VERSION "12.2.7"

NS_ :

BS_:

BU_: ACM ADAS_Body APM ASU_Gateway BCM BCM_BPM CCU_F CCU_R DUMMY_BCM_BPM ETG LDM_L LDM_R OCS_P PSM_D SRR_RR_M SHVU_F SHVU_R TRM USS_F USS_R XGW_Body

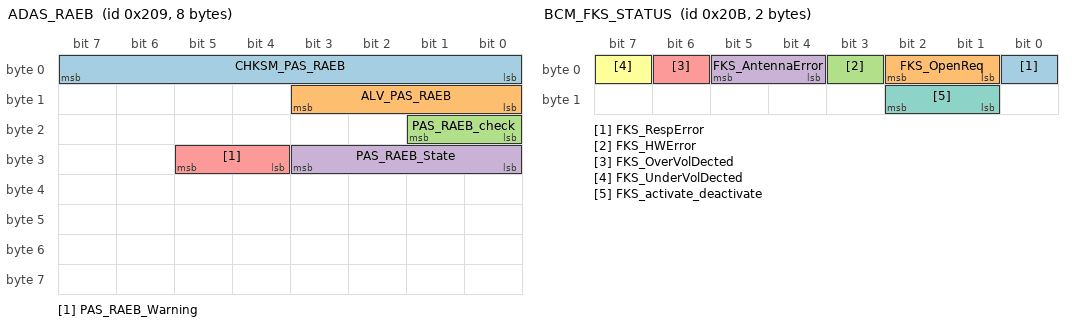
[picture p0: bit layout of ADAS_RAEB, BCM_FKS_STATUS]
BO_ 521 ADAS_RAEB: 8 XGW_Body
 SG_ CHKSM_PAS_RAEB : 7|8@0+ (1,0) [0|255] ""  ACM
 SG_ ALV_PAS_RAEB : 11|4@0+ (1,0) [0|14] ""  ACM
 SG_ PAS_RAEB_check : 17|2@0+ (1,0) [0|3] ""  ACM
 SG_ PAS_RAEB_State : 27|4@0+ (1,0) [0|15] ""  ACM
 SG_ PAS_RAEB_Warning : 29|2@0+ (1,0) [0|3] ""  ACM

BO_ 522 ETG_STATUS: 8 ETG
 SG_ ETG_Lift_Gate_Status : 2|3@0+ (1,0) [0|7] "-"  BCM,XGW_Body
 SG_ ETG_Power_Latch_Status : 5|3@0+ (1,0) [0|7] "-"  BCM,XGW_Body
 SG_ ETG_Latch_Segment : 7|2@0+ (1,0) [0|3] ""  BCM,XGW_Body
 SG_ ETG_Opening_Percentage : 15|8@0+ (1,0) [0|100] "%"  BCM,XGW_Body
 SG_ ETG_DSW_Status : 16|1@0+ (1,0) [0|1] ""  BCM,XGW_Body
 SG_ ETG_GSW_Status : 17|1@0+ (1,0) [0|1] ""  BCM,XGW_Body
 SG_ ETG_LTS_Status : 18|1@0+ (1,0) [0|1] "-"  BCM,XGW_Body
 SG_ ETG_RTS_Status : 19|1@0+ (1,0) [0|1] "-"  BCM,XGW_Body
 SG_ ETG_HAL_Status : 20|1@0+ (1,0) [0|1] "-"  BCM,XGW_Body
 SG_ ETG_FUL_Status : 21|1@0+ (1,0) [0|1] "-"  BCM,XGW_Body
 SG_ ETG_AJR_Status : 22|1@0+ (1,0) [0|1] ""  BCM,XGW_Body
 SG_ ETG_NTL_Status : 23|1@0+ (1,0) [0|1] "-"  BCM,XGW_Body
 SG_ ETG_ERR_Voltage : 25|2@0+ (1,0) [0|3] "-"  BCM,XGW_Body
 SG_ ETG_ERR_Left_Motor : 27|2@0+ (1,0) [0|3] ""  BCM,XGW_Body
 SG_ ETG_ERR_Right_Motor : 29|2@0+ (1,0) [0|3] "-"  BCM,XGW_Body
 SG_ ETG_ERR_Latch : 31|2@0+ (1,0) [0|3] "-"  BCM,XGW_Body
 SG_ ETG_ERR_Hall : 33|2@0+ (1,0) [0|3] ""  BCM,XGW_Body
 SG_ ETG_Lift_Motor_Stall : 34|1@0+ (1,0) [0|1] ""  BCM,XGW_Body
 SG_ ETG_Lift_Motor_AntiPinch : 35|1@0+ (1,0) [0|1] "-"  BCM,XGW_Body
 SG_ ETG_Lift_Motor_Thermal : 36|1@0+ (1,0) [0|1] ""  BCM,XGW_Body
 SG_ ETG_Power_Latch_Thermal : 37|1@0+ (1,0) [0|1] "-"  BCM,XGW_Body
 SG_ ETG_Abuse_Protection : 38|1@0+ (1,0) [0|1] ""  BCM,XGW_Body

BO_ 523 BCM_FKS_STATUS: 2 BCM
 SG_ FKS_RespError : 0|1@0+ (1,0) [0|1] "-"  XGW_Body
 SG_ FKS_OpenReq : 2|2@0+ (1,0) [0|3] ""  XGW_Body
 SG_ FKS_HWError : 3|1@0+ (1,0) [0|1] "-"  XGW_Body
 SG_ FKS_AntennaError : 5|2@0+ (1,0) [0|3] "-"  XGW_Body
 SG_ FKS_OverVolDected : 6|1@0+ (1,0) [0|1] "-"  XGW_Body
 SG_ FKS_UnderVolDected : 7|1@0+ (1,0) [0|1] "-"  XGW_Body
 SG_ FKS_activate_deactivate : 10|2@0+ (1,0) [0|3] "-"  XGW_Body

BO_ 524 IC_ODO: 8 XGW_Body
 SG_ CHKSM_IC_ODO : 7|8@0+ (1,0) [0|255] ""  ACM,ASU_Gateway,BCM,CCU_R,LDM_L,LDM_R,OCS_P,PSM_D,SHVU_F,SHVU_R,USS_F,USS_R
 SG_ ALIV_IC_ODO : 11|4@0+ (1,0) [0|14] ""  ACM,ASU_Gateway,BCM,CCU_R,LDM_L,LDM_R,OCS_P,PSM_D,SHVU_F,SHVU_R,USS_F,USS_R
 SG_ MHU_Odometer_IC : 23|20@0+ (1,0) [0|999999] "km"  ACM,ASU_Gateway,BCM,CCU_R,LDM_L,LDM_R,OCS_P,PSM_D,SHVU_F,SHVU_R,SRR_RR_M,USS_F,USS_R

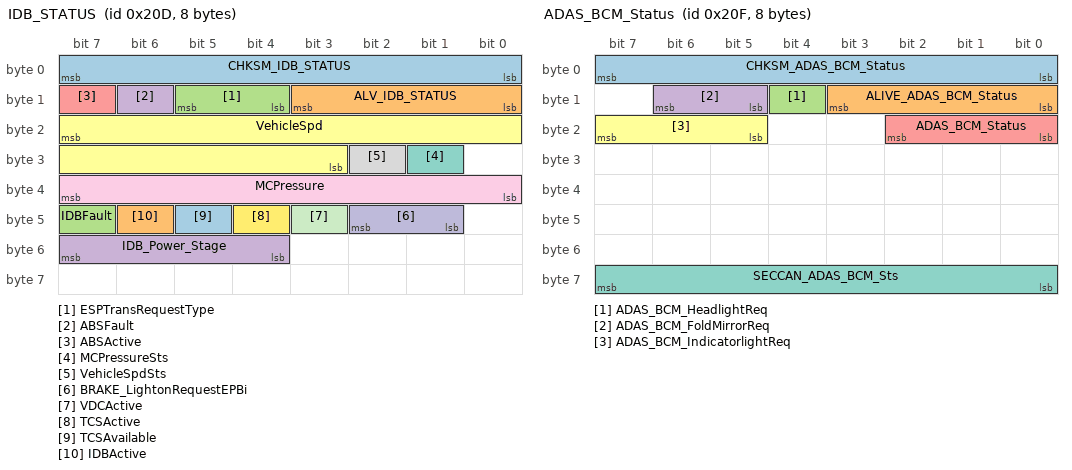
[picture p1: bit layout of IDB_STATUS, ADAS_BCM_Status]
BO_ 525 IDB_STATUS: 8 XGW_Body
 SG_ CHKSM_IDB_STATUS : 7|8@0+ (1,0) [0|255] ""  ACM,APM,ASU_Gateway,BCM,CCU_F,CCU_R,ETG,LDM_L,LDM_R,OCS_P,PSM_D,SHVU_F,SHVU_R,SRR_RR_M,TRM,USS_F,USS_R
 SG_ ALV_IDB_STATUS : 11|4@0+ (1,0) [0|14] ""  ACM,APM,ASU_Gateway,BCM,CCU_F,CCU_R,ETG,LDM_L,LDM_R,OCS_P,PSM_D,SHVU_F,SHVU_R,SRR_RR_M,TRM,USS_F,USS_R
 SG_ ESPTransRequestType : 13|2@0+ (1,0) [0|3] ""  APM,CCU_F,CCU_R,ETG,TRM
 SG_ ABSFault : 14|1@0+ (1,0) [0|1] ""  ACM,APM,CCU_F,CCU_R,ETG,TRM
 SG_ ABSActive : 15|1@0+ (1,0) [0|1] ""  ACM,APM,CCU_F,CCU_R,ETG,TRM
 SG_ VehicleSpd : 23|13@0+ (0.05625,0) [0|300] "km/h"  ACM,APM,ASU_Gateway,BCM,BCM_BPM,CCU_F,CCU_R,ETG,LDM_L,LDM_R,OCS_P,PSM_D,SHVU_F,SHVU_R,SRR_RR_M,TRM,USS_F,USS_R
 SG_ MCPressureSts : 25|1@0+ (1,0) [0|1] ""  APM,ASU_Gateway,CCU_F,CCU_R,ETG,TRM
 SG_ VehicleSpdSts : 26|1@0+ (1,0) [0|1] ""  ACM,APM,ASU_Gateway,BCM,CCU_F,CCU_R,ETG,LDM_L,LDM_R,OCS_P,PSM_D,SHVU_F,SHVU_R,SRR_RR_M,TRM,USS_F,USS_R
 SG_ MCPressure : 39|8@0+ (2,-42.5) [-42.5|465.5] "bar"  APM,ASU_Gateway,CCU_F,CCU_R,ETG,TRM
 SG_ BRAKE_LightonRequestEPBi : 42|2@0+ (1,0) [0|3] ""  APM,BCM,CCU_F,CCU_R,ETG,TRM
 SG_ VDCActive : 43|1@0+ (1,0) [0|1] ""  APM,CCU_F,CCU_R,ETG,TRM
 SG_ TCSActive : 44|1@0+ (1,0) [0|1] ""  ACM,APM,CCU_F,CCU_R,ETG,TRM
 SG_ TCSAvailable : 45|1@0+ (1,0) [0|1] ""  ACM,APM,CCU_F,CCU_R,ETG,TRM
 SG_ IDBActive : 46|1@0+ (1,0) [0|1] ""  ACM,APM,CCU_F,CCU_R,ETG,TRM
 SG_ IDBFault : 47|1@0+ (1,0) [0|1] ""  ACM,APM,CCU_F,CCU_R,ETG,TRM
 SG_ IDB_Power_Stage : 55|4@0+ (1,0) [0|15] ""  APM,CCU_F,CCU_R,ETG,TRM

BO_ 527 ADAS_BCM_Status: 8 XGW_Body
  SG_ CHKSM_ADAS_BCM_Status : 7|8@0+ (1,0) [0|255] ""  BCM
  SG_ ALIVE_ADAS_BCM_Status : 11|4@0+ (1,0) [0|14] ""  BCM
  SG_ ADAS_BCM_HeadlightReq : 12|1@0+ (1,0) [0|1] ""  BCM
  SG_ ADAS_BCM_FoldMirrorReq : 14|2@0+ (1,0) [0|3] ""  BCM
  SG_ ADAS_BCM_Status : 18|3@0+ (1,0) [0|7] ""  BCM
  SG_ ADAS_BCM_IndicatorlightReq : 23|3@0+ (1,0) [0|7] ""  BCM
  SG_ SECCAN_ADAS_BCM_Sts : 63|8@0+ (1,0) [0|255] ""  BCM

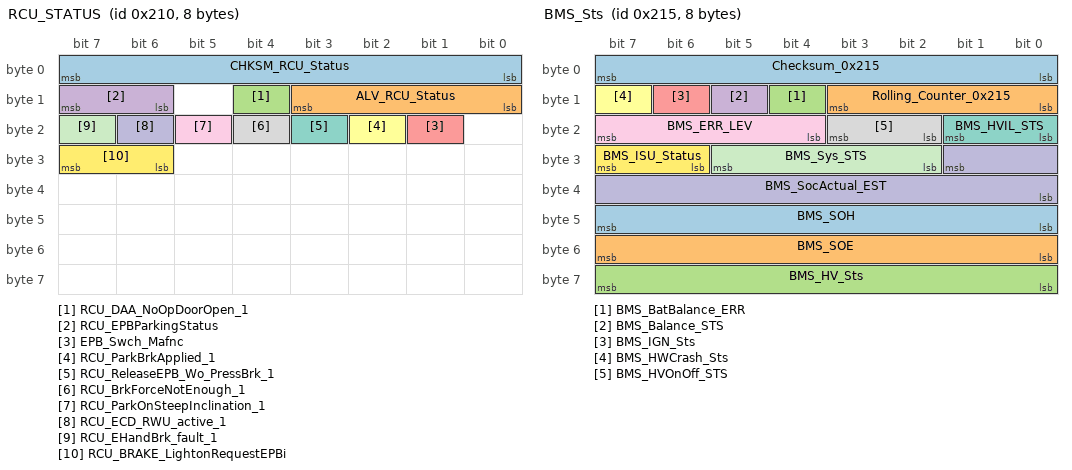
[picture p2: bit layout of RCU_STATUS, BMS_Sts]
BO_ 528 RCU_STATUS: 8 XGW_Body
 SG_ CHKSM_RCU_Status : 7|8@0+ (1,0) [0|255] ""  BCM
 SG_ ALV_RCU_Status : 11|4@0+ (1,0) [0|14] ""  BCM
 SG_ RCU_DAA_NoOpDoorOpen_1 : 12|1@0+ (1,0) [0|1] ""  BCM
 SG_ RCU_EPBParkingStatus : 15|2@0+ (1,0) [0|3] ""  BCM
 SG_ EPB_Swch_Mafnc : 17|1@0+ (1,0) [0|1] ""  BCM
 SG_ RCU_ParkBrkApplied_1 : 18|1@0+ (1,0) [0|1] ""  BCM
 SG_ RCU_ReleaseEPB_Wo_PressBrk_1 : 19|1@0+ (1,0) [0|1] ""  BCM
 SG_ RCU_BrkForceNotEnough_1 : 20|1@0+ (1,0) [0|1] ""  BCM
 SG_ RCU_ParkOnSteepInclination_1 : 21|1@0+ (1,0) [0|1] ""  BCM
 SG_ RCU_ECD_RWU_active_1 : 22|1@0+ (1,0) [0|1] ""  BCM
 SG_ RCU_EHandBrk_fault_1 : 23|1@0+ (1,0) [0|1] ""  BCM
 SG_ RCU_BRAKE_LightonRequestEPBi : 31|2@0+ (1,0) [0|3] ""  BCM

BO_ 533 BMS_Sts: 8 XGW_Body
 SG_ Checksum_0x215 : 7|8@0+ (1,0) [0|255] ""  BCM,SRR_RR_M
 SG_ Rolling_Counter_0x215 : 11|4@0+ (1,0) [0|14] ""  BCM,SRR_RR_M
 SG_ BMS_BatBalance_ERR : 12|1@0+ (1,0) [0|1] "" Vector__XXX
 SG_ BMS_Balance_STS : 13|1@0+ (1,0) [0|1] "" Vector__XXX
 SG_ BMS_IGN_Sts : 14|1@0+ (1,0) [0|1] "" Vector__XXX
 SG_ BMS_HWCrash_Sts : 15|1@0+ (1,0) [0|1] "" Vector__XXX
 SG_ BMS_HVIL_STS : 17|2@0+ (1,0) [0|3] "" Vector__XXX
 SG_ BMS_HVOnOff_STS : 19|2@0+ (1,0) [0|3] "" SRR_RR_M,BCM
 SG_ BMS_ERR_LEV : 23|4@0+ (1,0) [0|7] "-" Vector__XXX
 SG_ BMS_SocActual_EST : 25|10@0+ (0.1,0) [0|100] "%"  BCM
 SG_ BMS_Sys_STS : 29|4@0+ (1,0) [0|15] "" Vector__XXX
 SG_ BMS_ISU_Status : 31|2@0+ (1,0) [0|3] "" Vector__XXX
 SG_ BMS_SOH : 47|8@0+ (0.5,0) [0|100] "%" Vector__XXX
 SG_ BMS_SOE : 55|8@0+ (0.5,0) [0|100] "%" Vector__XXX
 SG_ BMS_HV_Sts : 63|8@0+ (1,0) [0|255] "" SRR_RR_M

BO_ 537 VCU_PTControl: 8 XGW_Body
 SG_ CHSKM_VCU_PTControl : 7|8@0+ (1,0) [0|255] ""  BCM
 SG_ ALV_VCU_PTControl : 11|4@0+ (1,0) [0|14] ""  BCM
 SG_ VCU_ChargeAllow : 54|1@0+ (1,0) [0|1] ""  BCM

BO_ 540 FCAM_AEB: 8 XGW_Body
 SG_ FCAM_AEB_Warning : 13|2@0+ (1,0) [0|3] ""  ACM
 SG_ FCAM_AEB_State : 15|2@0+ (1,0) [0|3] ""  ACM
 SG_ FCAM_AEB_check : 19|2@0+ (1,0) [0|3] ""  ACM

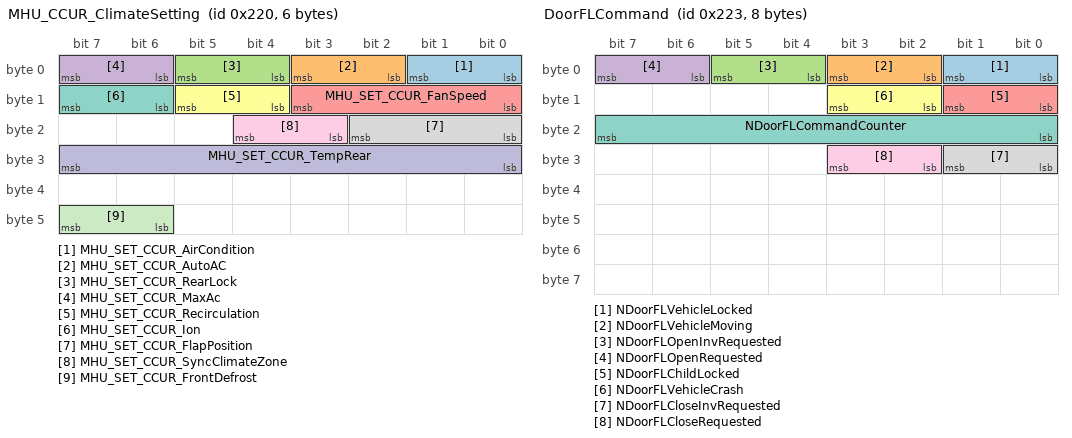
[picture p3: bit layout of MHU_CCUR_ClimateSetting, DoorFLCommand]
BO_ 544 MHU_CCUR_ClimateSetting: 6 XGW_Body
 SG_ MHU_SET_CCUR_AirCondition : 1|2@0+ (1,0) [0|3] "-"  CCU_F
 SG_ MHU_SET_CCUR_AutoAC : 3|2@0+ (1,0) [0|3] "-"  CCU_F
 SG_ MHU_SET_CCUR_RearLock : 5|2@0+ (1,0) [0|3] "-"  CCU_F
 SG_ MHU_SET_CCUR_MaxAc : 7|2@0+ (1,0) [0|3] ""  CCU_F
 SG_ MHU_SET_CCUR_FanSpeed : 11|4@0+ (1,0) [0|7] "-"  CCU_F
 SG_ MHU_SET_CCUR_Recirculation : 13|2@0+ (1,0) [0|3] "-"  CCU_F
 SG_ MHU_SET_CCUR_Ion : 15|2@0+ (1,0) [0|3] ""  CCU_F
 SG_ MHU_SET_CCUR_FlapPosition : 18|3@0+ (1,0) [0|7] "-"  CCU_F
 SG_ MHU_SET_CCUR_SyncClimateZone : 20|2@0+ (1,0) [0|3] "-"  CCU_F
 SG_ MHU_SET_CCUR_TempRear : 31|8@0+ (0.5,0) [16|32] "Degree C"  CCU_F
 SG_ MHU_SET_CCUR_FrontDefrost : 47|2@0+ (1,0) [0|3] ""  CCU_F

BO_ 545 CCUR_ClimateSetting: 8 CCU_R
 SG_ CCUR_Req_AirCondition : 1|2@0+ (1,0) [0|3] ""  CCU_F,XGW_Body
 SG_ CCUR_AirDistribFlapActPos : 15|8@0+ (0.5,0) [0|100] ""  CCU_F
 SG_ CCUR_TempFlapActPos : 23|8@0+ (0.5,0) [0|100] ""  CCU_F
 SG_ SECCAN_CCUR : 63|8@0+ (1,0) [0|255] ""  CCU_F,XGW_Body

BO_ 546 CCUF_ClimateSetting: 8 CCU_F
 SG_ FRONT_SET_Rear_AirCondition : 1|2@0+ (1,0) [0|3] ""  CCU_R,XGW_Body
 SG_ SECCAN_CCUF : 63|8@0+ (1,0) [0|255] ""  CCU_R,XGW_Body

BO_ 547 DoorFLCommand: 8 BCM
 SG_ NDoorFLVehicleLocked : 1|2@0+ (1,0) [0|3] "" Vector__XXX
 SG_ NDoorFLVehicleMoving : 3|2@0+ (1,0) [0|3] "" Vector__XXX
 SG_ NDoorFLOpenInvRequested : 5|2@0+ (1,0) [0|3] ""  XGW_Body
 SG_ NDoorFLOpenRequested : 7|2@0+ (1,0) [0|3] ""  XGW_Body
 SG_ NDoorFLChildLocked : 9|2@0+ (1,0) [0|3] "" Vector__XXX
 SG_ NDoorFLVehicleCrash : 11|2@0+ (1,0) [0|3] "" Vector__XXX
 SG_ NDoorFLCommandCounter : 23|8@0+ (1,0) [0|255] ""  XGW_Body
 SG_ NDoorFLCloseInvRequested : 25|2@0+ (1,0) [0|3] ""  XGW_Body
 SG_ NDoorFLCloseRequested : 27|2@0+ (1,0) [0|3] ""  XGW_Body

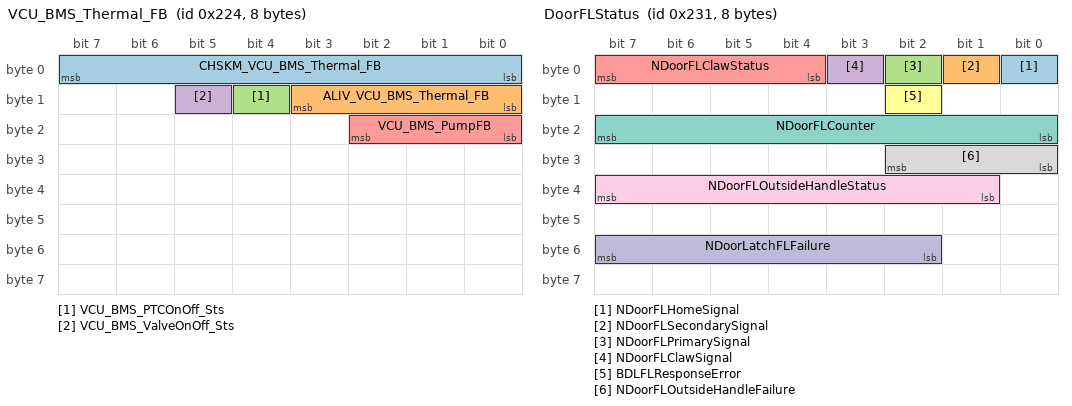
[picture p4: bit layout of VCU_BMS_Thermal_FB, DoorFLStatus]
BO_ 548 VCU_BMS_Thermal_FB: 8 XGW_Body
 SG_ CHSKM_VCU_BMS_Thermal_FB : 7|8@0+ (1,0) [0|255] ""  BCM
 SG_ ALIV_VCU_BMS_Thermal_FB : 11|4@0+ (1,0) [0|14] ""  BCM
 SG_ VCU_BMS_PTCOnOff_Sts : 12|1@0+ (1,0) [0|1] ""  BCM
 SG_ VCU_BMS_ValveOnOff_Sts : 13|1@0+ (1,0) [0|1] ""  BCM
 SG_ VCU_BMS_PumpFB : 18|3@0+ (1,0) [0|3] ""  BCM

BO_ 561 DoorFLStatus: 8 XGW_Body
 SG_ NDoorFLHomeSignal : 0|1@0+ (1,0) [0|1] ""  BCM
 SG_ NDoorFLSecondarySignal : 1|1@0+ (1,0) [0|1] ""  BCM
 SG_ NDoorFLPrimarySignal : 2|1@0+ (1,0) [0|1] ""  BCM
 SG_ NDoorFLClawSignal : 3|1@0+ (1,0) [0|1] ""  BCM
 SG_ NDoorFLClawStatus : 7|4@0+ (1,0) [0|15] ""  BCM
 SG_ BDLFLResponseError : 10|1@0+ (1,0) [0|1] ""  BCM
 SG_ NDoorFLCounter : 23|8@0+ (1,0) [0|255] ""  BCM
 SG_ NDoorFLOutsideHandleFailure : 26|3@0+ (1,0) [0|7] ""  BCM
 SG_ NDoorFLOutsideHandleStatus : 39|7@0+ (1,0) [0|127] ""  BCM
 SG_ NDoorLatchFLFailure : 55|6@0+ (1,0) [0|63] ""  BCM

BO_ 565 TRM_STATUS: 3 TRM
 SG_ CHKSM_TRM_STATUS : 7|8@0+ (1,0) [0|255] ""  XGW_Body,USS_F,USS_R
 SG_ ALIVE_TRM_STATUS : 11|4@0+ (1,0) [0|14] ""  XGW_Body,USS_F,USS_R
 SG_ TowingDetected : 21|2@0+ (1,0) [0|3] ""  XGW_Body,USS_F,USS_R
 SG_ TrailerDetected : 23|2@0+ (1,0) [0|3] ""  ASU_Gateway,XGW_Body,USS_F,USS_R

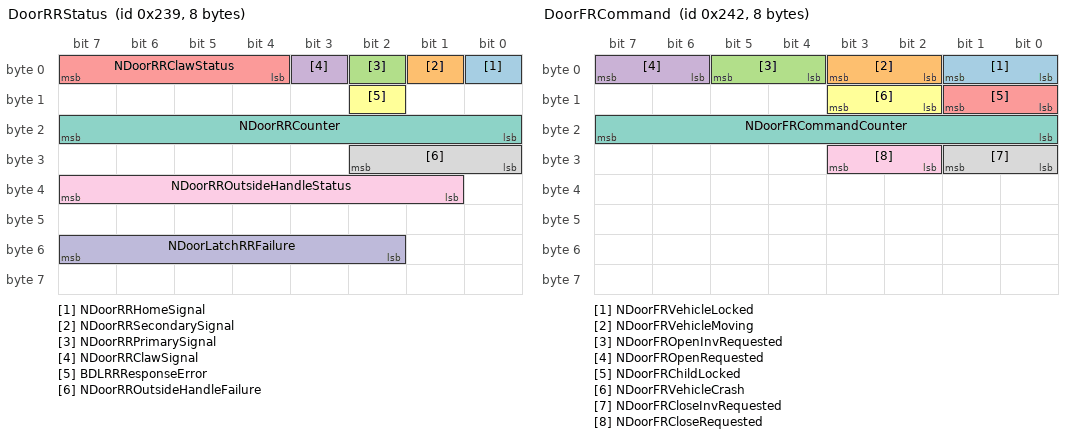
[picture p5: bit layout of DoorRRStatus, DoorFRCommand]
BO_ 569 DoorRRStatus: 8 XGW_Body
 SG_ NDoorRRHomeSignal : 0|1@0+ (1,0) [0|1] ""  BCM
 SG_ NDoorRRSecondarySignal : 1|1@0+ (1,0) [0|1] ""  BCM
 SG_ NDoorRRPrimarySignal : 2|1@0+ (1,0) [0|1] ""  BCM
 SG_ NDoorRRClawSignal : 3|1@0+ (1,0) [0|1] ""  BCM
 SG_ NDoorRRClawStatus : 7|4@0+ (1,0) [0|15] ""  BCM
 SG_ BDLRRResponseError : 10|1@0+ (1,0) [0|1] ""  BCM
 SG_ NDoorRRCounter : 23|8@0+ (1,0) [0|255] ""  BCM
 SG_ NDoorRROutsideHandleFailure : 26|3@0+ (1,0) [0|7] ""  BCM
 SG_ NDoorRROutsideHandleStatus : 39|7@0+ (1,0) [0|127] ""  BCM
 SG_ NDoorLatchRRFailure : 55|6@0+ (1,0) [0|63] ""  BCM

BO_ 570 IDB_WheelSts_FR: 8 XGW_Body
 SG_ IDB_WheelDirection_FR : 13|2@0+ (1,0) [0|3] ""  USS_F,USS_R
 SG_ IDB_WheelDirection_FL : 15|2@0+ (1,0) [0|3] ""  USS_F,USS_R

BO_ 571 IDB_WheelSts_RR: 8 XGW_Body
 SG_ IDB_WheelDirection_RR : 13|2@0+ (1,0) [0|3] ""  USS_F,USS_R
 SG_ IDB_WheelDirection_RL : 15|2@0+ (1,0) [0|3] ""  USS_F,USS_R

BO_ 578 DoorFRCommand: 8 BCM
 SG_ NDoorFRVehicleLocked : 1|2@0+ (1,0) [0|3] "" Vector__XXX
 SG_ NDoorFRVehicleMoving : 3|2@0+ (1,0) [0|3] "" Vector__XXX
 SG_ NDoorFROpenInvRequested : 5|2@0+ (1,0) [0|3] ""  XGW_Body
 SG_ NDoorFROpenRequested : 7|2@0+ (1,0) [0|3] ""  XGW_Body
 SG_ NDoorFRChildLocked : 9|2@0+ (1,0) [0|3] "" Vector__XXX
 SG_ NDoorFRVehicleCrash : 11|2@0+ (1,0) [0|3] "" Vector__XXX
 SG_ NDoorFRCommandCounter : 23|8@0+ (1,0) [0|255] ""  XGW_Body
 SG_ NDoorFRCloseInvRequested : 25|2@0+ (1,0) [0|3] ""  XGW_Body
 SG_ NDoorFRCloseRequested : 27|2@0+ (1,0) [0|3] ""  XGW_Body

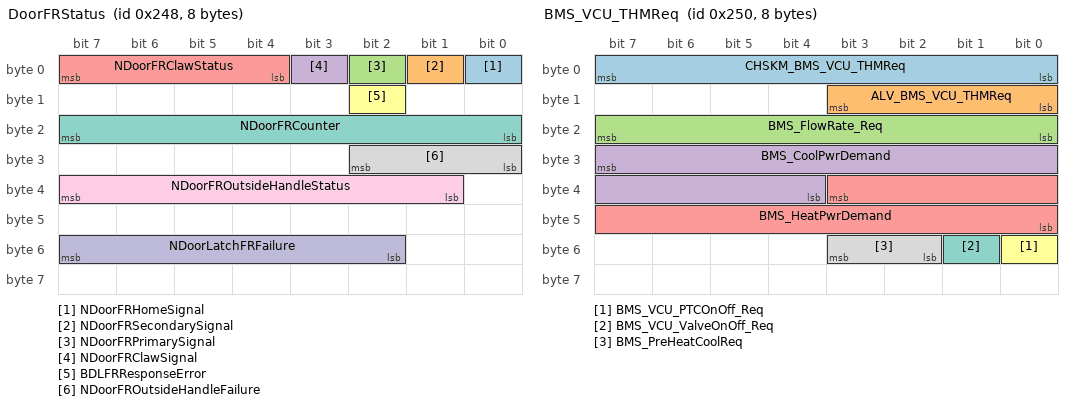
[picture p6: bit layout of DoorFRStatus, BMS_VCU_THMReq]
BO_ 584 DoorFRStatus: 8 XGW_Body
 SG_ NDoorFRHomeSignal : 0|1@0+ (1,0) [0|1] ""  BCM
 SG_ NDoorFRSecondarySignal : 1|1@0+ (1,0) [0|1] ""  BCM
 SG_ NDoorFRPrimarySignal : 2|1@0+ (1,0) [0|1] ""  BCM
 SG_ NDoorFRClawSignal : 3|1@0+ (1,0) [0|1] ""  BCM
 SG_ NDoorFRClawStatus : 7|4@0+ (1,0) [0|15] ""  BCM
 SG_ BDLFRResponseError : 10|1@0+ (1,0) [0|1] ""  BCM
 SG_ NDoorFRCounter : 23|8@0+ (1,0) [0|255] ""  BCM
 SG_ NDoorFROutsideHandleFailure : 26|3@0+ (1,0) [0|7] ""  BCM
 SG_ NDoorFROutsideHandleStatus : 39|7@0+ (1,0) [0|127] ""  BCM
 SG_ NDoorLatchFRFailure : 55|6@0+ (1,0) [0|63] ""  BCM

BO_ 592 BMS_VCU_THMReq: 8 XGW_Body
 SG_ CHSKM_BMS_VCU_THMReq : 7|8@0+ (1,0) [0|255] ""  BCM
 SG_ ALV_BMS_VCU_THMReq : 11|4@0+ (1,0) [0|14] ""  BCM
 SG_ BMS_FlowRate_Req : 23|8@0+ (1,0) [0|50] "l/min"  BCM
 SG_ BMS_CoolPwrDemand : 31|12@0+ (0.1,0) [0|10] "kW"  BCM
 SG_ BMS_HeatPwrDemand : 35|12@0+ (0.1,0) [0|10] "kW"  BCM
 SG_ BMS_VCU_PTCOnOff_Req : 48|1@0+ (1,0) [0|1] ""  BCM
 SG_ BMS_VCU_ValveOnOff_Req : 49|1@0+ (1,0) [0|1] ""  BCM
 SG_ BMS_PreHeatCoolReq : 51|2@0+ (1,0) [0|3] ""  BCM

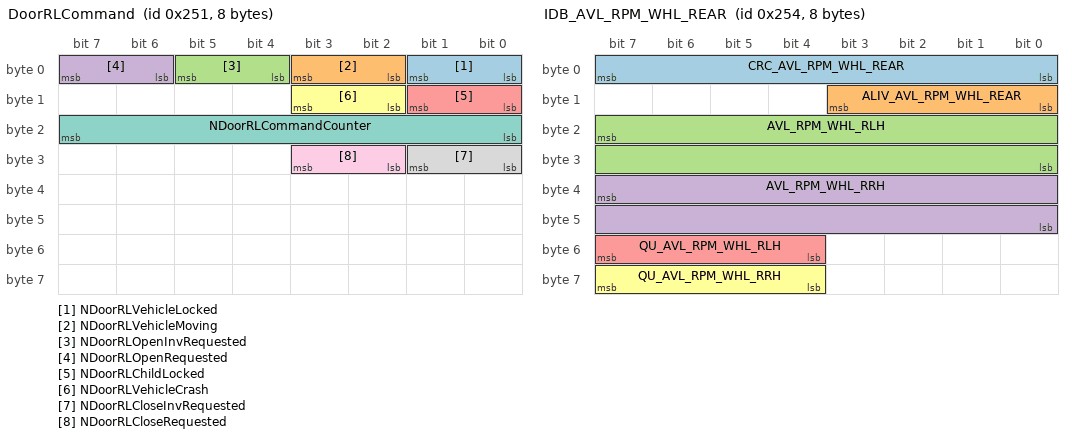
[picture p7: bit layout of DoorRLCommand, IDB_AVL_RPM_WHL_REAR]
BO_ 593 DoorRLCommand: 8 BCM
 SG_ NDoorRLVehicleLocked : 1|2@0+ (1,0) [0|3] "" Vector__XXX
 SG_ NDoorRLVehicleMoving : 3|2@0+ (1,0) [0|3] "" Vector__XXX
 SG_ NDoorRLOpenInvRequested : 5|2@0+ (1,0) [0|3] ""  XGW_Body
 SG_ NDoorRLOpenRequested : 7|2@0+ (1,0) [0|3] ""  XGW_Body
 SG_ NDoorRLChildLocked : 9|2@0+ (1,0) [0|3] "" Vector__XXX
 SG_ NDoorRLVehicleCrash : 11|2@0+ (1,0) [0|3] "" Vector__XXX
 SG_ NDoorRLCommandCounter : 23|8@0+ (1,0) [0|255] ""  XGW_Body
 SG_ NDoorRLCloseInvRequested : 25|2@0+ (1,0) [0|3] ""  XGW_Body
 SG_ NDoorRLCloseRequested : 27|2@0+ (1,0) [0|3] ""  XGW_Body

BO_ 596 IDB_AVL_RPM_WHL_REAR: 8 XGW_Body
 SG_ CRC_AVL_RPM_WHL_REAR : 7|8@0+ (1,0) [0|255] ""  LDM_L,LDM_R
 SG_ ALIV_AVL_RPM_WHL_REAR : 11|4@0+ (1,0) [0|14] ""  LDM_L,LDM_R
 SG_ AVL_RPM_WHL_RLH : 23|16@0+ (0.0156,-511.9844) [-400|400] "rad/s"  LDM_L,LDM_R
 SG_ AVL_RPM_WHL_RRH : 39|16@0+ (0.0156,-511.9844) [-400|400] "rad/s"  LDM_L,LDM_R
 SG_ QU_AVL_RPM_WHL_RLH : 55|4@0+ (1,0) [0|15] "Bit"  LDM_L,LDM_R
 SG_ QU_AVL_RPM_WHL_RRH : 63|4@0+ (1,0) [0|15] "Bit"  LDM_L,LDM_R

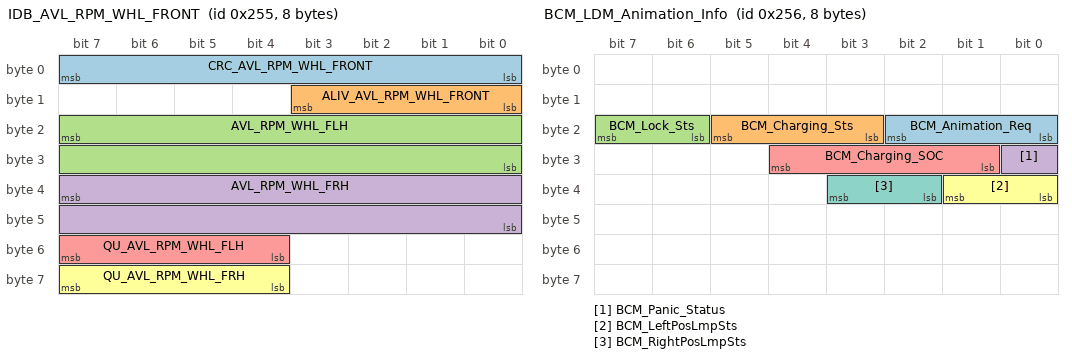
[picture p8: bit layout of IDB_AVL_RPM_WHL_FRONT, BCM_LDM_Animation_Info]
BO_ 597 IDB_AVL_RPM_WHL_FRONT: 8 XGW_Body
 SG_ CRC_AVL_RPM_WHL_FRONT : 7|8@0+ (1,0) [0|255] ""  LDM_L,LDM_R
 SG_ ALIV_AVL_RPM_WHL_FRONT : 11|4@0+ (1,0) [0|14] ""  LDM_L,LDM_R
 SG_ AVL_RPM_WHL_FLH : 23|16@0+ (0.0156,-511.9844) [-400|400] "rad/s"  LDM_L,LDM_R
 SG_ AVL_RPM_WHL_FRH : 39|16@0+ (0.0156,-511.9844) [-400|400] "rad/s"  LDM_L,LDM_R
 SG_ QU_AVL_RPM_WHL_FLH : 55|4@0+ (1,0) [0|15] "Bit"  LDM_L,LDM_R
 SG_ QU_AVL_RPM_WHL_FRH : 63|4@0+ (1,0) [0|15] "Bit"  LDM_L,LDM_R

BO_ 598 BCM_LDM_Animation_Info: 8 BCM
 SG_ BCM_Animation_Req : 18|3@0+ (1,0) [0|7] ""  LDM_L,LDM_R
 SG_ BCM_Charging_Sts : 21|3@0+ (1,0) [0|7] ""  LDM_L,LDM_R
 SG_ BCM_Lock_Sts : 23|2@0+ (1,0) [0|3] ""  LDM_L,LDM_R
 SG_ BCM_Panic_Status : 24|1@0+ (1,0) [0|1] ""  LDM_L,LDM_R
 SG_ BCM_Charging_SOC : 28|4@0+ (1,0) [0|15] ""  LDM_L,LDM_R
 SG_ BCM_LeftPosLmpSts : 33|2@0+ (1,0) [0|3] ""  LDM_L
 SG_ BCM_RightPosLmpSts : 35|2@0+ (1,0) [0|3] ""  LDM_R

BO_ 618 ST_LCS_VEH: 3 ASU_Gateway
 SG_ ALIV_ST_LCS_VEH : 0|4@1+ (1,0) [0|14] ""  BCM
 SG_ ST_ECU_ST_LCS_VEH : 4|4@1+ (1,0) [0|15] ""  BCM
 SG_ QU_FN_LCS_VEH : 8|12@1+ (1,0) [0|0] ""  BCM

BO_ 619 Frm_TgtValA: 8 XGW_Body
 SG_ Sig_TgtVer_LR : 7|10@0+ (1,0) [0|1000] "deg"  BCM

BO_ 620 Frm_TgtValB: 8 XGW_Body
 SG_ Sig_SPVer_L : 7|2@0+ (1,0) [0|3] ""  BCM
 SG_ Sig_SPVer_R : 9|2@0+ (1,0) [0|3] "deg"  BCM
 SG_ Sig_RefVer_LR : 11|2@0+ (1,0) [0|3] ""  BCM

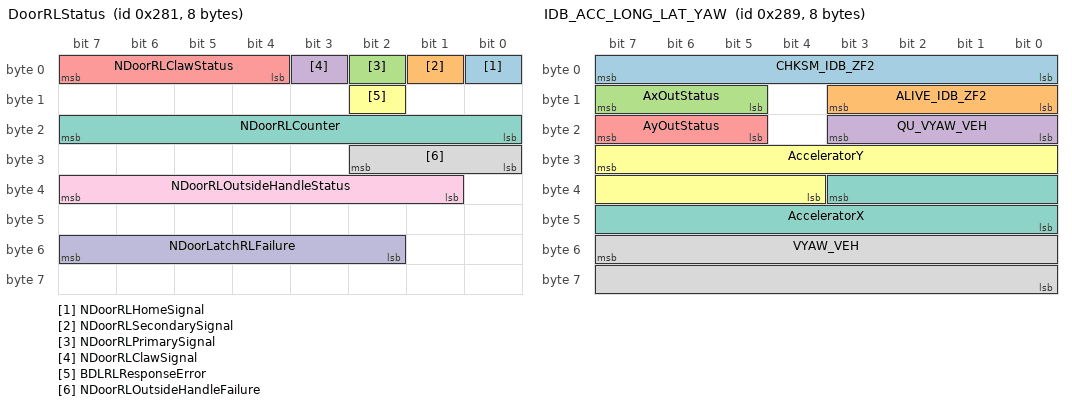
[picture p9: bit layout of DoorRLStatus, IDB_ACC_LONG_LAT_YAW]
BO_ 641 DoorRLStatus: 8 XGW_Body
 SG_ NDoorRLHomeSignal : 0|1@0+ (1,0) [0|1] ""  BCM
 SG_ NDoorRLSecondarySignal : 1|1@0+ (1,0) [0|1] ""  BCM
 SG_ NDoorRLPrimarySignal : 2|1@0+ (1,0) [0|1] ""  BCM
 SG_ NDoorRLClawSignal : 3|1@0+ (1,0) [0|1] ""  BCM
 SG_ NDoorRLClawStatus : 7|4@0+ (1,0) [0|15] ""  BCM
 SG_ BDLRLResponseError : 10|1@0+ (1,0) [0|1] ""  BCM
 SG_ NDoorRLCounter : 23|8@0+ (1,0) [0|255] ""  BCM
 SG_ NDoorRLOutsideHandleFailure : 26|3@0+ (1,0) [0|7] ""  BCM
 SG_ NDoorRLOutsideHandleStatus : 39|7@0+ (1,0) [0|127] ""  BCM
 SG_ NDoorLatchRLFailure : 55|6@0+ (1,0) [0|63] ""  BCM

BO_ 649 IDB_ACC_LONG_LAT_YAW: 8 XGW_Body
 SG_ CHKSM_IDB_ZF2 : 7|8@0+ (1,0) [0|255] ""  SRR_RR_M,LDM_L,LDM_R,ACM
 SG_ ALIVE_IDB_ZF2 : 11|4@0+ (1,0) [0|14] ""  SRR_RR_M,LDM_L,LDM_R,ACM
 SG_ AxOutStatus : 15|3@0+ (1,0) [0|7] ""  SRR_RR_M,LDM_L,LDM_R
 SG_ QU_VYAW_VEH : 19|4@0+ (1,0) [0|15] ""  SRR_RR_M,LDM_L,LDM_R,ACM
 SG_ AyOutStatus : 23|3@0+ (1,0) [0|7] ""  SRR_RR_M,LDM_L,LDM_R
 SG_ AcceleratorY : 31|12@0+ (0.02713,-21.5928) [-21.593|21.5928] "m/s^2"  SRR_RR_M,LDM_L,LDM_R,ACM
 SG_ AcceleratorX : 35|12@0+ (0.02713,-21.5928) [-21.593|21.5928] "m/s^2"  SRR_RR_M,LDM_L,LDM_R,ACM
 SG_ VYAW_VEH : 55|16@0+ (0.005,-163.84) [-163.84|163.83] "�/s"  SRR_RR_M,LDM_L,LDM_R,ACM

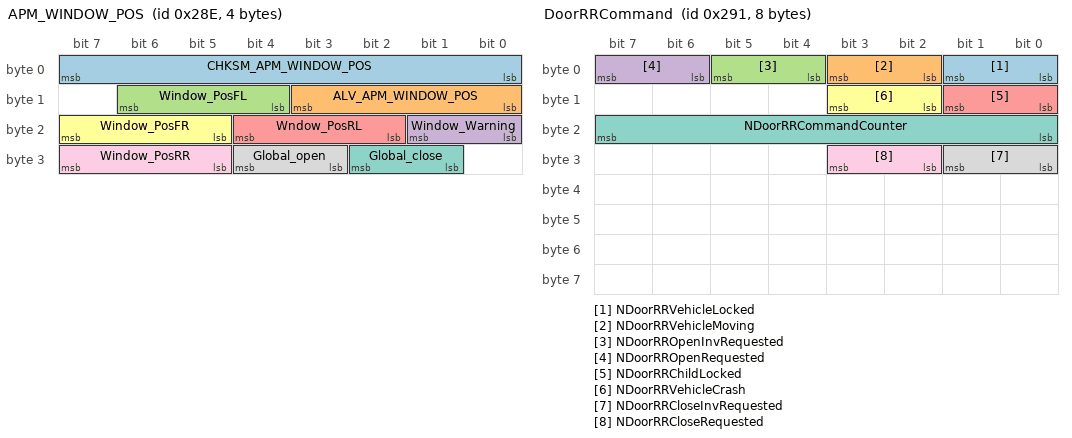
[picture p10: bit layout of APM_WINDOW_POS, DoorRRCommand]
BO_ 654 APM_WINDOW_POS: 4 APM
 SG_ CHKSM_APM_WINDOW_POS : 7|8@0+ (1,0) [0|255] ""  XGW_Body
 SG_ ALV_APM_WINDOW_POS : 11|4@0+ (1,0) [0|14] ""  XGW_Body
 SG_ Window_PosFL : 14|3@0+ (1,0) [0|7] "-"  XGW_Body
 SG_ Window_Warning : 17|2@0+ (1,0) [0|3] ""  XGW_Body
 SG_ Wndow_PosRL : 20|3@0+ (1,0) [0|7] ""  XGW_Body
 SG_ Window_PosFR : 23|3@0+ (1,0) [0|7] ""  XGW_Body
 SG_ Global_close : 26|2@0+ (1,0) [0|3] ""  XGW_Body
 SG_ Global_open : 28|2@0+ (1,0) [0|3] ""  XGW_Body
 SG_ Window_PosRR : 31|3@0+ (1,0) [0|7] "-"  XGW_Body

BO_ 657 DoorRRCommand: 8 BCM
 SG_ NDoorRRVehicleLocked : 1|2@0+ (1,0) [0|3] "" Vector__XXX
 SG_ NDoorRRVehicleMoving : 3|2@0+ (1,0) [0|3] "" Vector__XXX
 SG_ NDoorRROpenInvRequested : 5|2@0+ (1,0) [0|3] ""  XGW_Body
 SG_ NDoorRROpenRequested : 7|2@0+ (1,0) [0|3] ""  XGW_Body
 SG_ NDoorRRChildLocked : 9|2@0+ (1,0) [0|3] "" Vector__XXX
 SG_ NDoorRRVehicleCrash : 11|2@0+ (1,0) [0|3] "" Vector__XXX
 SG_ NDoorRRCommandCounter : 23|8@0+ (1,0) [0|255] ""  XGW_Body
 SG_ NDoorRRCloseInvRequested : 25|2@0+ (1,0) [0|3] ""  XGW_Body
 SG_ NDoorRRCloseRequested : 27|2@0+ (1,0) [0|3] ""  XGW_Body

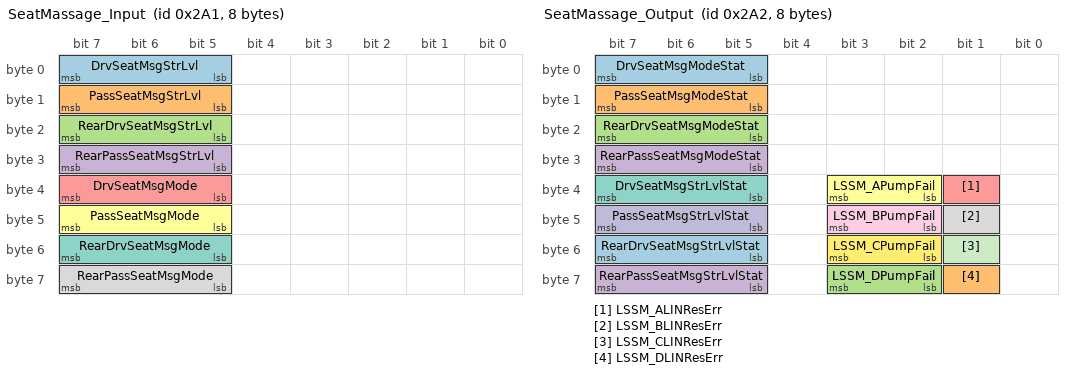
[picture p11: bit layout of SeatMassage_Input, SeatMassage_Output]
BO_ 673 SeatMassage_Input: 8 XGW_Body
 SG_ DrvSeatMsgStrLvl : 7|3@0+ (1,0) [0|7] ""  PSM_D
 SG_ PassSeatMsgStrLvl : 15|3@0+ (1,0) [0|7] ""  PSM_D
 SG_ RearDrvSeatMsgStrLvl : 23|3@0+ (1,0) [0|7] "-"  PSM_D
 SG_ RearPassSeatMsgStrLvl : 31|3@0+ (1,0) [0|7] ""  PSM_D
 SG_ DrvSeatMsgMode : 39|3@0+ (1,0) [0|7] ""  PSM_D
 SG_ PassSeatMsgMode : 47|3@0+ (1,0) [0|7] ""  PSM_D
 SG_ RearDrvSeatMsgMode : 55|3@0+ (1,0) [0|7] ""  PSM_D
 SG_ RearPassSeatMsgMode : 63|3@0+ (1,0) [0|7] "-"  PSM_D

BO_ 674 SeatMassage_Output: 8 PSM_D
 SG_ DrvSeatMsgModeStat : 7|3@0+ (1,0) [0|7] ""  XGW_Body
 SG_ PassSeatMsgModeStat : 15|3@0+ (1,0) [0|7] ""  XGW_Body
 SG_ RearDrvSeatMsgModeStat : 23|3@0+ (1,0) [0|7] ""  XGW_Body
 SG_ RearPassSeatMsgModeStat : 31|3@0+ (1,0) [0|7] ""  XGW_Body
 SG_ LSSM_ALINResErr : 33|1@0+ (1,0) [0|1] ""  XGW_Body
 SG_ LSSM_APumpFail : 35|2@0+ (1,0) [0|3] ""  XGW_Body
 SG_ DrvSeatMsgStrLvlStat : 39|3@0+ (1,0) [0|7] ""  XGW_Body
 SG_ LSSM_BLINResErr : 41|1@0+ (1,0) [0|1] ""  XGW_Body
 SG_ LSSM_BPumpFail : 43|2@0+ (1,0) [0|3] ""  XGW_Body
 SG_ PassSeatMsgStrLvlStat : 47|3@0+ (1,0) [0|7] "-"  XGW_Body
 SG_ LSSM_CLINResErr : 49|1@0+ (1,0) [0|1] ""  XGW_Body
 SG_ LSSM_CPumpFail : 51|2@0+ (1,0) [0|3] "-"  XGW_Body
 SG_ RearDrvSeatMsgStrLvlStat : 55|3@0+ (1,0) [0|7] "-"  XGW_Body
 SG_ LSSM_DLINResErr : 57|1@0+ (1,0) [0|1] ""  XGW_Body
 SG_ LSSM_DPumpFail : 59|2@0+ (1,0) [0|3] "-"  XGW_Body
 SG_ RearPassSeatMsgStrLvlStat : 63|3@0+ (1,0) [0|7] ""  XGW_Body

BO_ 676 SVC_EHC_EHC_2: 8 ASU_Gateway
 SG_ ID2 M : 0|8@1+ (1,0) [0|0] ""  BCM,XGW_Body
 SG_ ECU_ID_WUPREG m39 : 8|8@1+ (1,0) [0|127] ""  BCM,XGW_Body
 SG_ ID_FN_INQY m1 : 8|16@1+ (1,0) [0|0] ""  BCM,XGW_Body
 SG_ ID_FN_RQ_BUS m12 : 8|16@1+ (1,0) [0|0] ""  BCM,XGW_Body
 SG_ NO_CC_MESS_EXT m65 : 8|16@1+ (1,0) [0|65534] ""  BCM,XGW_Body
 SG_ NO_CC_MESS_STD m64 : 8|16@1+ (1,0) [0|65534] ""  BCM,XGW_Body
 SG_ WACA m39 : 16|8@1+ (1,0) [0|0] ""  BCM,XGW_Body
 SG_ ID_RQ_BUS m12 : 24|8@1+ (1,0) [0|0] ""  BCM,XGW_Body
 SG_ ST_CC_MESS_EXT m65 : 24|2@1+ (1,0) [0|0] ""  BCM,XGW_Body
 SG_ ST_CC_MESS_STD m64 : 24|2@1+ (1,0) [0|0] ""  BCM,XGW_Body
 SG_ TRANF_CC_MESS_EXT m65 : 26|4@1+ (1,0) [0|14] ""  BCM,XGW_Body
 SG_ TRANF_CC_MESS_STD m64 : 26|4@1+ (1,0) [0|14] ""  BCM,XGW_Body
 SG_ ST_IDC_CCLK_CC_MESS_EXT m65 : 30|2@1+ (1,0) [0|0] ""  BCM,XGW_Body
 SG_ ST_IDC_CCLK_CC_MESS_STD m64 : 30|2@1+ (1,0) [0|0] ""  BCM,XGW_Body
 SG_ NO_FRM_CC_MESS_EXT m65 : 32|4@1+ (1,0) [0|14] ""  BCM,XGW_Body
 SG_ ST_RQ_BUS m12 : 32|4@1+ (1,0) [0|0] ""  BCM,XGW_Body
 SG_ QUAN_FRM_CC_MESS_EXT m65 : 36|4@1+ (1,0) [0|14] ""  BCM,XGW_Body
 SG_ ST_LAW_RQ m12 : 36|4@1+ (1,0) [0|0] ""  BCM,XGW_Body
 SG_ DUR_FLLUPT m12 : 40|8@1+ (1,0) [0|254] "min"  BCM,XGW_Body
 SG_ UTDT_CC_MESS m65 : 40|24@1+ (1,0) [0|0] ""  BCM,XGW_Body

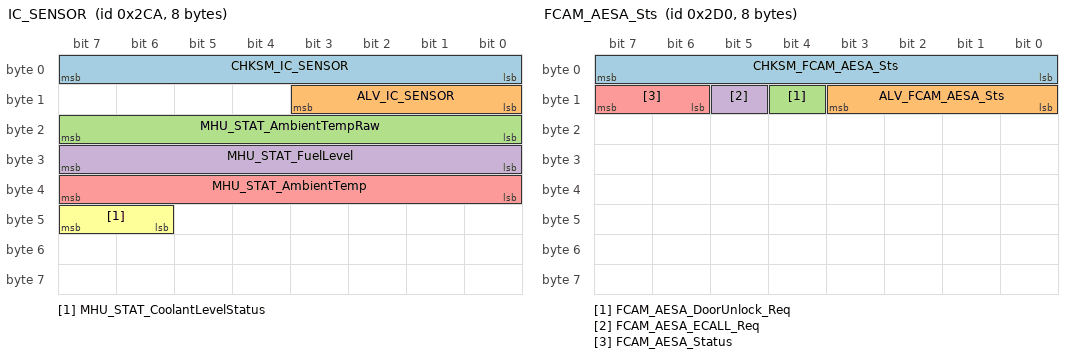
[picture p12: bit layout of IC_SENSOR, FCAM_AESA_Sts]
BO_ 714 IC_SENSOR: 8 XGW_Body
 SG_ CHKSM_IC_SENSOR : 7|8@0+ (1,0) [0|255] ""  ACM,APM,ASU_Gateway,BCM,BCM_BPM,CCU_F,CCU_R,ETG,LDM_L,LDM_R,OCS_P,PSM_D,SHVU_F,SHVU_R,TRM,USS_F,USS_R
 SG_ ALV_IC_SENSOR : 11|4@0+ (1,0) [0|14] ""  ACM,APM,ASU_Gateway,BCM,BCM_BPM,CCU_F,CCU_R,ETG,LDM_L,LDM_R,OCS_P,PSM_D,SHVU_F,SHVU_R,TRM,USS_F,USS_R
 SG_ MHU_STAT_AmbientTempRaw : 23|8@0+ (0.5,-40) [-40|85] "�C"  ACM,APM,ASU_Gateway,BCM,BCM_BPM,CCU_F,CCU_R,ETG,LDM_L,LDM_R,OCS_P,PSM_D,SHVU_F,SHVU_R,SRR_RR_M,TRM
 SG_ MHU_STAT_FuelLevel : 31|8@0+ (1,0) [0|100] "l"  ACM,APM,ASU_Gateway,BCM,BCM_BPM,CCU_F,CCU_R,ETG,LDM_L,LDM_R,OCS_P,PSM_D,SHVU_F,SHVU_R,TRM
 SG_ MHU_STAT_AmbientTemp : 39|8@0+ (0.5,-40) [-40|85] "Degree C"  ACM,APM,ASU_Gateway,BCM,BCM_BPM,CCU_F,CCU_R,ETG,LDM_L,LDM_R,OCS_P,PSM_D,SHVU_F,SHVU_R,TRM,USS_F,USS_R
 SG_ MHU_STAT_CoolantLevelStatus : 47|2@0+ (1,0) [0|3] "-"  ACM,APM,ASU_Gateway,BCM,BCM_BPM,CCU_F,CCU_R,ETG,LDM_L,LDM_R,OCS_P,PSM_D,SHVU_F,SHVU_R,TRM

BO_ 715 IC_TEMP: 8 BCM
 SG_ TEMP_EX : 7|8@0+ (0.5,-40) [-40|85] "�C"  XGW_Body
 SG_ TEMP_EX_UNFILT : 15|8@0+ (0.5,-40) [-40|85] "�C"  CCU_F,CCU_R,LDM_L,LDM_R,XGW_Body

 BO_ 720 FCAM_AESA_Sts: 8 XGW_Body
 SG_ CHKSM_FCAM_AESA_Sts : 7|8@0+ (1,0) [0|255] ""  BCM,ACM
 SG_ ALV_FCAM_AESA_Sts : 11|4@0+ (1,0) [0|14] ""  BCM,ACM
 SG_ FCAM_AESA_DoorUnlock_Req : 12|1@0+ (1,0) [0|1] ""  BCM
 SG_ FCAM_AESA_ECALL_Req : 13|1@0+ (1,0) [0|1] ""  Vector__XXX
 SG_ FCAM_AESA_Status : 15|2@0+ (1,0) [0|3] ""  BCM,ACM

BO_ 753 IC_STAT_AIRBAG: 1 XGW_Body
 SG_ MHU_STAT_AirbagWarnLamp : 1|2@0+ (1,0) [0|3] ""  ACM

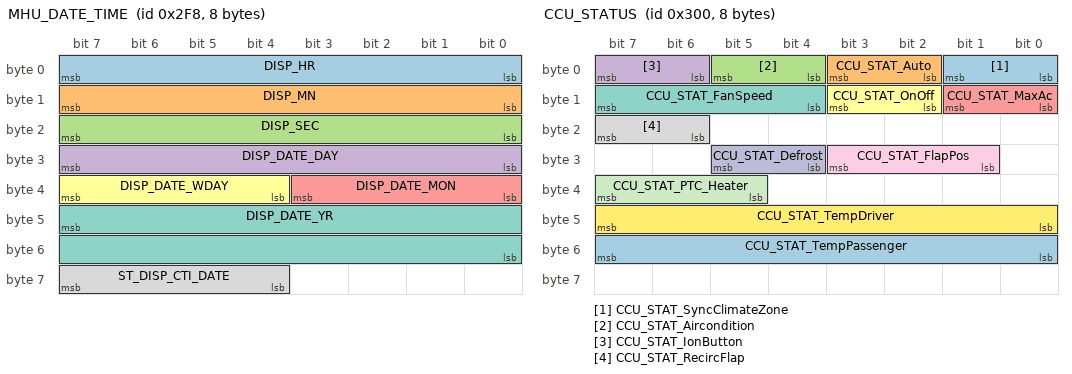
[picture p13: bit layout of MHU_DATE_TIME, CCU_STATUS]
BO_ 760 MHU_DATE_TIME: 8 XGW_Body
 SG_ DISP_HR : 7|8@0+ (1,0) [0|23] "h"  ACM,APM,ASU_Gateway,BCM,BCM_BPM,CCU_F,CCU_R,ETG,LDM_L,LDM_R,OCS_P,PSM_D,SHVU_F,SHVU_R,SRR_RR_M,TRM,USS_F,USS_R
 SG_ DISP_MN : 15|8@0+ (1,0) [0|59] "min"  ACM,APM,ASU_Gateway,BCM,BCM_BPM,CCU_F,CCU_R,ETG,LDM_L,LDM_R,OCS_P,PSM_D,SHVU_F,SHVU_R,SRR_RR_M,TRM,USS_F,USS_R
 SG_ DISP_SEC : 23|8@0+ (1,0) [0|59] "s"  ACM,APM,ASU_Gateway,BCM,BCM_BPM,CCU_F,CCU_R,ETG,LDM_L,LDM_R,OCS_P,PSM_D,SHVU_F,SHVU_R,SRR_RR_M,TRM,USS_F,USS_R
 SG_ DISP_DATE_DAY : 31|8@0+ (1,0) [1|31] "Day"  ACM,APM,ASU_Gateway,BCM,BCM_BPM,CCU_F,CCU_R,ETG,LDM_L,LDM_R,OCS_P,PSM_D,SHVU_F,SHVU_R,SRR_RR_M,TRM,USS_F,USS_R
 SG_ DISP_DATE_MON : 35|4@0+ (1,0) [1|12] "Month"  ACM,APM,ASU_Gateway,BCM,BCM_BPM,CCU_F,CCU_R,ETG,LDM_L,LDM_R,OCS_P,PSM_D,SHVU_F,SHVU_R,SRR_RR_M,TRM,USS_F,USS_R
 SG_ DISP_DATE_WDAY : 39|4@0+ (1,0) [0|15] ""  ACM,APM,ASU_Gateway,BCM,BCM_BPM,CCU_F,CCU_R,ETG,LDM_L,LDM_R,OCS_P,PSM_D,SHVU_F,SHVU_R,TRM
 SG_ DISP_DATE_YR : 47|16@0+ (1,0) [1|65534] "Year"  ACM,APM,ASU_Gateway,BCM,BCM_BPM,CCU_F,CCU_R,ETG,LDM_L,LDM_R,OCS_P,PSM_D,SHVU_F,SHVU_R,SRR_RR_M,TRM,USS_F,USS_R
 SG_ ST_DISP_CTI_DATE : 63|4@0+ (1,0) [0|15] ""  ACM,APM,ASU_Gateway,BCM,BCM_BPM,CCU_F,CCU_R,ETG,LDM_L,LDM_R,OCS_P,PSM_D,SHVU_F,SHVU_R,TRM,USS_F,USS_R

BO_ 768 CCU_STATUS: 8 CCU_F
 SG_ CCU_STAT_SyncClimateZone : 1|2@0+ (1,0) [0|3] ""  CCU_R,XGW_Body
 SG_ CCU_STAT_Auto : 3|2@0+ (1,0) [0|3] "-"  CCU_R,XGW_Body
 SG_ CCU_STAT_Aircondition : 5|2@0+ (1,0) [0|3] ""  CCU_R,XGW_Body
 SG_ CCU_STAT_IonButton : 7|2@0+ (1,0) [0|3] ""  CCU_R,XGW_Body
 SG_ CCU_STAT_MaxAc : 9|2@0+ (1,0) [0|3] ""  CCU_R,XGW_Body
 SG_ CCU_STAT_OnOff : 11|2@0+ (1,0) [0|3] "Bit"  CCU_R,XGW_Body
 SG_ CCU_STAT_FanSpeed : 15|4@0+ (1,0) [0|15] ""  CCU_R,XGW_Body
 SG_ CCU_STAT_RecircFlap : 23|2@0+ (1,0) [0|3] ""  CCU_R,XGW_Body
 SG_ CCU_STAT_FlapPos : 27|3@0+ (1,0) [0|7] ""  CCU_R,XGW_Body
 SG_ CCU_STAT_Defrost : 29|2@0+ (1,0) [0|3] "-"  CCU_R,XGW_Body
 SG_ CCU_STAT_PTC_Heater : 39|3@0+ (1,0) [0|7] "-"  CCU_R,XGW_Body
 SG_ CCU_STAT_TempDriver : 47|8@0+ (0.5,0) [16|32] "Degree C"  CCU_R,XGW_Body
 SG_ CCU_STAT_TempPassenger : 55|8@0+ (0.5,0) [16|32] "Degree C"  CCU_R,XGW_Body

BO_ 769 ADAS_RP_Sts: 8 XGW_Body
  SG_ RP_Status : 18|3@0+ (1,0) [0|7] "-" ACM

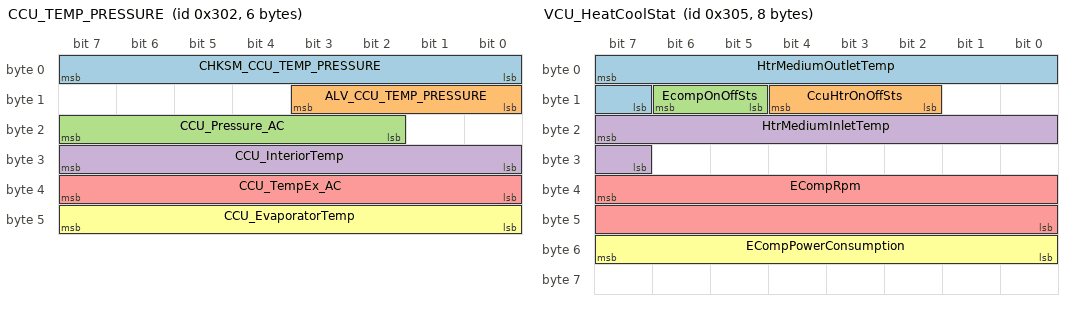
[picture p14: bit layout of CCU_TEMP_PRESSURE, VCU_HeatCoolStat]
BO_ 770 CCU_TEMP_PRESSURE: 6 CCU_F
 SG_ CHKSM_CCU_TEMP_PRESSURE : 7|8@0+ (1,0) [0|255] ""  XGW_Body,ACM
 SG_ ALV_CCU_TEMP_PRESSURE : 11|4@0+ (1,0) [0|14] ""  XGW_Body,ACM
 SG_ CCU_Pressure_AC : 23|6@0+ (1,0) [0|62] "bar"  XGW_Body
 SG_ CCU_InteriorTemp : 31|8@0+ (0.5,-40) [-40|85] "Degree C"  ACM,APM,ASU_Gateway,BCM,BCM_BPM,CCU_R,ETG,LDM_L,LDM_R,OCS_P,PSM_D,SHVU_F,SHVU_R,TRM,XGW_Body
 SG_ CCU_TempEx_AC : 39|8@0+ (0.5,-40) [-40|85] "Degree C"  ACM,APM,ASU_Gateway,BCM,BCM_BPM,CCU_R,ETG,LDM_L,LDM_R,OCS_P,PSM_D,SHVU_F,SHVU_R,TRM,XGW_Body
 SG_ CCU_EvaporatorTemp : 47|8@0+ (0.5,-40) [-40|85] "Degree C"  XGW_Body

BO_ 773 VCU_HeatCoolStat: 8 XGW_Body
 SG_ HtrMediumOutletTemp : 7|9@0+ (0.5,-40) [-40|200] "�C"  CCU_F,CCU_R
 SG_ CcuHtrOnOffSts : 12|3@0+ (1,0) [0|7] ""  CCU_F,CCU_R
 SG_ EcompOnOffSts : 14|2@0+ (1,0) [0|3] ""  CCU_F,CCU_R
 SG_ HtrMediumInletTemp : 23|9@0+ (0.5,-40) [-40|200] "Degree C"  CCU_F,CCU_R
 SG_ ECompRpm : 39|16@0+ (1,0) [0|12000] "1/min"  CCU_F,CCU_R
 SG_ ECompPowerConsumption : 55|8@0+ (0.1,0) [0|12] "kW"  CCU_F,CCU_R

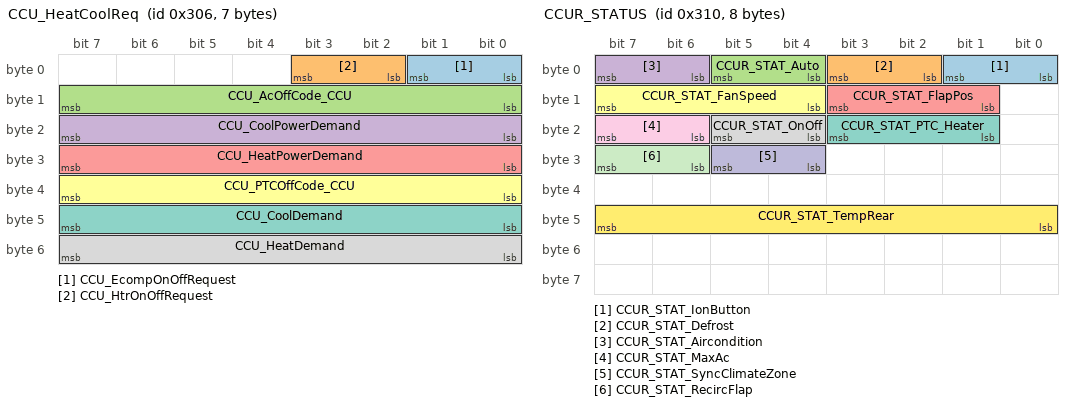
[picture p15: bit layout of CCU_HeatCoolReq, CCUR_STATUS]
BO_ 774 CCU_HeatCoolReq: 7 CCU_F
 SG_ CCU_EcompOnOffRequest : 1|2@0+ (1,0) [0|3] ""  XGW_Body
 SG_ CCU_HtrOnOffRequest : 3|2@0+ (1,0) [0|3] ""  XGW_Body
 SG_ CCU_AcOffCode_CCU : 15|8@0+ (1,0) [0|255] ""  XGW_Body
 SG_ CCU_CoolPowerDemand : 23|8@0+ (0.1,0) [0|10] "kW"  XGW_Body
 SG_ CCU_HeatPowerDemand : 31|8@0+ (0.1,0) [0|10] "kW"  XGW_Body
 SG_ CCU_PTCOffCode_CCU : 39|8@0+ (1,0) [0|255] ""  XGW_Body
 SG_ CCU_CoolDemand : 47|8@0+ (0.5,0) [0|100] "%"  XGW_Body
 SG_ CCU_HeatDemand : 55|8@0+ (0.5,0) [0|100] "%"  XGW_Body

BO_ 775 CPD_OUTPUT: 3 XGW_Body
 SG_ CHKSM_CPD_Output_1 : 7|8@0+ (1,0) [0|255] ""  BCM
 SG_ ALV_CPD_Output_1 : 11|4@0+ (1,0) [0|14] ""  BCM
 SG_ OUT_Alert_TO_BCM : 14|3@0+ (1,0) [0|7] "-"  BCM,CCU_F,CCU_R
 SG_ CPD_State_information : 20|3@0+ (1,0) [0|7] "-"  BCM

BO_ 784 CCUR_STATUS: 8 CCU_F
 SG_ CCUR_STAT_IonButton : 1|2@0+ (1,0) [0|3] "-"  XGW_Body
 SG_ CCUR_STAT_Defrost : 3|2@0+ (1,0) [0|3] ""  XGW_Body
 SG_ CCUR_STAT_Auto : 5|2@0+ (1,0) [0|3] ""  XGW_Body
 SG_ CCUR_STAT_Aircondition : 7|2@0+ (1,0) [0|3] "-"  XGW_Body
 SG_ CCUR_STAT_FlapPos : 11|3@0+ (1,0) [0|7] "-"  XGW_Body
 SG_ CCUR_STAT_FanSpeed : 15|4@0+ (1,0) [0|15] "-"  XGW_Body
 SG_ CCUR_STAT_PTC_Heater : 19|3@0+ (1,0) [0|7] ""  XGW_Body
 SG_ CCUR_STAT_OnOff : 21|2@0+ (1,0) [0|3] "Bit"  XGW_Body
 SG_ CCUR_STAT_MaxAc : 23|2@0+ (1,0) [0|3] ""  XGW_Body
 SG_ CCUR_STAT_SyncClimateZone : 29|2@0+ (1,0) [0|3] "-"  XGW_Body
 SG_ CCUR_STAT_RecircFlap : 31|2@0+ (1,0) [0|3] "-"  XGW_Body
 SG_ CCUR_STAT_TempRear : 47|8@0+ (0.5,0) [16|32] "Degree C"  XGW_Body

BO_ 808 IC_RELATIVTIME: 8 BCM
 SG_ T_SEC_COU_REL : 0|32@1+ (1,0) [0|4294967294] "s"  ASU_Gateway
 SG_ T_DAY_COU_ABSL : 32|16@1+ (1,0) [0|65534] "Day"  Vector__XXX

BO_ 806 POD_StatusDCDC1: 8 XGW_Body
  SG_ CHSKM_POD_StatusDCDC1 : 7|8@0+ (1,0) [0|255] "" BCM
  SG_ ALV_POD_StatusDCDC1 : 11|4@0+ (1,0) [0|14] "" BCM
  SG_ POD_statusDCDC : 14|3@0+ (1,0) [0|7] "" BCM

BO_ 809 BCM_ODO: 8 BCM
 SG_ CRC_BCM_ODO : 7|8@0+ (1,0) [0|255] ""  XGW_Body
 SG_ ALIV_BCM_ODO : 11|4@0+ (1,0) [0|14] ""  XGW_Body
 SG_ Odometer_BCM : 23|20@0+ (1,0) [0|999999] "km"  XGW_Body
 SG_ SECCAN_BCM_ODO : 63|8@0+ (1,0) [0|255] ""  XGW_Body

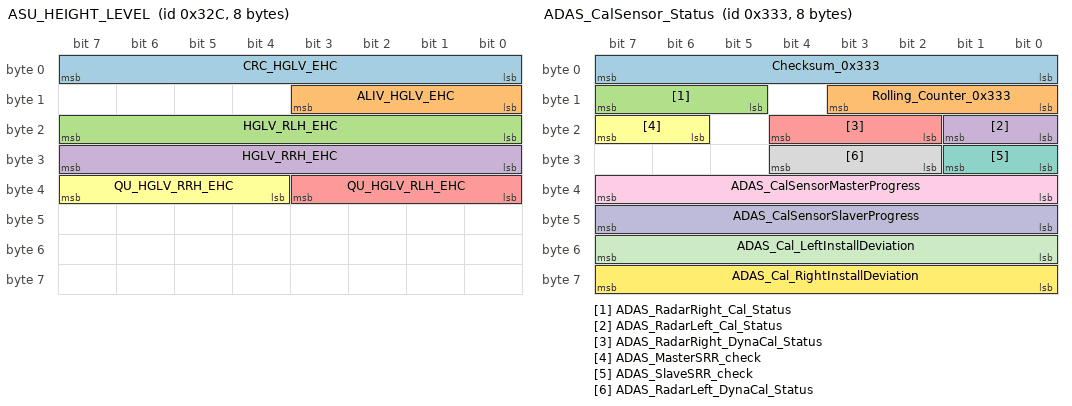
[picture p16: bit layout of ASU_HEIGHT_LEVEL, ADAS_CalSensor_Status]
BO_ 812 ASU_HEIGHT_LEVEL: 8 ASU_Gateway
 SG_ CRC_HGLV_EHC : 0|8@1+ (1,0) [0|255] ""  BCM
 SG_ ALIV_HGLV_EHC : 8|4@1+ (1,0) [0|14] ""  BCM
 SG_ HGLV_RLH_EHC : 16|8@1+ (1,-127) [-127|127] "mm"  BCM
 SG_ HGLV_RRH_EHC : 24|8@1+ (1,-127) [-127|127] "mm"  BCM
 SG_ QU_HGLV_RLH_EHC : 32|4@1+ (1,0) [0|15] ""  BCM
 SG_ QU_HGLV_RRH_EHC : 36|4@1+ (1,0) [0|15] ""  BCM

BO_ 814 ADAS_AEB_Status: 6 XGW_Body
 SG_ CRC_AEB_STATUS : 7|8@0+ (1,0) [0|255] ""  ACM
 SG_ Alive_AEB_STATUS : 11|4@0+ (1,0) [0|14] ""  ACM
 SG_ ADAS_AEB_Braking_Progress : 29|1@0+ (1,0) [0|1] ""  ACM

BO_ 816 IC_MILEAGE: 8 BCM
 SG_ MILE_KM : 7|24@0+ (1,0) [0|999999] "km"  ACM,APM,ASU_Gateway,BCM_BPM,CCU_F,CCU_R,ETG,LDM_L,LDM_R,OCS_P,PSM_D,SHVU_F,SHVU_R,TRM,XGW_Body
 SG_ FLLV_FUTA : 31|8@0+ (1,0) [0|254] "l"  ACM,APM,ASU_Gateway,BCM_BPM,CCU_F,CCU_R,ETG,LDM_L,LDM_R,OCS_P,PSM_D,SHVU_F,SHVU_R,TRM,XGW_Body
 SG_ RNG : 51|12@0+ (1,0) [0|4094] "km"  ACM,APM,ASU_Gateway,BCM_BPM,CCU_F,CCU_R,ETG,LDM_L,LDM_R,OCS_P,PSM_D,SHVU_F,SHVU_R,TRM,XGW_Body
 SG_ ST_FLLV_FUTA_SPAR : 55|2@0+ (1,0) [0|3] ""  ACM,APM,ASU_Gateway,BCM_BPM,CCU_F,CCU_R,ETG,LDM_L,LDM_R,OCS_P,PSM_D,SHVU_F,SHVU_R,TRM,XGW_Body

BO_ 819 ADAS_CalSensor_Status: 8 SRR_RR_M
 SG_ Checksum_0x333 : 7|8@0+ (1,0) [0|255] "" BCM,XGW_Body
 SG_ Rolling_Counter_0x333 : 11|4@0+ (1,0) [0|15] "" BCM,XGW_Body
 SG_ ADAS_RadarRight_Cal_Status : 15|3@0+ (1,0) [0|7] "" BCM,XGW_Body
 SG_ ADAS_RadarLeft_Cal_Status : 17|2@0+ (1,0) [0|3] "" BCM,XGW_Body
 SG_ ADAS_RadarRight_DynaCal_Status : 20|3@0+ (1,0) [0|7] "" BCM,XGW_Body
 SG_ ADAS_MasterSRR_check : 23|2@0+ (1,0) [0|3] "" BCM,XGW_Body
 SG_ ADAS_SlaveSRR_check : 25|2@0+ (1,0) [0|3] "" BCM,XGW_Body
 SG_ ADAS_RadarLeft_DynaCal_Status : 28|3@0+ (1,0) [0|7] "" BCM,XGW_Body
 SG_ ADAS_CalSensorMasterProgress : 39|8@0+ (0.4,0) [0|100] "%" BCM,XGW_Body
 SG_ ADAS_CalSensorSlaverProgress : 47|8@0+ (0.4,0) [0|100] "%" BCM,XGW_Body
 SG_ ADAS_Cal_LeftInstallDeviation : 55|8@0+ (0.1,-12.8) [-12.8|12.699999999999999289457264239899814128875732421875] "deg" BCM,XGW_Body
 SG_ ADAS_Cal_RightInstallDeviation : 63|8@0+ (0.1,-12.8) [-12.8|12.699999999999999289457264239899814128875732421875] "deg" BCM,XGW_Body

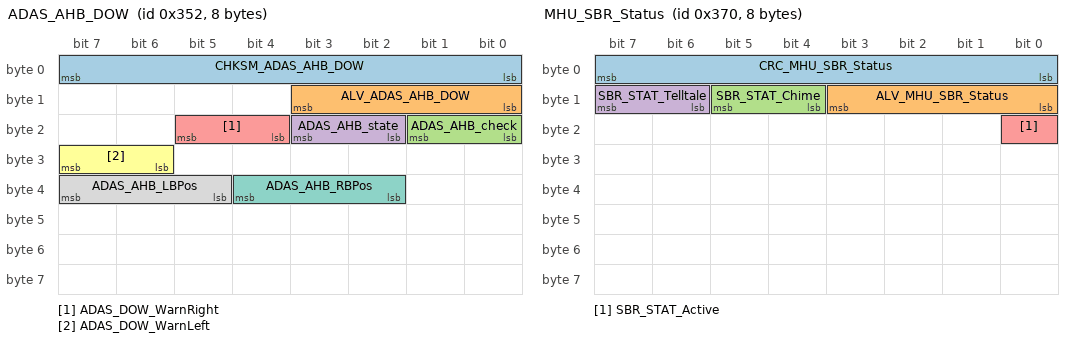
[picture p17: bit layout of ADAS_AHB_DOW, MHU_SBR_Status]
BO_ 850 ADAS_AHB_DOW: 8 XGW_Body
 SG_ CHKSM_ADAS_AHB_DOW : 7|8@0+ (1,0) [0|255] "" BCM
 SG_ ALV_ADAS_AHB_DOW : 11|4@0+ (1,0) [0|14] "" BCM
 SG_ ADAS_AHB_check : 17|2@0+ (1,0) [0|3] "-" BCM
 SG_ ADAS_AHB_state : 19|2@0+ (1,0) [0|3] "-" BCM
 SG_ ADAS_DOW_WarnRight : 21|2@0+ (1,0) [0|3] "-" BCM
 SG_ ADAS_DOW_WarnLeft : 31|2@0+ (1,0) [0|3] "-" BCM
 SG_ ADAS_AHB_RBPos : 36|3@0+ (1,0) [0|7] "" BCM
 SG_ ADAS_AHB_LBPos : 39|3@0+ (1,0) [0|7] "-" BCM

BO_ 851 ADAS_CMP_ACC: 8 XGW_Body
 SG_ ADAS_ACC_State : 31|3@0+ (1,0) [0|7] "-" ACM
 SG_ ADAS_ACC_check : 47|2@0+ (1,0) [0|3] "-" ACM

BO_ 852 MHU_ADAS_req: 8 XGW_Body
 SG_ CHKSM_MHU_ADAS_req : 7|8@0+ (1,0) [0|255] "" BCM
 SG_ ALV_MHU_ADAS_req : 11|4@0+ (1,0) [0|14] "" BCM
 SG_ MHU_RAEB_Mode : 13|2@0+ (1,0) [0|3] "-" Vector__XXX
 SG_ MHU_LA_AudWarning : 15|2@0+ (1,0) [0|3] "-" Vector__XXX
 SG_ MHU_BSD_On : 17|2@0+ (1,0) [0|3] "-" SRR_RR_M
 SG_ MHU_BSD_sens : 19|2@0+ (1,0) [0|3] "" SRR_RR_M
 SG_ MHU_BSD_AudWarning : 21|2@0+ (1,0) [0|3] "-" SRR_RR_M
 SG_ MHU_RCTA_On : 23|2@0+ (1,0) [0|3] "-" Vector__XXX
 SG_ MHU_RCTA_sens : 25|2@0+ (1,0) [0|3] "-" Vector__XXX
 SG_ MHU_PA_On : 27|2@0+ (1,0) [0|3] "-" SRR_RR_M,USS_F,USS_R
 SG_ MHU_AHB_On : 29|2@0+ (1,0) [0|3] "-" BCM
 SG_ MHU_IA_Mode : 31|2@0+ (1,0) [0|3] "-" Vector__XXX
 SG_ MHU_TSR_Mode : 33|2@0+ (1,0) [0|3] "-" Vector__XXX
 SG_ MHU_DOW_Mode : 35|2@0+ (1,0) [0|3] "-" Vector__XXX
 SG_ MHU_AHB_sens : 37|2@0+ (1,0) [0|3] "-" Vector__XXX
 SG_ MHU_FCW_sens : 39|2@0+ (1,0) [0|3] "-" Vector__XXX
 SG_ MHU_LA_Mode : 41|3@0+ (1,0) [0|7] "-" Vector__XXX
 SG_ MHU_FCW_Mode : 43|2@0+ (1,0) [0|3] "-" Vector__XXX
 SG_ MHU_SET_TSR_AudWarn : 45|2@0+ (1,0) [0|3] "-" Vector__XXX
 SG_ MHU_SET_TSR_SLAert : 47|2@0+ (1,0) [0|3] "-" Vector__XXX
 SG_ MHU_LA_sens : 49|2@0+ (1,0) [0|3] "-" Vector__XXX
 SG_ MHU_AEB_Mode : 51|2@0+ (1,0) [0|3] "-" Vector__XXX
 SG_ MHU_ESA_ON : 54|1@0+ (1,0) [0|1] ""  Vector__XXX
 SG_ MHU_ELKA_ON : 56|1@0+ (1,0) [0|1] ""  Vector__XXX

BO_ 880 MHU_SBR_Status: 8 XGW_Body
 SG_ CRC_MHU_SBR_Status : 7|8@0+ (1,0) [0|255] ""  ACM
 SG_ ALV_MHU_SBR_Status : 11|4@0+ (1,0) [0|14] ""  ACM
 SG_ SBR_STAT_Chime : 13|2@0+ (1,0) [0|3] ""  ACM
 SG_ SBR_STAT_Telltale : 15|2@0+ (1,0) [0|3] ""  ACM
 SG_ SBR_STAT_Active : 16|1@0+ (1,0) [0|1] ""  ACM

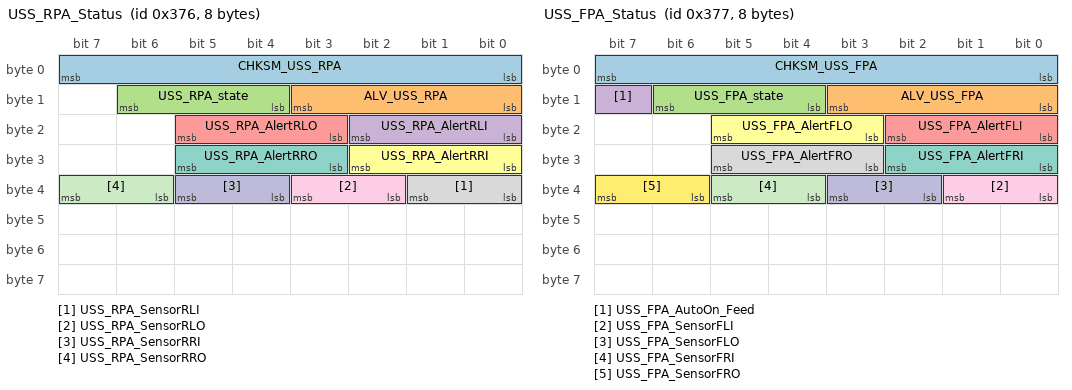
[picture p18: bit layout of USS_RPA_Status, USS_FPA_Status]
BO_ 886 USS_RPA_Status: 8 USS_R
 SG_ CHKSM_USS_RPA : 7|8@0+ (1,0) [0|255] ""  XGW_Body
 SG_ ALV_USS_RPA : 11|4@0+ (1,0) [0|14] ""  XGW_Body
 SG_ USS_RPA_state : 14|3@0+ (1,0) [1|7] ""  XGW_Body
 SG_ USS_RPA_AlertRLI : 18|3@0+ (1,0) [0|7] ""  XGW_Body
 SG_ USS_RPA_AlertRLO : 21|3@0+ (1,0) [0|7] ""  XGW_Body
 SG_ USS_RPA_AlertRRI : 26|3@0+ (1,0) [0|7] ""  XGW_Body
 SG_ USS_RPA_AlertRRO : 29|3@0+ (1,0) [0|7] ""  XGW_Body
 SG_ USS_RPA_SensorRLI : 33|2@0+ (1,0) [0|3] ""  XGW_Body
 SG_ USS_RPA_SensorRLO : 35|2@0+ (1,0) [0|3] ""  XGW_Body
 SG_ USS_RPA_SensorRRI : 37|2@0+ (1,0) [0|3] ""  XGW_Body
 SG_ USS_RPA_SensorRRO : 39|2@0+ (1,0) [0|3] ""  XGW_Body

BO_ 887 USS_FPA_Status: 8 USS_F
 SG_ CHKSM_USS_FPA : 7|8@0+ (1,0) [0|255] ""  XGW_Body
 SG_ ALV_USS_FPA : 11|4@0+ (1,0) [0|14] ""  XGW_Body
 SG_ USS_FPA_state : 14|3@0+ (1,0) [1|7] ""  XGW_Body
 SG_ USS_FPA_AutoOn_Feed : 15|1@0+ (1,0) [0|1] ""  XGW_Body
 SG_ USS_FPA_AlertFLI : 18|3@0+ (1,0) [0|7] ""  XGW_Body
 SG_ USS_FPA_AlertFLO : 21|3@0+ (1,0) [0|7] ""  XGW_Body
 SG_ USS_FPA_AlertFRI : 26|3@0+ (1,0) [0|7] ""  XGW_Body
 SG_ USS_FPA_AlertFRO : 29|3@0+ (1,0) [0|7] ""  XGW_Body
 SG_ USS_FPA_SensorFLI : 33|2@0+ (1,0) [0|3] ""  XGW_Body
 SG_ USS_FPA_SensorFLO : 35|2@0+ (1,0) [0|3] ""  XGW_Body
 SG_ USS_FPA_SensorFRI : 37|2@0+ (1,0) [0|3] ""  XGW_Body
 SG_ USS_FPA_SensorFRO : 39|2@0+ (1,0) [0|3] ""  XGW_Body

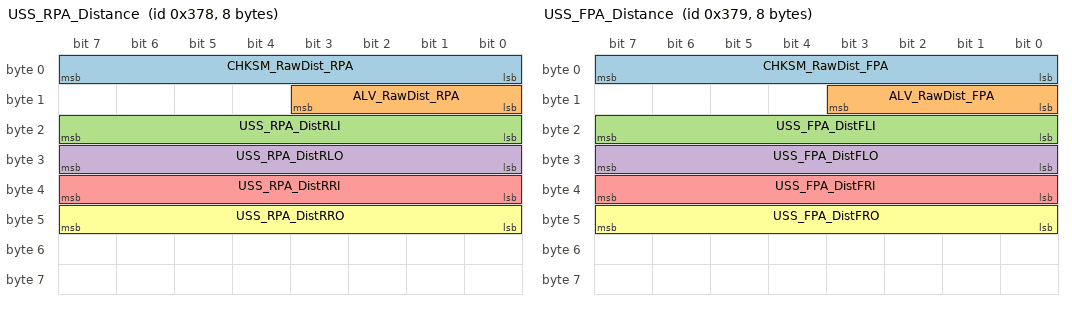
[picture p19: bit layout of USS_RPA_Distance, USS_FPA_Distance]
BO_ 888 USS_RPA_Distance: 8 USS_R
 SG_ CHKSM_RawDist_RPA : 7|8@0+ (1,0) [0|255] ""  XGW_Body
 SG_ ALV_RawDist_RPA : 11|4@0+ (1,0) [0|14] ""  XGW_Body
 SG_ USS_RPA_DistRLI : 23|8@0+ (1,0) [0|255] "cm"  XGW_Body
 SG_ USS_RPA_DistRLO : 31|8@0+ (1,0) [0|255] "cm"  XGW_Body
 SG_ USS_RPA_DistRRI : 39|8@0+ (1,0) [0|255] "cm"  XGW_Body
 SG_ USS_RPA_DistRRO : 47|8@0+ (1,0) [0|255] "cm"  XGW_Body

BO_ 889 USS_FPA_Distance: 8 USS_F
 SG_ CHKSM_RawDist_FPA : 7|8@0+ (1,0) [0|255] ""  XGW_Body
 SG_ ALV_RawDist_FPA : 11|4@0+ (1,0) [0|14] ""  XGW_Body
 SG_ USS_FPA_DistFLI : 23|8@0+ (1,0) [0|255] "cm"  XGW_Body
 SG_ USS_FPA_DistFLO : 31|8@0+ (1,0) [0|255] "cm"  XGW_Body
 SG_ USS_FPA_DistFRI : 39|8@0+ (1,0) [0|255] "cm"  XGW_Body
 SG_ USS_FPA_DistFRO : 47|8@0+ (1,0) [0|255] "cm"  XGW_Body

CM_ SG_ 521 CHKSM_PAS_RAEB "Checksum.";
CM_ SG_ 521 ALV_PAS_RAEB "Alive Counter.";
CM_ SG_ 521 PAS_RAEB_check "Rear Automatic Emergency Brake Check.";
CM_ SG_ 521 PAS_RAEB_State "Rear Automatic Emergency Brake State.";
CM_ SG_ 521 PAS_RAEB_Warning "Rear Automatic Emergency Brake warning.";
CM_ BO_ 522 "Rear Lift Gate Status";
CM_ SG_ 522 ETG_Lift_Gate_Status "The working status of rear lift gate";
CM_ SG_ 522 ETG_Power_Latch_Status "The working status of power latch";
CM_ SG_ 522 ETG_Latch_Segment "The segment of power latch";
CM_ SG_ 522 ETG_Opening_Percentage "The opening percentage of rear lift gate";
CM_ SG_ 522 ETG_DSW_Status "The status of driver switch";
CM_ SG_ 522 ETG_GSW_Status "The status of gate switch";
CM_ SG_ 522 ETG_LTS_Status "The status of left touch sensor";
CM_ SG_ 522 ETG_RTS_Status "The status of right touch sensor";
CM_ SG_ 522 ETG_HAL_Status "The level status of latch's half switch";
CM_ SG_ 522 ETG_FUL_Status "The level status of latch's full switch";
CM_ SG_ 522 ETG_AJR_Status "The level status of latch's AJAR switch";
CM_ SG_ 522 ETG_NTL_Status "The level status of latch's neutral switch";
CM_ SG_ 522 ETG_ERR_Voltage "The error status of ETG voltage";
CM_ SG_ 522 ETG_ERR_Left_Motor "The error status of left lift motor";
CM_ SG_ 522 ETG_ERR_Right_Motor "The error status of right lift motor";
CM_ SG_ 522 ETG_ERR_Latch "The error status of power latch";
CM_ SG_ 522 ETG_ERR_Hall "The error status of hall signal";
CM_ SG_ 522 ETG_Lift_Motor_Stall "The stall protection status of lift motor";
CM_ SG_ 522 ETG_Lift_Motor_AntiPinch "The antipinch protection status of lift motor";
CM_ SG_ 522 ETG_Lift_Motor_Thermal "The thermal protection status of lift motor";
CM_ SG_ 522 ETG_Power_Latch_Thermal "The thermal protection status of power latch";
CM_ SG_ 522 ETG_Abuse_Protection "The abuse protection status of ETG";
CM_ BO_ 523 "Foot Kick Senor Status";
CM_ SG_ 523 FKS_RespError "FMS Error Status";
CM_ SG_ 523 FKS_OpenReq "Hands Free Access Operation Request";
CM_ SG_ 523 FKS_HWError "HW Error is set if error in RAM, ROM or NVRAM is detected.";
CM_ SG_ 523 FKS_AntennaError "Error for Bottom and Top Electrode is set if electrode is not connected, connection is broken or electrod is shorted to GND/VSUP.";
CM_ SG_ 523 FKS_OverVolDected "Over voltage error";
CM_ SG_ 523 FKS_UnderVolDected "Under voltage error";
CM_ SG_ 523 FKS_activate_deactivate "feedback activate or deactivate ";
CM_ BO_ 524 "IC ODO";
CM_ SG_ 524 CHKSM_IC_ODO "Checksum";
CM_ SG_ 524 ALIV_IC_ODO "Alive Counter";
CM_ SG_ 524 MHU_Odometer_IC "Odometer information.";
CM_ BO_ 525 "IDB status";
CM_ SG_ 525 CHKSM_IDB_STATUS "Checksum";
CM_ SG_ 525 ALV_IDB_STATUS "Alive counter";
CM_ SG_ 525 ESPTransRequestType "ESP Request Type";
CM_ SG_ 525 ABSFault "ABS Fault Status";
CM_ SG_ 525 ABSActive "Further details when which bit will be set are defined within attached Excel file: Functions_Interventions File is at the moment under review at Bosch IDB side";
CM_ SG_ 525 VehicleSpd "Vehicle Speed";
CM_ SG_ 525 MCPressureSts "Main Cilinder Pressure Status";
CM_ SG_ 525 VehicleSpdSts "Vehicle Speed Status";
CM_ SG_ 525 MCPressure "MC Pressure";
CM_ SG_ 525 BRAKE_LightonRequestEPBi "Brake lights on equested by EPBi";
CM_ SG_ 525 VDCActive "Vehicle dynamic control activation";
CM_ SG_ 525 TCSActive "Traction control system activation";
CM_ SG_ 525 TCSAvailable "Traction control system available";
CM_ SG_ 525 IDBActive "IDB activation";
CM_ SG_ 525 IDBFault "IDB fault ";
CM_ SG_ 525 IDB_Power_Stage "interchange prevention signal ";
CM_ BO_ 527 "ADAS_BCM_Status";
CM_ SG_ 527 CHKSM_ADAS_BCM_Status "Checksum";
CM_ SG_ 527 ALIVE_ADAS_BCM_Status "Alive counter";
CM_ SG_ 527 ADAS_BCM_HeadlightReq "ADAS_request BCM to light up headlight lowbeam";
CM_ SG_ 527 ADAS_BCM_FoldMirrorReq "ADAS_request BCM to fold rearview mirror";
CM_ SG_ 527 ADAS_BCM_Status "ADAS_Status";
CM_ SG_ 527 ADAS_BCM_IndicatorlightReq "ADAS_request BCM to light up these light";
CM_ SG_ 527 SECCAN_ADAS_BCM_Sts "Secret portion from Secure CAN algorithm";
CM_ BO_ 528 "RCU status";
CM_ SG_ 528 CHKSM_RCU_Status "Checksum";
CM_ SG_ 528 ALV_RCU_Status "Alive Counter";
CM_ SG_ 528 RCU_DAA_NoOpDoorOpen_1 "Drive Away Assist doesn't work due to Driver door?s open)";
CM_ SG_ 528 RCU_EPBParkingStatus "Electric Parking Brake Applied/Released";
CM_ SG_ 528 EPB_Swch_Mafnc "EPB switch is malfunction or brakes are incoherent";
CM_ SG_ 528 RCU_ParkBrkApplied_1 "Parking Brake applied";
CM_ SG_ 528 RCU_ReleaseEPB_Wo_PressBrk_1 "Driver Try to release EPB without press brake pedal. Alert driver press brake pedal to release EPB";
CM_ SG_ 528 RCU_BrkForceNotEnough_1 "Brake force not enough warning, Demand clamp force not achieved";
CM_ SG_ 528 RCU_ParkOnSteepInclination_1 "Vehicle parks on a steep inclination warning";
CM_ SG_ 528 RCU_ECD_RWU_active_1 "ECD/RWU active";
CM_ SG_ 528 RCU_EHandBrk_fault_1 "Park brake fault";
CM_ SG_ 528 RCU_BRAKE_LightonRequestEPBi "Brake lights on equested by EPBi";
CM_ BO_ 533 "BMS status";
CM_ SG_ 533 Checksum_0x215 "Checksum";
CM_ SG_ 533 Rolling_Counter_0x215 "Rolling Counter";
CM_ SG_ 533 BMS_BatBalance_ERR "Battery Balance Error indicates Balancing switch is short or open";
CM_ SG_ 533 BMS_Balance_STS "BMS Balance Status ";
CM_ SG_ 533 BMS_IGN_Sts "the ignition signal status (on/off)";
CM_ SG_ 533 BMS_HWCrash_Sts "Battery Pack Hardware Crash signal Status";
CM_ SG_ 533 BMS_HVIL_STS "The HVIL state of BMS";
CM_ SG_ 533 BMS_HVOnOff_STS "Status of the High Voltage";
CM_ SG_ 533 BMS_ERR_LEV "BMS requesting VCU to operate at the limited operating strategy (LOS)";
CM_ SG_ 533 BMS_SocActual_EST "Actual SOC ";
CM_ SG_ 533 BMS_Sys_STS "BMS_Status(Self-test after BMS wake-up) BMS VCU";
CM_ SG_ 533 BMS_ISU_Status "Pack Insulation Status";
CM_ SG_ 533 BMS_SOH "BMS State Of Health ";
CM_ SG_ 533 BMS_SOE "BMS State Of Enegy ";
CM_ SG_ 533 BMS_HV_Sts "HV Status";
CM_ BO_ 537 "VCU Control";
CM_ SG_ 537 CHSKM_VCU_PTControl "Checksum";
CM_ SG_ 537 ALV_VCU_PTControl "Alive Counter";
CM_ SG_ 537 VCU_ChargeAllow "The flag of VCU allows BMS charging";
CM_ SG_ 540 FCAM_AEB_Warning "Automatic Emergency Brake Warning Mode ";
CM_ SG_ 540 FCAM_AEB_State "Automatic Emergency Brake State";
CM_ SG_ 540 FCAM_AEB_check "Automatic Emergency Brake Check";
CM_ BO_ 544 "MHU Climate Setting";
CM_ SG_ 544 MHU_SET_CCUR_AirCondition "On Off Air Condition";
CM_ SG_ 544 MHU_SET_CCUR_AutoAC "On Off Auto Air Condition";
CM_ SG_ 544 MHU_SET_CCUR_RearLock "Lock the Rear AC";
CM_ SG_ 544 MHU_SET_CCUR_MaxAc "On Off Max Air Condition for 2 zone";
CM_ SG_ 544 MHU_SET_CCUR_FanSpeed "Adjust Fan speed with 6 level";
CM_ SG_ 544 MHU_SET_CCUR_Recirculation "Change recirculation mode inside, ouside, auto";
CM_ SG_ 544 MHU_SET_CCUR_Ion "On Off Air ionizer";
CM_ SG_ 544 MHU_SET_CCUR_FlapPosition "Change Flap position Face, Feet, Front defrost";
CM_ SG_ 544 MHU_SET_CCUR_SyncClimateZone "On Off sync temperature between zone";
CM_ SG_ 544 MHU_SET_CCUR_TempRear "change rear zone temperature";
CM_ SG_ 544 MHU_SET_CCUR_FrontDefrost "Change Flap poition to Front Defrost";
CM_ BO_ 545 "CCUR_ClimateSetting";
CM_ SG_ 545 CCUR_Req_AirCondition "On Off Air Condition to CCUF";
CM_ SG_ 545 CCUR_AirDistribFlapActPos "Air Distribution actual flap position Rear";
CM_ SG_ 545 CCUR_TempFlapActPos "Temperature actual flap position for Rear";
CM_ SG_ 545 SECCAN_CCUR "Seed generated from Secure CAN algorithm";
CM_ BO_ 546 "CCUF_ClimateSetting";
CM_ SG_ 546 FRONT_SET_Rear_AirCondition "On Off Air Condition of Rear";
CM_ SG_ 546 SECCAN_CCUF "Seed generated from Secure CAN algorithm";
CM_ BO_ 547 "Door Front Latch Command";
CM_ SG_ 547 NDoorFLVehicleLocked "Front Left Door Vehicle Locked Signal";
CM_ SG_ 547 NDoorFLVehicleMoving "Front Left Door Vehicle Moving Signal";
CM_ SG_ 547 NDoorFLOpenInvRequested "Front Left Door Open Request Inverted Signal";
CM_ SG_ 547 NDoorFLOpenRequested "Front Left Door Open Request Signal";
CM_ SG_ 547 NDoorFLChildLocked "Front Left Door Child Locked Signal";
CM_ SG_ 547 NDoorFLVehicleCrash "Front Left Door Vehicle Crash Signal";
CM_ SG_ 547 NDoorFLCommandCounter "Front Left Door Command Message Counter";
CM_ SG_ 547 NDoorFLCloseInvRequested "Front Left Door Close Request Inverted Signal";
CM_ SG_ 547 NDoorFLCloseRequested "Front Left Door Close Request Signal";
CM_ BO_ 548 "VCU temperature information";
CM_ SG_ 548 CHSKM_VCU_BMS_Thermal_FB "Checksum";
CM_ SG_ 548 ALIV_VCU_BMS_Thermal_FB "Rolling Counter";
CM_ SG_ 548 VCU_BMS_PTCOnOff_Sts "VCU sends the status of the PTC Heater";
CM_ SG_ 548 VCU_BMS_ValveOnOff_Sts "VCU sends the status of the valve";
CM_ SG_ 548 VCU_BMS_PumpFB "VCU sends the PUMP feedback";
CM_ BO_ 561 "Door Front Latch Status";
CM_ SG_ 561 NDoorFLHomeSignal "Front Left Door Ratchet Status";
CM_ SG_ 561 NDoorFLSecondarySignal "Front Left Door Ratchet Status";
CM_ SG_ 561 NDoorFLPrimarySignal "Front Left Door Ratchet Status";
CM_ SG_ 561 NDoorFLClawSignal "Front Left Door Ratchet Status";
CM_ SG_ 561 NDoorFLClawStatus "Front Left Door Claw Status";
CM_ SG_ 561 BDLFLResponseError "Front Left Door Latch Failure Status";
CM_ SG_ 561 NDoorFLCounter "Front Left Door Outside Handle Status";
CM_ SG_ 561 NDoorFLOutsideHandleFailure "Front Left Door Outside Handle Failure";
CM_ SG_ 561 NDoorFLOutsideHandleStatus "Front Left Door Latch LIN Error";
CM_ SG_ 561 NDoorLatchFLFailure "Front Left Door Status Message Counter";
CM_ BO_ 565 "Trailer Status";
CM_ SG_ 565 CHKSM_TRM_STATUS "Checksum";
CM_ SG_ 565 ALIVE_TRM_STATUS "Alive counter";
CM_ SG_ 565 TowingDetected "Towing status ( reserved )";
CM_ SG_ 565 TrailerDetected "Trailer Detected status";
CM_ BO_ 569 "Door Front Right Latch Status";
CM_ SG_ 569 NDoorRRHomeSignal "Rear Right Door Ratchet Status";
CM_ SG_ 569 NDoorRRSecondarySignal "Rear Right Door Ratchet Status";
CM_ SG_ 569 NDoorRRPrimarySignal "Rear Right Door Ratchet Status";
CM_ SG_ 569 NDoorRRClawSignal "Rear Right Door Ratchet Status";
CM_ SG_ 569 NDoorRRClawStatus "Rear Right Door Claw Status";
CM_ SG_ 569 BDLRRResponseError "Rear Right Door Latch Failure Status";
CM_ SG_ 569 NDoorRRCounter "Rear Right Door Outside Handle Status";
CM_ SG_ 569 NDoorRROutsideHandleFailure "Rear Right Door Outside Handle Failure";
CM_ SG_ 569 NDoorRROutsideHandleStatus "Rear Right Door Latch LIN Error";
CM_ SG_ 569 NDoorLatchRRFailure "Rear Right Door Status Message Counter";
CM_ BO_ 570 "IDB Front Wheel Status";
CM_ SG_ 570 IDB_WheelDirection_FR "IDB Front Right Wheel Direction";
CM_ SG_ 570 IDB_WheelDirection_FL "IDB Front Left Wheel Direction";
CM_ BO_ 571 "IDB Rear Wheel Status";
CM_ SG_ 571 IDB_WheelDirection_RR "IDB Rear Right Wheel Direction";
CM_ SG_ 571 IDB_WheelDirection_RL "IDB Rear Left Wheel Direction";
CM_ BO_ 578 "Door Front Right Command";
CM_ SG_ 578 NDoorFRVehicleLocked "Front Right Door Vehicle Locked Signal";
CM_ SG_ 578 NDoorFRVehicleMoving "Front Right Door Vehicle Moving Signal";
CM_ SG_ 578 NDoorFROpenInvRequested "Front Right Door Open Request Inverted Signal";
CM_ SG_ 578 NDoorFROpenRequested "Front Right Door Open Request Signal";
CM_ SG_ 578 NDoorFRChildLocked "Front Right Door Child Locked Signal";
CM_ SG_ 578 NDoorFRVehicleCrash "Front Right Door Vehicle Crash Signal";
CM_ SG_ 578 NDoorFRCommandCounter "Front Right Door Command Message Counter";
CM_ SG_ 578 NDoorFRCloseInvRequested "Front Right Door Close Request Inverted Signal";
CM_ SG_ 578 NDoorFRCloseRequested "Front Right Door Close Request Signal";
CM_ BO_ 584 "Door Front Right Latch Status";
CM_ SG_ 584 NDoorFRHomeSignal "Front Right Door Ratchet Status";
CM_ SG_ 584 NDoorFRSecondarySignal "Front Right Door Ratchet Status";
CM_ SG_ 584 NDoorFRPrimarySignal "Front Right Door Ratchet Status";
CM_ SG_ 584 NDoorFRClawSignal "Front Right Door Ratchet Status";
CM_ SG_ 584 NDoorFRClawStatus "Front Right Door Claw Status";
CM_ SG_ 584 BDLFRResponseError "Front Right Door Latch Failure Status";
CM_ SG_ 584 NDoorFRCounter "Front Right Door Outside Handle Status";
CM_ SG_ 584 NDoorFROutsideHandleFailure "Front Right Door Outside Handle Failure";
CM_ SG_ 584 NDoorFROutsideHandleStatus "Front Right Door Latch LIN Error";
CM_ SG_ 584 NDoorLatchFRFailure "Front Right Door Status Message Counter";
CM_ BO_ 592 "BMS thermal request";
CM_ SG_ 592 CHSKM_BMS_VCU_THMReq "Check sum";
CM_ SG_ 592 ALV_BMS_VCU_THMReq "Alive counter";
CM_ SG_ 592 BMS_FlowRate_Req "Flow rate required";
CM_ SG_ 592 BMS_CoolPwrDemand "requesting the cooling power required fro the battery pack";
CM_ SG_ 592 BMS_HeatPwrDemand "requesting the heating power required fro the battery pack";
CM_ SG_ 592 BMS_VCU_PTCOnOff_Req "PTC Heater turn on and off request";
CM_ SG_ 592 BMS_VCU_ValveOnOff_Req "requesting VCU to turn on and off the valve";
CM_ SG_ 592 BMS_PreHeatCoolReq "Battery pack precondition information";
CM_ BO_ 593 "Door Rear Latch Command";
CM_ SG_ 593 NDoorRLVehicleLocked "Rear Left Door Vehicle Locked Signal";
CM_ SG_ 593 NDoorRLVehicleMoving "Rear Left Door Vehicle Moving Signal";
CM_ SG_ 593 NDoorRLOpenInvRequested "Rear Left Door Open Request Inverted Signal";
CM_ SG_ 593 NDoorRLOpenRequested "Rear Left Door Open Request Signal";
CM_ SG_ 593 NDoorRLChildLocked "Rear Left Door Child Locked Signal";
CM_ SG_ 593 NDoorRLVehicleCrash "Rear Left Door Vehicle Crash Signal";
CM_ SG_ 593 NDoorRLCommandCounter "Rear Left Door Command Message Counter";
CM_ SG_ 593 NDoorRLCloseInvRequested "Rear Left Door Close Request Inverted Signal";
CM_ SG_ 593 NDoorRLCloseRequested "Front Left Door Close Request Signal";
CM_ BO_ 596 "Wheel Speed Rear";
CM_ SG_ 596 CRC_AVL_RPM_WHL_REAR "Checksum";
CM_ SG_ 596 ALIV_AVL_RPM_WHL_REAR "Alive Counter";
CM_ SG_ 596 AVL_RPM_WHL_RLH "Measured speed of the rear left single wheel.";
CM_ SG_ 596 AVL_RPM_WHL_RRH "Measured speed of the rear right single wheel.";
CM_ SG_ 596 QU_AVL_RPM_WHL_RLH "status qualifier to signal actual-value_RPM_wheel_HL.";
CM_ SG_ 596 QU_AVL_RPM_WHL_RRH "status qualifier to signal actual-value_RPM_wheel_HR.";
CM_ BO_ 597 "Wheel Speed Front";
CM_ SG_ 597 CRC_AVL_RPM_WHL_FRONT "Checksum";
CM_ SG_ 597 ALIV_AVL_RPM_WHL_FRONT "Alive Counter";
CM_ SG_ 597 AVL_RPM_WHL_FLH "Measured speed of the front left single wheel.";
CM_ SG_ 597 AVL_RPM_WHL_FRH "Measured speed of the front right single wheel.";
CM_ SG_ 597 QU_AVL_RPM_WHL_FLH "status qualifier to signal actual-value_RPM_wheel_VL.";
CM_ SG_ 597 QU_AVL_RPM_WHL_FRH "status qualifier to signal actual-value_RPM_wheel_VL.";
CM_ BO_ 598 "BCM_LDM_Animation_Info";
CM_ SG_ 598 BCM_Animation_Req "animation mode request from BCM to LDM";
CM_ SG_ 598 BCM_Charging_Sts "charging status of the car";
CM_ SG_ 598 BCM_Lock_Sts "lock status of the car";
CM_ SG_ 598 BCM_Panic_Status "Car alarm system switch status";
CM_ SG_ 598 BCM_Charging_SOC "the feedback of Battery level";
CM_ SG_ 598 BCM_LeftPosLmpSts "Left Position lamp status ";
CM_ SG_ 598 BCM_RightPosLmpSts "Right Position lamp status ";
CM_ BO_ 618 "ST_LCS_VEH";
CM_ SG_ 618 ALIV_ST_LCS_VEH "Standardabsicherung Alivez�hler laut Definition per Lastenheft Allgemeine Bordnetzkommunikation.";
CM_ SG_ 618 ST_ECU_ST_LCS_VEH "Ziel des ECU-Status ist zus�tzliche Information �ber den Hardware-Status mitzuliefern. Die Auswertung des Qualifiers auf Empf�ngerseite ist optional.

Diese Information darf nicht als alleiniger Ausl�ser f�r eine funktionale Degradation verwendet werden, sondern soll eine genauere Diagnose im Falle einer Degradation aufgrund der mitgesendeten Signal-Qualifier oder Funktions-Qualifiern erm�glichen. N�here Informationen sind dem Lastenheft Diagnose zu entnehmen.";
CM_ SG_ 618 QU_FN_LCS_VEH "Qualifier";
CM_ BO_ 619 "Frm_TgtValA";
CM_ SG_ 619 Sig_TgtVer_LR "AVAC Target Position Request";
CM_ BO_ 620 "Frm_TgtValB";
CM_ SG_ 620 Sig_SPVer_L "AVAC Target Position Request";
CM_ SG_ 620 Sig_SPVer_R "AVAC Target Position Request";
CM_ SG_ 620 Sig_RefVer_LR "AVAC Target Position Request";
CM_ BO_ 641 "Door Front Right Latch Status";
CM_ SG_ 641 NDoorRLHomeSignal "Rear Left Door Ratchet Status";
CM_ SG_ 641 NDoorRLSecondarySignal "Rear Left Door Ratchet Status";
CM_ SG_ 641 NDoorRLPrimarySignal "Rear Left Door Ratchet Status";
CM_ SG_ 641 NDoorRLClawSignal "Rear Left Door Ratchet Status";
CM_ SG_ 641 NDoorRLClawStatus "Rear Left Door Claw Status";
CM_ SG_ 641 BDLRLResponseError "Rear Left Door Latch Failure Status";
CM_ SG_ 641 NDoorRLCounter "Rear Left Door Outside Handle Status";
CM_ SG_ 641 NDoorRLOutsideHandleFailure "Rear Left Door Outside Handle Failure";
CM_ SG_ 641 NDoorRLOutsideHandleStatus "Rear Left Door Latch LIN Error";
CM_ SG_ 641 NDoorLatchRLFailure "Rear Left Door Status Message Counter";
CM_ BO_ 649 "Acc Long Lat yaw";
CM_ SG_ 649 CHKSM_IDB_ZF2 "Checksum";
CM_ SG_ 649 ALIVE_IDB_ZF2 "Alive counter";
CM_ SG_ 649 AxOutStatus "Longitudinal acceleration status";
CM_ SG_ 649 QU_VYAW_VEH "Qualifier yaw velocity vehicle. All not defined values are reserved.";
CM_ SG_ 649 AyOutStatus "Lateral acceleration status";
CM_ SG_ 649 AcceleratorY "Lateral acceleration";
CM_ SG_ 649 AcceleratorX "Longitudinal acceleration";
CM_ SG_ 649 VYAW_VEH "Yaw velocity vehicle";
CM_ BO_ 654 "APM window position";
CM_ SG_ 654 CHKSM_APM_WINDOW_POS "Checksum";
CM_ SG_ 654 ALV_APM_WINDOW_POS "Alive counter";
CM_ SG_ 654 Window_PosFL "Front left window position";
CM_ SG_ 654 Window_Warning "Warning for window not closed";
CM_ SG_ 654 Wndow_PosRL "Rear left window position";
CM_ SG_ 654 Window_PosFR "Front right window position";
CM_ SG_ 654 Global_close "All windows close";
CM_ SG_ 654 Global_open "All windows open";
CM_ SG_ 654 Window_PosRR "Rear right window position";
CM_ BO_ 657 "Door Rear Latch Command";
CM_ SG_ 657 NDoorRRVehicleLocked "Rear Right Door Vehicle Locked Signal";
CM_ SG_ 657 NDoorRRVehicleMoving "Rear Right Door Vehicle Moving Signal";
CM_ SG_ 657 NDoorRROpenInvRequested "Rear Right Door Open Request Inverted Signal";
CM_ SG_ 657 NDoorRROpenRequested "Rear Right Door Open Request Signal";
CM_ SG_ 657 NDoorRRChildLocked "Rear Right Door Child Locked Signal";
CM_ SG_ 657 NDoorRRVehicleCrash "Rear Right Door Vehicle Crash Signal";
CM_ SG_ 657 NDoorRRCommandCounter "Rear Right Door Command Message Counter";
CM_ SG_ 657 NDoorRRCloseInvRequested "Rear Right Door Close Request Inverted Signal";
CM_ SG_ 657 NDoorRRCloseRequested "Front Left Door Close Request Signal";
CM_ BO_ 673 "Drv Seat massage";
CM_ SG_ 673 DrvSeatMsgStrLvl "Drv Seat Message Str Lvl";
CM_ SG_ 673 PassSeatMsgStrLvl "Pass Seat Message Str Lvl";
CM_ SG_ 673 RearDrvSeatMsgStrLvl "Rear Drv Sea tMessage St rLvl";
CM_ SG_ 673 RearPassSeatMsgStrLvl "Rear Pass Seat Message Str Lvl";
CM_ SG_ 673 DrvSeatMsgMode "DrvSeatMsgMode";
CM_ SG_ 673 PassSeatMsgMode "PassSeatMsgMode";
CM_ SG_ 673 RearDrvSeatMsgMode "RearDrvSeatMsgMode";
CM_ SG_ 673 RearPassSeatMsgMode "RearPassSeatMsgMode";
CM_ BO_ 674 "Drv Seat Mode Massage";
CM_ SG_ 674 DrvSeatMsgModeStat "DrvSeatMsgModeStat";
CM_ SG_ 674 PassSeatMsgModeStat "PassSeatMsgModeStat";
CM_ SG_ 674 RearDrvSeatMsgModeStat "RearDrvSeatMsgModeStat";
CM_ SG_ 674 RearPassSeatMsgModeStat "RearPassSeatMsgModeStat";
CM_ SG_ 674 LSSM_ALINResErr "LSSM_A DrvSeat LINResErr";
CM_ SG_ 674 LSSM_APumpFail "LSSM_A DrvSeat PumpFail";
CM_ SG_ 674 DrvSeatMsgStrLvlStat "DrvSeatMsgStrLvlStat";
CM_ SG_ 674 LSSM_BLINResErr "LSSM_B PassSeat LINResErr";
CM_ SG_ 674 LSSM_BPumpFail "LSSM_B PassSeat PumpFail";
CM_ SG_ 674 PassSeatMsgStrLvlStat "PassSeatMsgStrLvlStat";
CM_ SG_ 674 LSSM_CLINResErr "LSSM_C RearDrvSeat LINResErr";
CM_ SG_ 674 LSSM_CPumpFail "LSSM_C RearDrvSeat PumpFail";
CM_ SG_ 674 RearDrvSeatMsgStrLvlStat "RearDrvSeatMsgStrLvlStat";
CM_ SG_ 674 LSSM_DLINResErr "LSSM_D RearPassSeat LINResErr";
CM_ SG_ 674 LSSM_DPumpFail "LSSM_D RearPassSeat PumpFail";
CM_ SG_ 674 RearPassSeatMsgStrLvlStat "RearPassSeatMsgStrLvlStat";
CM_ BO_ 676 "SVC_EHC_1
";
CM_ SG_ 676 ECU_ID_WUPREG "n.a.";
CM_ SG_ 676 ID_FN_INQY "n.a.";
CM_ SG_ 676 ID_FN_RQ_BUS "n.a.";
CM_ SG_ 676 NO_CC_MESS_STD "n.a.";
CM_ SG_ 676 WACA "n.a.";
CM_ BO_ 714 "Tester control BMS";
CM_ SG_ 714 CHKSM_IC_SENSOR "Checksum";
CM_ SG_ 714 ALV_IC_SENSOR "Alive Counter";
CM_ SG_ 714 MHU_STAT_AmbientTempRaw "Ambient Temperature Raw";
CM_ SG_ 714 MHU_STAT_FuelLevel "Fuel Level 3 to 63 l  (only for ICE)";
CM_ SG_ 714 MHU_STAT_AmbientTemp "Ambient Temperature filtered";
CM_ SG_ 714 MHU_STAT_CoolantLevelStatus "Low level coolant indicator";
CM_ SG_ 720 CHKSM_FCAM_AESA_Sts "Checksum";
CM_ SG_ 720 ALV_FCAM_AESA_Sts "Alive Counter";
CM_ SG_ 720 FCAM_AESA_DoorUnlock_Req "The signal will be used to unlock the doors once the AESA control is done and the vehicle is brough to stop";
CM_ SG_ 720 FCAM_AESA_ECALL_Req "The signal will be used to triggered the ECALL functionality once the AESA control is done and the vehicle is brough to stop";
CM_ SG_ 720 FCAM_AESA_Status "The signal will be used to indicate the MRM status";
CM_ BO_ 715 "IC_TEMP";
CM_ SG_ 715 TEMP_EX "n.a.";
CM_ SG_ 715 TEMP_EX_UNFILT "Outsude temp raw";
CM_ BO_ 753 "IC STAT AIRBAG";
CM_ SG_ 753 MHU_STAT_AirbagWarnLamp "Status of Airbag telltale warning";
CM_ BO_ 760 "MHU Date Time";
CM_ SG_ 760 DISP_HR "The signal / parameter indicates the current hour.";
CM_ SG_ 760 DISP_MN "The signal / parameter indicates the current minute.";
CM_ SG_ 760 DISP_SEC "The signal / parameter indicates the current second.";
CM_ SG_ 760 DISP_DATE_DAY "The signal / parameter indicates the current day.";
CM_ SG_ 760 DISP_DATE_MON "The signal / parameter indicates the current month.";
CM_ SG_ 760 DISP_DATE_WDAY "The signal   parameter indicates the current day of the week.";
CM_ SG_ 760 DISP_DATE_YR "The signal / parameter indicates the current year.";
CM_ SG_ 760 ST_DISP_CTI_DATE "The signal / parameter indicates the state of the switch summer winter time.";
CM_ BO_ 768 "CCU Status";
CM_ SG_ 768 CCU_STAT_SyncClimateZone "Status dual clima automatic";
CM_ SG_ 768 CCU_STAT_Auto "Status activation of auto mode";
CM_ SG_ 768 CCU_STAT_Aircondition "Aircondition status";
CM_ SG_ 768 CCU_STAT_IonButton "Status if the ionisator is active";
CM_ SG_ 768 CCU_STAT_MaxAc "Status activation of MAX AC mode";
CM_ SG_ 768 CCU_STAT_OnOff "Status On  Off button for clima";
CM_ SG_ 768 CCU_STAT_FanSpeed "Blower settings/Fan Speed for climate system";
CM_ SG_ 768 CCU_STAT_RecircFlap "Recirculation flap status, 100% fresh air, 0% recirculation mode";
CM_ SG_ 768 CCU_STAT_FlapPos "Request for flap position";
CM_ SG_ 768 CCU_STAT_Defrost "Status activation of Defrost mode";
CM_ SG_ 768 CCU_STAT_PTC_Heater "CCU status for PTC heater";
CM_ SG_ 768 CCU_STAT_TempDriver "CCU status for temperature regulationr driver (Display Temperature)";
CM_ SG_ 768 CCU_STAT_TempPassenger "CCU status for temperature regulation  passenger(Display Temperature)";
CM_ BO_ 769 "ADAS_RP_Status";
CM_ SG_ 769 RP_Status "RP_Status";
CM_ BO_ 770 "CCU temprature and pressure";
CM_ SG_ 770 CHKSM_CCU_TEMP_PRESSURE "Checksum";
CM_ SG_ 770 ALV_CCU_TEMP_PRESSURE "Alive Counter";
CM_ SG_ 770 CCU_Pressure_AC "The compressor line pressure.";
CM_ SG_ 770 CCU_InteriorTemp "CCU interiour  temperature. Invalid = 251-255";
CM_ SG_ 770 CCU_TempEx_AC "Outside temperature calculated by CCU";
CM_ SG_ 770 CCU_EvaporatorTemp "Actual evaporator temperature of the HVAC unit. Invalid = 251-255";
CM_ BO_ 773 "VCU Heat Cool Status";
CM_ SG_ 773 HtrMediumOutletTemp "Heater medium outlet temperature (Purpose for PTC) Only BEV car";
CM_ SG_ 773 CcuHtrOnOffSts "PTC status from VCU  Only BEV car";
CM_ SG_ 773 EcompOnOffSts "Electrical compressor on/off status  Only BEV car";
CM_ SG_ 773 HtrMediumInletTemp "Heater medium inlet temperature (Purpose for PTC) Only BEV car";
CM_ SG_ 773 ECompRpm "E-compressor actual RPM  Only BEV car";
CM_ SG_ 773 ECompPowerConsumption "E-compressor actual power consumption  Only BEV car";
CM_ BO_ 774 "CCU Heat Cool Request";
CM_ SG_ 774 CCU_EcompOnOffRequest "Electrical compressor on/off request only for BEV vehicle";
CM_ SG_ 774 CCU_HtrOnOffRequest "PTC on/off request from CCU  only for BEV vehicle";
CM_ SG_ 774 CCU_AcOffCode_CCU "Compressor off code";
CM_ SG_ 774 CCU_CoolPowerDemand "CCU Cooling Demand in kilowat  only for BEV vehicle";
CM_ SG_ 774 CCU_HeatPowerDemand "CCU Heating Demand in kilowat  only for BEV vehicle";
CM_ SG_ 774 CCU_PTCOffCode_CCU "PTC Off Code only for BEV vehicle";
CM_ SG_ 774 CCU_CoolDemand "CCU Cooling  Demand in percentage  only for BEV vehicle";
CM_ SG_ 774 CCU_HeatDemand "CCU Heating Demand in percentage only for BEV vehicle";
CM_ BO_ 775 "CPD Output";
CM_ SG_ 775 CHKSM_CPD_Output_1 "This signal is used for E2E protection. ";
CM_ SG_ 775 ALV_CPD_Output_1 "Alive counter required by AUTOSAR E2E protection.";
CM_ SG_ 775 OUT_Alert_TO_BCM "This signal is used to trigger warning on BCM";
CM_ SG_ 775 CPD_State_information "This signal is used to send state of CPD (enable/disable) to MHU";
CM_ BO_ 784 "CCU_R_Status";
CM_ SG_ 784 CCUR_STAT_IonButton "Status if the ionisator is active";
CM_ SG_ 784 CCUR_STAT_Defrost "Status activation of Defrost mode";
CM_ SG_ 784 CCUR_STAT_Auto "Status activation of auto mode";
CM_ SG_ 784 CCUR_STAT_Aircondition "Aircondition status";
CM_ SG_ 784 CCUR_STAT_FlapPos "Request for flap position";
CM_ SG_ 784 CCUR_STAT_FanSpeed "Blower settings Fan Speed for climate system";
CM_ SG_ 784 CCUR_STAT_PTC_Heater "CCU status for PTC heater";
CM_ SG_ 784 CCUR_STAT_OnOff "Status On  Off button for clima";
CM_ SG_ 784 CCUR_STAT_MaxAc "Status activation of MAX AC mode";
CM_ SG_ 784 CCUR_STAT_SyncClimateZone "Status dual clima automatic";
CM_ SG_ 784 CCUR_STAT_RecircFlap "Recirculation flap status, 100% fresh air, 0% recirculation mode";
CM_ SG_ 784 CCUR_STAT_TempRear "
CCU status for temperature regulationr driver (Display Temperature)";
CM_ BO_ 806 "POD StatusDCDC1";
CM_ SG_ 806 CHSKM_POD_StatusDCDC1 "Check sum";
CM_ SG_ 806 ALV_POD_StatusDCDC1 "Alive counter";
CM_ SG_ 806 POD_statusDCDC "DCDC status";
CM_ BO_ 808 "IC_RELATIVTIME";
CM_ SG_ 808 T_SEC_COU_REL "This counter counts the seconds synchronously to the system clock.";
CM_ SG_ 808 T_DAY_COU_ABSL "Relative time";
CM_ BO_ 809 "BCM_ODO";
CM_ SG_ 809 CRC_BCM_ODO "Checksum";
CM_ SG_ 809 ALIV_BCM_ODO "Alive counter";
CM_ SG_ 809 Odometer_BCM "Odometer infomation for IPC.";
CM_ SG_ 809 SECCAN_BCM_ODO "Seed generated from Secure CAN algorithm";
CM_ BO_ 812 "ASU_HEIGHT_LEVEL";
CM_ SG_ 812 CRC_HGLV_EHC "Applications-CRC-ID = 227 (Dez)";
CM_ SG_ 812 ALIV_HGLV_EHC "Standardabsicherung Alivez�hler laut Definition per Lastenheft Allgemeine Bordnetzkommunikation.";
CM_ SG_ 812 HGLV_RLH_EHC "Das Signal gibt den vom H�henstandsensor an der Hinterachse gemessenen H�henstand in Millimeter (relativ zur Konstruktionslage) an.

Vorzeichenkonvention: 	eingefedertes Rad == negativer H�henstand
  			ausgefedertes Rad == positiver H�henstand";
CM_ SG_ 812 HGLV_RRH_EHC "The signal indicates the height measured in millimeters (relative to the design position) by the height sensor on the rear axle.Sign convention: jammed wheel == negative ride heightSprung wheel == positive ride height";
CM_ SG_ 812 QU_HGLV_RLH_EHC "Qualifier";
CM_ SG_ 812 QU_HGLV_RRH_EHC "Qualifier to the Signal Height HR EHC.";
CM_ BO_ 814 "ADAS_AEB_Status";
CM_ SG_ 814 CRC_AEB_STATUS "Checksum";
CM_ SG_ 814 Alive_AEB_STATUS "Alive Counter";
CM_ SG_ 814 ADAS_AEB_Braking_Progress "Request to activate Brake";
CM_ BO_ 816 "IC_MILEAGE";
CM_ SG_ 816 MILE_KM "Mileage information";
CM_ SG_ 816 FLLV_FUTA "The fuel level of  tank. 255 value invalid";
CM_ SG_ 816 RNG "Calculated range of IPC";
CM_ SG_ 816 ST_FLLV_FUTA_SPAR "State of the tank reserve indicator";
CM_ BO_ 819 "SRR_RR_M Calibration Status";
CM_ SG_ 819 Checksum_0x333 "Checksum";
CM_ SG_ 819 Rolling_Counter_0x333 "Rolling_Counter";
CM_ SG_ 819 ADAS_RadarRight_Cal_Status "BSD right calibration Status";
CM_ SG_ 819 ADAS_RadarLeft_Cal_Status "BSD left calibration Status";
CM_ SG_ 819 ADAS_RadarRight_DynaCal_Status "BSD right dynamic calibration status";
CM_ SG_ 819 ADAS_MasterSRR_check "BSD left dynamic calibration status";
CM_ SG_ 819 ADAS_SlaveSRR_check "Master Corner radar Check";
CM_ SG_ 819 ADAS_RadarLeft_DynaCal_Status "Slave Corner radar Check";
CM_ SG_ 819 ADAS_CalSensorMasterProgress "Master(Left) radar calibration progress when get in";
CM_ SG_ 819 ADAS_CalSensorSlaverProgress "Slaver(Right) radar calibration progress when get in";
CM_ SG_ 819 ADAS_Cal_LeftInstallDeviation "left radar install angle deviation  from auto calibration";
CM_ SG_ 819 ADAS_Cal_RightInstallDeviation "right radar install angle deviation  from auto calibration";
CM_ BO_ 850 "ADAS Auto headlight high beam control and Door Open Warning";
CM_ SG_ 850 CHKSM_ADAS_AHB_DOW "Checksum";
CM_ SG_ 850 ALV_ADAS_AHB_DOW "Alive Counter";
CM_ SG_ 850 ADAS_AHB_check "Auto headlight high beam control Check";
CM_ SG_ 850 ADAS_AHB_state "Auto headlight high beam control State";
CM_ SG_ 850 ADAS_DOW_WarnRight "Right Door Open Warning";
CM_ SG_ 850 ADAS_DOW_WarnLeft "Left Door Open Warning";
CM_ SG_ 850 ADAS_AHB_RBPos "Right High Beam Position Request Signal";
CM_ SG_ 850 ADAS_AHB_LBPos "Left High Beam Position Request Signal";
CM_ BO_ 851 "ADAS Adaptive Cruise Control";
CM_ SG_ 851 ADAS_ACC_State "The signal indicates the status of the Adaptive Cruise Control function";
CM_ SG_ 851 ADAS_ACC_check "Adaptive Cruise Control Check";
CM_ BO_ 852 "MHU ADAS request";
CM_ SG_ 852 CHKSM_MHU_ADAS_req "Checksum";
CM_ SG_ 852 ALV_MHU_ADAS_req "Alive Counter";
CM_ SG_ 852 MHU_FCW_Mode "FCW ABE mode select";
CM_ SG_ 852 MHU_FCW_sens "FCW Sensitivity";
CM_ SG_ 852 MHU_AEB_Mode "AEB Confirmation";
CM_ SG_ 852 MHU_RAEB_Mode "RAEB mode select";
CM_ SG_ 852 MHU_LA_sens "LA Sensitivity (Early   Normal   Late)";
CM_ SG_ 852 MHU_LA_AudWarning "Setting Audible warning for LA On off";
CM_ SG_ 852 MHU_BSD_On "BSD On off";
CM_ SG_ 852 MHU_BSD_AudWarning "Setting Audible warning for BSD On off";
CM_ SG_ 852 MHU_RCTA_On "RCTA On off";
CM_ SG_ 852 MHU_RCTA_sens "RCTA Sensitivity (Early   Normal   Late)";
CM_ SG_ 852 MHU_PA_On "PA On off";
CM_ SG_ 852 MHU_AHB_On "AHB On off";
CM_ SG_ 852 MHU_IA_Mode "IA mode select";
CM_ SG_ 852 MHU_TSR_Mode "TSR Mode selection";
CM_ SG_ 852 MHU_DOW_Mode "Door Open Warning Mode select";
CM_ SG_ 852 MHU_AHB_sens "AHB Sensitivity (Early   Normal   Late)";
CM_ SG_ 852 MHU_LA_Mode "Lane Assistance Mode select";
CM_ SG_ 852 MHU_SET_TSR_AudWarn "TSR Audible Warning On Off";
CM_ SG_ 852 MHU_SET_TSR_SLAert "TSR Speed Limit Alert select";
CM_ SG_ 852 MHU_ESA_ON "ESA function on/off";
CM_ SG_ 852 MHU_ELKA_ON "ELKA function ON/OFF";
CM_ SG_ 880 CRC_MHU_SBR_Status "Checksum";
CM_ SG_ 880 ALV_MHU_SBR_Status "Alive Counter";
CM_ SG_ 880 SBR_STAT_Chime "Status of SBR Chime";
CM_ SG_ 880 SBR_STAT_Telltale "Status of SBR telltale";
CM_ SG_ 880 SBR_STAT_Active "Status of Seatbelt reminder";
CM_ BO_ 886 "USS RPA warning and sensor status";
CM_ SG_ 886 CHKSM_USS_RPA "Checksum";
CM_ SG_ 886 ALV_USS_RPA "Alive Counter";
CM_ SG_ 886 USS_RPA_state "This signal indicates the status of Rear Parking System state";
CM_ SG_ 886 USS_RPA_AlertRLI "This signal indicates the warning level of Rear Left Inner USS";
CM_ SG_ 886 USS_RPA_AlertRLO "This signal indicates the warning level of Rear Left Outer USS";
CM_ SG_ 886 USS_RPA_AlertRRI "This signal indicates the warning level of Rear Right Inner USS";
CM_ SG_ 886 USS_RPA_AlertRRO "This signal indicates the warning level of Rear Right Outer USS";
CM_ SG_ 886 USS_RPA_SensorRLI "This signal indicates the status of Rear Left Inner USS sensor";
CM_ SG_ 886 USS_RPA_SensorRLO "This signal indicates the status of Rear Left Outer USS sensor";
CM_ SG_ 886 USS_RPA_SensorRRI "This signal indicates the status of Rear Right Inner USS sensor";
CM_ SG_ 886 USS_RPA_SensorRRO "This signal indicates the status of Rear Right Outer USS sensor";
CM_ BO_ 887 "USS FPA warning and sensor status";
CM_ SG_ 887 CHKSM_USS_FPA "Checksum";
CM_ SG_ 887 ALV_USS_FPA "Alive Counter";
CM_ SG_ 887 USS_FPA_state "This signal indicates the status of Front Parking System state";
CM_ SG_ 887 USS_FPA_AutoOn_Feed "This signal indicates the status of Auto Front Parking Assist";
CM_ SG_ 887 USS_FPA_AlertFLI "This signal indicates the warning level of Front Left Inner USS";
CM_ SG_ 887 USS_FPA_AlertFLO "This signal indicates the warning level of Front Left Outer USS";
CM_ SG_ 887 USS_FPA_AlertFRI "This signal indicates the warning level of Front Right Inner USS";
CM_ SG_ 887 USS_FPA_AlertFRO "This signal indicates the warning level of Front Right Outer USS";
CM_ SG_ 887 USS_FPA_SensorFLI "This signal indicates the status of Front Left Inner USS sensor";
CM_ SG_ 887 USS_FPA_SensorFLO "This signal indicates the status of Front Left Outer USS sensor";
CM_ SG_ 887 USS_FPA_SensorFRI "This signal indicates the status of Front Right Inner USS sensor";
CM_ SG_ 887 USS_FPA_SensorFRO "This signal indicates the status of Front Right Outer USS sensor";
CM_ BO_ 888 "USS RPA distance of obstacle";
CM_ SG_ 888 CHKSM_RawDist_RPA "Checksum";
CM_ SG_ 888 ALV_RawDist_RPA "Alive counter";
CM_ SG_ 888 USS_RPA_DistRLI "This signal indicates the distance of obstacle";
CM_ SG_ 888 USS_RPA_DistRLO "This signal indicates the distance of obstacle";
CM_ SG_ 888 USS_RPA_DistRRI "This signal indicates the distance of obstacle";
CM_ SG_ 888 USS_RPA_DistRRO "This signal indicates the distance of obstacle";
CM_ BO_ 889 "USS FPA distance of obstacle";
CM_ SG_ 889 CHKSM_RawDist_FPA "Checksum";
CM_ SG_ 889 ALV_RawDist_FPA "Alive counter";
CM_ SG_ 889 USS_FPA_DistFLI "This signal indicates the distance of obstacle";
CM_ SG_ 889 USS_FPA_DistFLO "This signal indicates the distance of obstacle";
CM_ SG_ 889 USS_FPA_DistFRI "This signal indicates the distance of obstacle";
CM_ SG_ 889 USS_FPA_DistFRO "This signal indicates the distance of obstacle";
BA_DEF_ BO_  "GenMsgSendType" ENUM  "Cyclic","NotUsed","NotUsed","NotUsed","NotUsed","NotUsed","NotUsed","IfActive","NoMsgSendType","NotUsed";
BA_DEF_ BO_  "GenMsgILSupport" ENUM  "No","Yes";
BA_DEF_ BO_  "DiagResponse" ENUM  "No","Yes";
BA_DEF_ BO_  "DiagRequest" ENUM  "No","Yes";
BA_DEF_ BO_  "NmAsrMessage" ENUM  "No","Yes";
BA_DEF_ BO_  "DiagState" ENUM  "No","Yes";
BA_DEF_ BO_  "DiagUudtResponse" ENUM  "False","True";
BA_DEF_ BO_  "GenMsgStartDelayTime" INT 0 65535;
BA_DEF_ BO_  "GenMsgDelayTime" INT 0 0;
BA_DEF_ BO_  "GenMsgNrOfRepetition" INT 0 0;
BA_DEF_ BO_  "GenMsgCycleTimeFast" INT 0 0;
BA_DEF_ BO_  "GenMsgCycleTime" INT 0 0;
BA_DEF_ SG_  "GenSigSendType" ENUM  "Cyclic","OnWrite","OnWriteWithRepetition","OnChange","OnChangeWithRepetition","IfActive","IfActiveWithRepetition","NoSigSendType","NotUsed","NotUsed","NotUsed","NotUsed","NotUsed";
BA_DEF_ SG_  "InvalidValue" STRING ;
BA_DEF_ SG_  "GenSigStartValue" INT 0 0;
BA_DEF_ SG_  "GenSigTimeoutTime_ALL" INT 0 65535;
BA_DEF_DEF_  "GenMsgSendType" "NoMsgSendType";
BA_DEF_DEF_  "GenMsgILSupport" "Yes";
BA_DEF_DEF_  "DiagResponse" "No";
BA_DEF_DEF_  "DiagRequest" "No";
BA_DEF_DEF_  "NmAsrMessage" "No";
BA_DEF_DEF_  "DiagState" "No";
BA_DEF_DEF_  "DiagUudtResponse" "False";
BA_DEF_DEF_  "GenMsgStartDelayTime" 0;
BA_DEF_DEF_  "GenMsgDelayTime" 0;
BA_DEF_DEF_  "GenMsgNrOfRepetition" 0;
BA_DEF_DEF_  "GenMsgCycleTimeFast" 0;
BA_DEF_DEF_  "GenMsgCycleTime" 0;
BA_DEF_DEF_  "GenSigSendType" "Cyclic";
BA_DEF_DEF_  "InvalidValue" "";
BA_DEF_DEF_  "GenSigStartValue" 0;
BA_DEF_DEF_  "GenSigTimeoutTime_ALL" 0;
BA_ "GenMsgSendType" BO_ 521 0;
BA_ "GenMsgCycleTime" BO_ 521 100;
BA_ "GenMsgCycleTime" BO_ 522 100;
BA_ "GenMsgSendType" BO_ 522 0;
BA_ "GenMsgCycleTime" BO_ 523 100;
BA_ "GenMsgCycleTimeFast" BO_ 523 30;
BA_ "GenMsgNrOfRepetition" BO_ 523 3;
BA_ "GenMsgSendType" BO_ 523 0;
BA_ "GenMsgCycleTime" BO_ 524 100;
BA_ "GenMsgSendType" BO_ 524 0;
BA_ "GenMsgCycleTime" BO_ 525 20;
BA_ "GenMsgSendType" BO_ 525 0;
BA_ "GenMsgCycleTime" BO_ 527 50;
BA_ "GenMsgSendType" BO_ 527 0;
BA_ "GenMsgCycleTime" BO_ 528 40;
BA_ "GenMsgSendType" BO_ 528 0;
BA_ "GenMsgCycleTime" BO_ 533 50;
BA_ "GenMsgSendType" BO_ 533 0;
BA_ "GenMsgCycleTime" BO_ 537 20;
BA_ "GenMsgILSupport" BO_ 537 0;
BA_ "GenMsgSendType" BO_ 537 0;
BA_ "GenMsgSendType" BO_ 540 0;
BA_ "GenMsgCycleTime" BO_ 540 100;
BA_ "GenMsgCycleTimeFast" BO_ 544 50;
BA_ "GenMsgNrOfRepetition" BO_ 544 3;
BA_ "GenMsgCycleTime" BO_ 545 200;
BA_ "GenMsgSendType" BO_ 545 0;
BA_ "GenMsgCycleTime" BO_ 546 100;
BA_ "GenMsgSendType" BO_ 546 0;
BA_ "GenMsgStartDelayTime" BO_ 546 10;
BA_ "GenMsgCycleTime" BO_ 547 20;
BA_ "GenMsgSendType" BO_ 547 0;
BA_ "GenMsgCycleTime" BO_ 548 100;
BA_ "GenMsgILSupport" BO_ 548 0;
BA_ "GenMsgSendType" BO_ 548 0;
BA_ "GenMsgCycleTime" BO_ 561 20;
BA_ "GenMsgSendType" BO_ 561 0;
BA_ "GenMsgCycleTime" BO_ 565 100;
BA_ "GenMsgSendType" BO_ 565 0;
BA_ "GenMsgCycleTime" BO_ 569 20;
BA_ "GenMsgSendType" BO_ 569 0;
BA_ "GenMsgSendType" BO_ 570 0;
BA_ "GenMsgCycleTime" BO_ 570 20;
BA_ "GenMsgSendType" BO_ 571 0;
BA_ "GenMsgCycleTime" BO_ 571 20;
BA_ "GenMsgCycleTime" BO_ 578 20;
BA_ "GenMsgSendType" BO_ 578 0;
BA_ "GenMsgCycleTime" BO_ 584 20;
BA_ "GenMsgSendType" BO_ 584 0;
BA_ "GenMsgCycleTime" BO_ 592 100;
BA_ "GenMsgILSupport" BO_ 592 0;
BA_ "GenMsgSendType" BO_ 592 0;
BA_ "GenMsgCycleTime" BO_ 593 20;
BA_ "GenMsgSendType" BO_ 593 0;
BA_ "GenMsgCycleTime" BO_ 596 20;
BA_ "GenMsgSendType" BO_ 596 0;
BA_ "GenMsgCycleTime" BO_ 597 20;
BA_ "GenMsgSendType" BO_ 597 0;
BA_ "GenMsgCycleTime" BO_ 598 50;
BA_ "GenMsgSendType" BO_ 598 0;
BA_ "GenMsgCycleTime" BO_ 618 200;
BA_ "GenMsgSendType" BO_ 618 0;
BA_ "GenMsgCycleTime" BO_ 619 100;
BA_ "GenMsgSendType" BO_ 619 0;
BA_ "GenMsgCycleTime" BO_ 620 100;
BA_ "GenMsgSendType" BO_ 620 0;
BA_ "GenMsgCycleTime" BO_ 641 20;
BA_ "GenMsgSendType" BO_ 641 0;
BA_ "GenMsgCycleTime" BO_ 649 20;
BA_ "GenMsgSendType" BO_ 649 0;
BA_ "GenMsgCycleTime" BO_ 654 100;
BA_ "GenMsgSendType" BO_ 654 0;
BA_ "GenMsgCycleTime" BO_ 657 20;
BA_ "GenMsgSendType" BO_ 657 0;
BA_ "GenMsgCycleTime" BO_ 673 80;
BA_ "GenMsgSendType" BO_ 673 0;
BA_ "GenMsgCycleTime" BO_ 674 80;
BA_ "GenMsgSendType" BO_ 674 0;
BA_ "GenMsgCycleTime" BO_ 676 1000;
BA_ "GenMsgCycleTime" BO_ 714 100;
BA_ "GenMsgSendType" BO_ 714 0;
BA_ "GenMsgCycleTime" BO_ 720 100;
BA_ "GenMsgSendType" BO_ 720 0;
BA_ "GenMsgCycleTime" BO_ 715 100;
BA_ "GenMsgSendType" BO_ 715 0;
BA_ "GenMsgCycleTime" BO_ 753 100;
BA_ "GenMsgSendType" BO_ 753 0;
BA_ "GenMsgCycleTime" BO_ 760 1000;
BA_ "GenMsgSendType" BO_ 760 0;
BA_ "GenMsgSendType" BO_ 768 0;
BA_ "GenMsgCycleTime" BO_ 768 1000;
BA_ "GenMsgCycleTimeFast" BO_ 768 20;
BA_ "GenMsgNrOfRepetition" BO_ 768 2;
BA_ "GenMsgCycleTime" BO_ 769 50;
BA_ "GenMsgSendType" BO_ 769 0;
BA_ "GenMsgCycleTime" BO_ 770 1000;
BA_ "GenMsgSendType" BO_ 770 0;
BA_ "GenMsgStartDelayTime" BO_ 770 25;
BA_ "GenMsgCycleTime" BO_ 773 100;
BA_ "GenMsgSendType" BO_ 773 0;
BA_ "GenMsgCycleTime" BO_ 774 100;
BA_ "GenMsgSendType" BO_ 774 0;
BA_ "GenMsgStartDelayTime" BO_ 774 5;
BA_ "GenMsgCycleTime" BO_ 775 1000;
BA_ "GenMsgSendType" BO_ 775 0;
BA_ "GenMsgSendType" BO_ 784 0;
BA_ "GenMsgCycleTime" BO_ 784 1000;
BA_ "GenMsgCycleTimeFast" BO_ 784 20;
BA_ "GenMsgNrOfRepetition" BO_ 784 2;
BA_ "GenMsgCycleTime" BO_ 806 100;
BA_ "GenMsgSendType" BO_ 806 0;
BA_ "GenMsgCycleTime" BO_ 808 1000;
BA_ "GenMsgSendType" BO_ 808 0;
BA_ "GenMsgCycleTime" BO_ 809 1000;
BA_ "GenMsgSendType" BO_ 809 0;
BA_ "GenMsgCycleTime" BO_ 812 200;
BA_ "GenMsgSendType" BO_ 812 0;
BA_ "GenMsgSendType" BO_ 814 0;
BA_ "GenMsgCycleTime" BO_ 814 20;
BA_ "GenMsgCycleTime" BO_ 816 100;
BA_ "GenMsgSendType" BO_ 816 0;
BA_ "GenMsgSendType" BO_ 819 0;
BA_ "GenMsgCycleTime" BO_ 819 50;
BA_ "GenMsgCycleTime" BO_ 850 50;
BA_ "GenMsgSendType" BO_ 850 0;
BA_ "GenMsgCycleTime" BO_ 851 50;
BA_ "GenMsgSendType" BO_ 851 0;
BA_ "GenMsgCycleTime" BO_ 852 50;
BA_ "GenMsgSendType" BO_ 852 0;
BA_ "GenMsgCycleTime" BO_ 880 300;
BA_ "GenMsgSendType" BO_ 880 0;
BA_ "GenMsgSendType" BO_ 886 0;
BA_ "GenMsgCycleTime" BO_ 886 200;
BA_ "GenMsgSendType" BO_ 887 0;
BA_ "GenMsgCycleTime" BO_ 887 200;
BA_ "GenMsgSendType" BO_ 888 0;
BA_ "GenMsgCycleTime" BO_ 888 200;
BA_ "GenMsgSendType" BO_ 889 0;
BA_ "GenMsgCycleTime" BO_ 889 200;
BA_ "GenSigTimeoutTime_ALL" SG_ 521 CHKSM_PAS_RAEB 500;
BA_ "GenSigTimeoutTime_ALL" SG_ 521 ALV_PAS_RAEB 500;
BA_ "GenSigTimeoutTime_ALL" SG_ 521 PAS_RAEB_check 500;
BA_ "InvalidValue" SG_ 521 PAS_RAEB_check "3h";
BA_ "GenSigStartValue" SG_ 521 PAS_RAEB_State 1;
BA_ "GenSigTimeoutTime_ALL" SG_ 521 PAS_RAEB_State 500;
BA_ "InvalidValue" SG_ 521 PAS_RAEB_State "3h";
BA_ "GenSigTimeoutTime_ALL" SG_ 521 PAS_RAEB_Warning 500;
BA_ "InvalidValue" SG_ 521 PAS_RAEB_Warning "3h";
BA_ "GenSigStartValue" SG_ 522 ETG_Lift_Gate_Status 7;
BA_ "GenSigTimeoutTime_ALL" SG_ 522 ETG_Lift_Gate_Status 500;
BA_ "InvalidValue" SG_ 522 ETG_Lift_Gate_Status "7h";
BA_ "GenSigStartValue" SG_ 522 ETG_Power_Latch_Status 7;
BA_ "GenSigTimeoutTime_ALL" SG_ 522 ETG_Power_Latch_Status 500;
BA_ "InvalidValue" SG_ 522 ETG_Power_Latch_Status "7h";
BA_ "GenSigStartValue" SG_ 522 ETG_Latch_Segment 3;
BA_ "GenSigTimeoutTime_ALL" SG_ 522 ETG_Latch_Segment 500;
BA_ "InvalidValue" SG_ 522 ETG_Latch_Segment "3h";
BA_ "GenSigTimeoutTime_ALL" SG_ 522 ETG_Opening_Percentage 500;
BA_ "InvalidValue" SG_ 522 ETG_Opening_Percentage "FFh";
BA_ "GenSigTimeoutTime_ALL" SG_ 522 ETG_DSW_Status 500;
BA_ "InvalidValue" SG_ 522 ETG_DSW_Status "null";
BA_ "GenSigTimeoutTime_ALL" SG_ 522 ETG_GSW_Status 500;
BA_ "InvalidValue" SG_ 522 ETG_GSW_Status "null";
BA_ "GenSigTimeoutTime_ALL" SG_ 522 ETG_LTS_Status 500;
BA_ "InvalidValue" SG_ 522 ETG_LTS_Status "null";
BA_ "GenSigTimeoutTime_ALL" SG_ 522 ETG_RTS_Status 500;
BA_ "InvalidValue" SG_ 522 ETG_RTS_Status "null";
BA_ "GenSigTimeoutTime_ALL" SG_ 522 ETG_HAL_Status 500;
BA_ "InvalidValue" SG_ 522 ETG_HAL_Status "null";
BA_ "GenSigTimeoutTime_ALL" SG_ 522 ETG_FUL_Status 500;
BA_ "InvalidValue" SG_ 522 ETG_FUL_Status "null";
BA_ "GenSigTimeoutTime_ALL" SG_ 522 ETG_AJR_Status 500;
BA_ "InvalidValue" SG_ 522 ETG_AJR_Status "null";
BA_ "GenSigTimeoutTime_ALL" SG_ 522 ETG_NTL_Status 500;
BA_ "InvalidValue" SG_ 522 ETG_NTL_Status "null";
BA_ "GenSigTimeoutTime_ALL" SG_ 522 ETG_ERR_Voltage 500;
BA_ "InvalidValue" SG_ 522 ETG_ERR_Voltage "null";
BA_ "GenSigTimeoutTime_ALL" SG_ 522 ETG_ERR_Left_Motor 500;
BA_ "InvalidValue" SG_ 522 ETG_ERR_Left_Motor "null";
BA_ "GenSigTimeoutTime_ALL" SG_ 522 ETG_ERR_Right_Motor 500;
BA_ "InvalidValue" SG_ 522 ETG_ERR_Right_Motor "null";
BA_ "GenSigTimeoutTime_ALL" SG_ 522 ETG_ERR_Latch 500;
BA_ "InvalidValue" SG_ 522 ETG_ERR_Latch "null";
BA_ "GenSigTimeoutTime_ALL" SG_ 522 ETG_ERR_Hall 500;
BA_ "InvalidValue" SG_ 522 ETG_ERR_Hall "null";
BA_ "GenSigTimeoutTime_ALL" SG_ 522 ETG_Lift_Motor_Stall 500;
BA_ "InvalidValue" SG_ 522 ETG_Lift_Motor_Stall "null";
BA_ "GenSigTimeoutTime_ALL" SG_ 522 ETG_Lift_Motor_AntiPinch 500;
BA_ "InvalidValue" SG_ 522 ETG_Lift_Motor_AntiPinch "null";
BA_ "GenSigTimeoutTime_ALL" SG_ 522 ETG_Lift_Motor_Thermal 500;
BA_ "InvalidValue" SG_ 522 ETG_Lift_Motor_Thermal "null";
BA_ "GenSigTimeoutTime_ALL" SG_ 522 ETG_Power_Latch_Thermal 500;
BA_ "InvalidValue" SG_ 522 ETG_Power_Latch_Thermal "null";
BA_ "GenSigTimeoutTime_ALL" SG_ 522 ETG_Abuse_Protection 500;
BA_ "InvalidValue" SG_ 522 ETG_Abuse_Protection "null";
BA_ "GenSigTimeoutTime_ALL" SG_ 523 FKS_RespError 500;
BA_ "InvalidValue" SG_ 523 FKS_RespError "null";
BA_ "GenSigTimeoutTime_ALL" SG_ 523 FKS_OpenReq 500;
BA_ "InvalidValue" SG_ 523 FKS_OpenReq "null";
BA_ "GenSigTimeoutTime_ALL" SG_ 523 FKS_HWError 500;
BA_ "InvalidValue" SG_ 523 FKS_HWError "null";
BA_ "GenSigTimeoutTime_ALL" SG_ 523 FKS_AntennaError 500;
BA_ "InvalidValue" SG_ 523 FKS_AntennaError "null";
BA_ "GenSigTimeoutTime_ALL" SG_ 523 FKS_OverVolDected 500;
BA_ "InvalidValue" SG_ 523 FKS_OverVolDected "null";
BA_ "GenSigTimeoutTime_ALL" SG_ 523 FKS_UnderVolDected 500;
BA_ "InvalidValue" SG_ 523 FKS_UnderVolDected "null";
BA_ "GenSigTimeoutTime_ALL" SG_ 523 FKS_activate_deactivate 500;
BA_ "InvalidValue" SG_ 523 FKS_activate_deactivate "null";
BA_ "GenSigTimeoutTime_ALL" SG_ 524 CHKSM_IC_ODO 500;
BA_ "InvalidValue" SG_ 524 CHKSM_IC_ODO "null";
BA_ "GenSigTimeoutTime_ALL" SG_ 524 ALIV_IC_ODO 500;
BA_ "InvalidValue" SG_ 524 ALIV_IC_ODO "Fh";
BA_ "GenSigTimeoutTime_ALL" SG_ 524 MHU_Odometer_IC 500;
BA_ "InvalidValue" SG_ 524 MHU_Odometer_IC "FFFFFh";
BA_ "GenSigTimeoutTime_ALL" SG_ 525 CHKSM_IDB_STATUS 200;
BA_ "InvalidValue" SG_ 525 CHKSM_IDB_STATUS "null";
BA_ "GenSigTimeoutTime_ALL" SG_ 525 ALV_IDB_STATUS 200;
BA_ "InvalidValue" SG_ 525 ALV_IDB_STATUS "Fh";
BA_ "GenSigTimeoutTime_ALL" SG_ 525 ESPTransRequestType 200;
BA_ "InvalidValue" SG_ 525 ESPTransRequestType "null";
BA_ "GenSigTimeoutTime_ALL" SG_ 525 ABSFault 200;
BA_ "InvalidValue" SG_ 525 ABSFault "null";
BA_ "GenSigTimeoutTime_ALL" SG_ 525 ABSActive 200;
BA_ "InvalidValue" SG_ 525 ABSActive "null";
BA_ "GenSigTimeoutTime_ALL" SG_ 525 VehicleSpd 200;
BA_ "InvalidValue" SG_ 525 VehicleSpd "null";
BA_ "GenSigTimeoutTime_ALL" SG_ 525 MCPressureSts 200;
BA_ "InvalidValue" SG_ 525 MCPressureSts "null";
BA_ "GenSigTimeoutTime_ALL" SG_ 525 VehicleSpdSts 200;
BA_ "InvalidValue" SG_ 525 VehicleSpdSts "null";
BA_ "GenSigStartValue" SG_ 525 MCPressure 21;
BA_ "GenSigTimeoutTime_ALL" SG_ 525 MCPressure 200;
BA_ "InvalidValue" SG_ 525 MCPressure "FFh";
BA_ "GenSigTimeoutTime_ALL" SG_ 525 BRAKE_LightonRequestEPBi 200;
BA_ "InvalidValue" SG_ 525 BRAKE_LightonRequestEPBi "null";
BA_ "GenSigTimeoutTime_ALL" SG_ 525 VDCActive 200;
BA_ "InvalidValue" SG_ 525 VDCActive "null";
BA_ "GenSigTimeoutTime_ALL" SG_ 525 TCSActive 200;
BA_ "InvalidValue" SG_ 525 TCSActive "null";
BA_ "GenSigTimeoutTime_ALL" SG_ 525 TCSAvailable 200;
BA_ "InvalidValue" SG_ 525 TCSAvailable "null";
BA_ "GenSigTimeoutTime_ALL" SG_ 525 IDBActive 200;
BA_ "InvalidValue" SG_ 525 IDBActive "null";
BA_ "GenSigTimeoutTime_ALL" SG_ 525 IDBFault 200;
BA_ "InvalidValue" SG_ 525 IDBFault "null";
BA_ "GenSigTimeoutTime_ALL" SG_ 525 IDB_Power_Stage 200;
BA_ "InvalidValue" SG_ 525 IDB_Power_Stage "null";
BA_ "GenSigTimeoutTime_ALL" SG_ 527 CHKSM_ADAS_BCM_Status 500;
BA_ "InvalidValue" SG_ 527 CHKSM_ADAS_BCM_Status "null";
BA_ "GenSigTimeoutTime_ALL" SG_ 527 ALIVE_ADAS_BCM_Status 500;
BA_ "InvalidValue" SG_ 527 ALIVE_ADAS_BCM_Status "Fh";
BA_ "GenSigTimeoutTime_ALL" SG_ 527 ADAS_BCM_HeadlightReq 500;
BA_ "GenSigTimeoutTime_ALL" SG_ 527 ADAS_BCM_FoldMirrorReq 500;
BA_ "GenSigTimeoutTime_ALL" SG_ 527 ADAS_BCM_Status 500;
BA_ "InvalidValue" SG_ 527 ADAS_BCM_Status "null";
BA_ "GenSigTimeoutTime_ALL" SG_ 527 ADAS_BCM_IndicatorlightReq 500;
BA_ "InvalidValue" SG_ 527 ADAS_BCM_IndicatorlightReq "null";
BA_ "GenSigTimeoutTime_ALL" SG_ 527 SECCAN_ADAS_BCM_Sts 500;
BA_ "GenSigTimeoutTime_ALL" SG_ 528 CHKSM_RCU_Status 400;
BA_ "InvalidValue" SG_ 528 CHKSM_RCU_Status "null";
BA_ "GenSigTimeoutTime_ALL" SG_ 528 ALV_RCU_Status 400;
BA_ "InvalidValue" SG_ 528 ALV_RCU_Status "Fh";
BA_ "GenSigTimeoutTime_ALL" SG_ 528 RCU_DAA_NoOpDoorOpen_1 400;
BA_ "InvalidValue" SG_ 528 RCU_DAA_NoOpDoorOpen_1 "null";
BA_ "GenSigTimeoutTime_ALL" SG_ 528 RCU_EPBParkingStatus 400;
BA_ "InvalidValue" SG_ 528 RCU_EPBParkingStatus "3h";
BA_ "GenSigTimeoutTime_ALL" SG_ 528 EPB_Swch_Mafnc 400;
BA_ "InvalidValue" SG_ 528 EPB_Swch_Mafnc "null";
BA_ "GenSigTimeoutTime_ALL" SG_ 528 RCU_ParkBrkApplied_1 400;
BA_ "InvalidValue" SG_ 528 RCU_ParkBrkApplied_1 "null";
BA_ "GenSigTimeoutTime_ALL" SG_ 528 RCU_ReleaseEPB_Wo_PressBrk_1 400;
BA_ "InvalidValue" SG_ 528 RCU_ReleaseEPB_Wo_PressBrk_1 "null";
BA_ "GenSigTimeoutTime_ALL" SG_ 528 RCU_BrkForceNotEnough_1 400;
BA_ "InvalidValue" SG_ 528 RCU_BrkForceNotEnough_1 "null";
BA_ "GenSigTimeoutTime_ALL" SG_ 528 RCU_ParkOnSteepInclination_1 400;
BA_ "InvalidValue" SG_ 528 RCU_ParkOnSteepInclination_1 "null";
BA_ "GenSigTimeoutTime_ALL" SG_ 528 RCU_ECD_RWU_active_1 400;
BA_ "InvalidValue" SG_ 528 RCU_ECD_RWU_active_1 "null";
BA_ "GenSigTimeoutTime_ALL" SG_ 528 RCU_EHandBrk_fault_1 400;
BA_ "InvalidValue" SG_ 528 RCU_EHandBrk_fault_1 "null";
BA_ "GenSigTimeoutTime_ALL" SG_ 528 RCU_BRAKE_LightonRequestEPBi 400;
BA_ "InvalidValue" SG_ 528 RCU_BRAKE_LightonRequestEPBi "null";
BA_ "GenSigTimeoutTime_ALL" SG_ 533 Checksum_0x215 500;
BA_ "InvalidValue" SG_ 533 Checksum_0x215 "null";
BA_ "GenSigTimeoutTime_ALL" SG_ 533 Rolling_Counter_0x215 500;
BA_ "InvalidValue" SG_ 533 Rolling_Counter_0x215 "Fh";
BA_ "GenSigTimeoutTime_ALL" SG_ 533 BMS_BatBalance_ERR 500;
BA_ "InvalidValue" SG_ 533 BMS_BatBalance_ERR "null";
BA_ "GenSigTimeoutTime_ALL" SG_ 533 BMS_Balance_STS 500;
BA_ "InvalidValue" SG_ 533 BMS_Balance_STS "null";
BA_ "GenSigTimeoutTime_ALL" SG_ 533 BMS_IGN_Sts 500;
BA_ "InvalidValue" SG_ 533 BMS_IGN_Sts "null";
BA_ "GenSigTimeoutTime_ALL" SG_ 533 BMS_HWCrash_Sts 500;
BA_ "InvalidValue" SG_ 533 BMS_HWCrash_Sts "null";
BA_ "GenSigTimeoutTime_ALL" SG_ 533 BMS_HVIL_STS 500;
BA_ "InvalidValue" SG_ 533 BMS_HVIL_STS "3h";
BA_ "GenSigTimeoutTime_ALL" SG_ 533 BMS_HVOnOff_STS 500;
BA_ "InvalidValue" SG_ 533 BMS_HVOnOff_STS "null";
BA_ "GenSigTimeoutTime_ALL" SG_ 533 BMS_ERR_LEV 500;
BA_ "InvalidValue" SG_ 533 BMS_ERR_LEV "null";
BA_ "GenSigTimeoutTime_ALL" SG_ 533 BMS_SocActual_EST 500;
BA_ "InvalidValue" SG_ 533 BMS_SocActual_EST "3FFh";
BA_ "GenSigTimeoutTime_ALL" SG_ 533 BMS_Sys_STS 500;
BA_ "InvalidValue" SG_ 533 BMS_Sys_STS "8h";
BA_ "GenSigTimeoutTime_ALL" SG_ 533 BMS_ISU_Status 500;
BA_ "InvalidValue" SG_ 533 BMS_ISU_Status "null";
BA_ "GenSigStartValue" SG_ 533 BMS_SOH 54;
BA_ "GenSigTimeoutTime_ALL" SG_ 533 BMS_SOH 500;
BA_ "InvalidValue" SG_ 533 BMS_SOH "FFh";
BA_ "GenSigStartValue" SG_ 533 BMS_SOE 54;
BA_ "GenSigTimeoutTime_ALL" SG_ 533 BMS_SOE 500;
BA_ "InvalidValue" SG_ 533 BMS_SOE "FFh";
BA_ "GenSigTimeoutTime_ALL" SG_ 533 BMS_HV_Sts 500;
BA_ "GenSigTimeoutTime_ALL" SG_ 537 CHSKM_VCU_PTControl 200;
BA_ "InvalidValue" SG_ 537 CHSKM_VCU_PTControl "null";
BA_ "GenSigTimeoutTime_ALL" SG_ 537 ALV_VCU_PTControl 200;
BA_ "InvalidValue" SG_ 537 ALV_VCU_PTControl "Fh";
BA_ "GenSigTimeoutTime_ALL" SG_ 537 VCU_ChargeAllow 200;
BA_ "InvalidValue" SG_ 537 VCU_ChargeAllow "null";
BA_ "InvalidValue" SG_ 540 FCAM_AEB_Warning "3h";
BA_ "GenSigTimeoutTime_ALL" SG_ 540 FCAM_AEB_Warning 500;
BA_ "GenSigStartValue" SG_ 540 FCAM_AEB_State 1;
BA_ "GenSigTimeoutTime_ALL" SG_ 540 FCAM_AEB_State 500;
BA_ "InvalidValue" SG_ 540 FCAM_AEB_State "3h";
BA_ "GenSigTimeoutTime_ALL" SG_ 540 FCAM_AEB_check 500;
BA_ "InvalidValue" SG_ 540 FCAM_AEB_check "3h";
BA_ "GenSigSendType" SG_ 544 MHU_SET_CCUR_AirCondition 2;
BA_ "InvalidValue" SG_ 544 MHU_SET_CCUR_AirCondition "3h";
BA_ "GenSigSendType" SG_ 544 MHU_SET_CCUR_AutoAC 2;
BA_ "InvalidValue" SG_ 544 MHU_SET_CCUR_AutoAC "3h";
BA_ "GenSigSendType" SG_ 544 MHU_SET_CCUR_RearLock 2;
BA_ "InvalidValue" SG_ 544 MHU_SET_CCUR_RearLock "3h";
BA_ "GenSigSendType" SG_ 544 MHU_SET_CCUR_MaxAc 2;
BA_ "InvalidValue" SG_ 544 MHU_SET_CCUR_MaxAc "3h";
BA_ "GenSigSendType" SG_ 544 MHU_SET_CCUR_FanSpeed 2;
BA_ "GenSigStartValue" SG_ 544 MHU_SET_CCUR_FanSpeed 3;
BA_ "InvalidValue" SG_ 544 MHU_SET_CCUR_FanSpeed "7h";
BA_ "GenSigSendType" SG_ 544 MHU_SET_CCUR_Recirculation 2;
BA_ "GenSigStartValue" SG_ 544 MHU_SET_CCUR_Recirculation 1;
BA_ "InvalidValue" SG_ 544 MHU_SET_CCUR_Recirculation "3h";
BA_ "GenSigSendType" SG_ 544 MHU_SET_CCUR_Ion 2;
BA_ "InvalidValue" SG_ 544 MHU_SET_CCUR_Ion "3h";
BA_ "GenSigSendType" SG_ 544 MHU_SET_CCUR_FlapPosition 2;
BA_ "InvalidValue" SG_ 544 MHU_SET_CCUR_FlapPosition "4h";
BA_ "GenSigSendType" SG_ 544 MHU_SET_CCUR_SyncClimateZone 2;
BA_ "InvalidValue" SG_ 544 MHU_SET_CCUR_SyncClimateZone "3h";
BA_ "GenSigSendType" SG_ 544 MHU_SET_CCUR_TempRear 2;
BA_ "GenSigStartValue" SG_ 544 MHU_SET_CCUR_TempRear 40;
BA_ "InvalidValue" SG_ 544 MHU_SET_CCUR_TempRear "FFh";
BA_ "GenSigSendType" SG_ 544 MHU_SET_CCUR_FrontDefrost 2;
BA_ "InvalidValue" SG_ 544 MHU_SET_CCUR_FrontDefrost "3h";
BA_ "GenSigTimeoutTime_ALL" SG_ 545 CCUR_Req_AirCondition 1000;
BA_ "InvalidValue" SG_ 545 CCUR_Req_AirCondition "3h";
BA_ "GenSigTimeoutTime_ALL" SG_ 545 CCUR_AirDistribFlapActPos 1000;
BA_ "InvalidValue" SG_ 545 CCUR_AirDistribFlapActPos "null";
BA_ "GenSigTimeoutTime_ALL" SG_ 545 CCUR_TempFlapActPos 1000;
BA_ "InvalidValue" SG_ 545 CCUR_TempFlapActPos "null";
BA_ "GenSigTimeoutTime_ALL" SG_ 545 SECCAN_CCUR 1000;
BA_ "InvalidValue" SG_ 545 SECCAN_CCUR "null";
BA_ "InvalidValue" SG_ 546 FRONT_SET_Rear_AirCondition "3h";
BA_ "InvalidValue" SG_ 546 SECCAN_CCUF "null";
BA_ "GenSigTimeoutTime_ALL" SG_ 547 NDoorFLVehicleLocked 200;
BA_ "InvalidValue" SG_ 547 NDoorFLVehicleLocked "1h";
BA_ "GenSigTimeoutTime_ALL" SG_ 547 NDoorFLVehicleMoving 200;
BA_ "InvalidValue" SG_ 547 NDoorFLVehicleMoving "1h";
BA_ "GenSigTimeoutTime_ALL" SG_ 547 NDoorFLOpenInvRequested 200;
BA_ "InvalidValue" SG_ 547 NDoorFLOpenInvRequested "1h";
BA_ "GenSigStartValue" SG_ 547 NDoorFLOpenRequested 3;
BA_ "GenSigTimeoutTime_ALL" SG_ 547 NDoorFLOpenRequested 200;
BA_ "InvalidValue" SG_ 547 NDoorFLOpenRequested "2h";
BA_ "GenSigStartValue" SG_ 547 NDoorFLChildLocked 3;
BA_ "GenSigTimeoutTime_ALL" SG_ 547 NDoorFLChildLocked 200;
BA_ "InvalidValue" SG_ 547 NDoorFLChildLocked "1h";
BA_ "GenSigStartValue" SG_ 547 NDoorFLVehicleCrash 3;
BA_ "GenSigTimeoutTime_ALL" SG_ 547 NDoorFLVehicleCrash 200;
BA_ "InvalidValue" SG_ 547 NDoorFLVehicleCrash "1h";
BA_ "GenSigTimeoutTime_ALL" SG_ 547 NDoorFLCommandCounter 200;
BA_ "InvalidValue" SG_ 547 NDoorFLCommandCounter "null";
BA_ "GenSigTimeoutTime_ALL" SG_ 547 NDoorFLCloseInvRequested 200;
BA_ "InvalidValue" SG_ 547 NDoorFLCloseInvRequested "null";
BA_ "GenSigTimeoutTime_ALL" SG_ 547 NDoorFLCloseRequested 200;
BA_ "InvalidValue" SG_ 547 NDoorFLCloseRequested "null";
BA_ "GenSigTimeoutTime_ALL" SG_ 548 CHSKM_VCU_BMS_Thermal_FB 500;
BA_ "InvalidValue" SG_ 548 CHSKM_VCU_BMS_Thermal_FB "null";
BA_ "GenSigTimeoutTime_ALL" SG_ 548 ALIV_VCU_BMS_Thermal_FB 500;
BA_ "InvalidValue" SG_ 548 ALIV_VCU_BMS_Thermal_FB "Fh";
BA_ "GenSigTimeoutTime_ALL" SG_ 548 VCU_BMS_PTCOnOff_Sts 500;
BA_ "InvalidValue" SG_ 548 VCU_BMS_PTCOnOff_Sts "null";
BA_ "GenSigTimeoutTime_ALL" SG_ 548 VCU_BMS_ValveOnOff_Sts 500;
BA_ "InvalidValue" SG_ 548 VCU_BMS_ValveOnOff_Sts "null";
BA_ "GenSigTimeoutTime_ALL" SG_ 548 VCU_BMS_PumpFB 500;
BA_ "InvalidValue" SG_ 548 VCU_BMS_PumpFB "null";
BA_ "GenSigStartValue" SG_ 561 NDoorFLHomeSignal 1;
BA_ "GenSigTimeoutTime_ALL" SG_ 561 NDoorFLHomeSignal 200;
BA_ "InvalidValue" SG_ 561 NDoorFLHomeSignal "null";
BA_ "GenSigStartValue" SG_ 561 NDoorFLSecondarySignal 1;
BA_ "GenSigTimeoutTime_ALL" SG_ 561 NDoorFLSecondarySignal 200;
BA_ "InvalidValue" SG_ 561 NDoorFLSecondarySignal "null";
BA_ "GenSigStartValue" SG_ 561 NDoorFLPrimarySignal 1;
BA_ "GenSigTimeoutTime_ALL" SG_ 561 NDoorFLPrimarySignal 200;
BA_ "InvalidValue" SG_ 561 NDoorFLPrimarySignal "null";
BA_ "GenSigStartValue" SG_ 561 NDoorFLClawSignal 1;
BA_ "GenSigTimeoutTime_ALL" SG_ 561 NDoorFLClawSignal 200;
BA_ "InvalidValue" SG_ 561 NDoorFLClawSignal "null";
BA_ "GenSigStartValue" SG_ 561 NDoorFLClawStatus 15;
BA_ "GenSigTimeoutTime_ALL" SG_ 561 NDoorFLClawStatus 200;
BA_ "InvalidValue" SG_ 561 NDoorFLClawStatus "null";
BA_ "GenSigTimeoutTime_ALL" SG_ 561 BDLFLResponseError 200;
BA_ "InvalidValue" SG_ 561 BDLFLResponseError "null";
BA_ "GenSigTimeoutTime_ALL" SG_ 561 NDoorFLCounter 200;
BA_ "InvalidValue" SG_ 561 NDoorFLCounter "null";
BA_ "GenSigTimeoutTime_ALL" SG_ 561 NDoorFLOutsideHandleFailure 200;
BA_ "InvalidValue" SG_ 561 NDoorFLOutsideHandleFailure "null";
BA_ "GenSigStartValue" SG_ 561 NDoorFLOutsideHandleStatus 1;
BA_ "GenSigTimeoutTime_ALL" SG_ 561 NDoorFLOutsideHandleStatus 200;
BA_ "InvalidValue" SG_ 561 NDoorFLOutsideHandleStatus "null";
BA_ "GenSigTimeoutTime_ALL" SG_ 561 NDoorLatchFLFailure 200;
BA_ "InvalidValue" SG_ 561 NDoorLatchFLFailure "null";
BA_ "GenSigTimeoutTime_ALL" SG_ 565 CHKSM_TRM_STATUS 500;
BA_ "InvalidValue" SG_ 565 CHKSM_TRM_STATUS "null";
BA_ "GenSigTimeoutTime_ALL" SG_ 565 ALIVE_TRM_STATUS 500;
BA_ "InvalidValue" SG_ 565 ALIVE_TRM_STATUS "Fh";
BA_ "GenSigTimeoutTime_ALL" SG_ 565 TowingDetected 500;
BA_ "InvalidValue" SG_ 565 TowingDetected "3h";
BA_ "GenSigTimeoutTime_ALL" SG_ 565 TrailerDetected 500;
BA_ "InvalidValue" SG_ 565 TrailerDetected "3h";
BA_ "GenSigStartValue" SG_ 569 NDoorRRHomeSignal 1;
BA_ "GenSigTimeoutTime_ALL" SG_ 569 NDoorRRHomeSignal 200;
BA_ "InvalidValue" SG_ 569 NDoorRRHomeSignal "null";
BA_ "GenSigStartValue" SG_ 569 NDoorRRSecondarySignal 1;
BA_ "GenSigTimeoutTime_ALL" SG_ 569 NDoorRRSecondarySignal 200;
BA_ "InvalidValue" SG_ 569 NDoorRRSecondarySignal "null";
BA_ "GenSigStartValue" SG_ 569 NDoorRRPrimarySignal 1;
BA_ "GenSigTimeoutTime_ALL" SG_ 569 NDoorRRPrimarySignal 200;
BA_ "InvalidValue" SG_ 569 NDoorRRPrimarySignal "null";
BA_ "GenSigStartValue" SG_ 569 NDoorRRClawSignal 1;
BA_ "GenSigTimeoutTime_ALL" SG_ 569 NDoorRRClawSignal 200;
BA_ "InvalidValue" SG_ 569 NDoorRRClawSignal "null";
BA_ "GenSigStartValue" SG_ 569 NDoorRRClawStatus 15;
BA_ "GenSigTimeoutTime_ALL" SG_ 569 NDoorRRClawStatus 200;
BA_ "InvalidValue" SG_ 569 NDoorRRClawStatus "null";
BA_ "GenSigTimeoutTime_ALL" SG_ 569 BDLRRResponseError 200;
BA_ "InvalidValue" SG_ 569 BDLRRResponseError "null";
BA_ "GenSigTimeoutTime_ALL" SG_ 569 NDoorRRCounter 200;
BA_ "InvalidValue" SG_ 569 NDoorRRCounter "null";
BA_ "GenSigStartValue" SG_ 569 NDoorRROutsideHandleFailure 1;
BA_ "GenSigTimeoutTime_ALL" SG_ 569 NDoorRROutsideHandleFailure 200;
BA_ "InvalidValue" SG_ 569 NDoorRROutsideHandleFailure "null";
BA_ "GenSigStartValue" SG_ 569 NDoorRROutsideHandleStatus 1;
BA_ "GenSigTimeoutTime_ALL" SG_ 569 NDoorRROutsideHandleStatus 200;
BA_ "InvalidValue" SG_ 569 NDoorRROutsideHandleStatus "null";
BA_ "GenSigTimeoutTime_ALL" SG_ 569 NDoorLatchRRFailure 200;
BA_ "InvalidValue" SG_ 569 NDoorLatchRRFailure "null";
BA_ "InvalidValue" SG_ 570 IDB_WheelDirection_FR "3h";
BA_ "GenSigTimeoutTime_ALL" SG_ 570 IDB_WheelDirection_FR 200;
BA_ "InvalidValue" SG_ 570 IDB_WheelDirection_FL "3h";
BA_ "GenSigTimeoutTime_ALL" SG_ 570 IDB_WheelDirection_FL 200;
BA_ "InvalidValue" SG_ 571 IDB_WheelDirection_RR "3h";
BA_ "GenSigTimeoutTime_ALL" SG_ 571 IDB_WheelDirection_RR 200;
BA_ "InvalidValue" SG_ 571 IDB_WheelDirection_RL "3h";
BA_ "GenSigTimeoutTime_ALL" SG_ 571 IDB_WheelDirection_RL 200;
BA_ "GenSigTimeoutTime_ALL" SG_ 578 NDoorFRVehicleLocked 200;
BA_ "InvalidValue" SG_ 578 NDoorFRVehicleLocked "1h";
BA_ "GenSigTimeoutTime_ALL" SG_ 578 NDoorFRVehicleMoving 200;
BA_ "InvalidValue" SG_ 578 NDoorFRVehicleMoving "1h";
BA_ "GenSigTimeoutTime_ALL" SG_ 578 NDoorFROpenInvRequested 200;
BA_ "InvalidValue" SG_ 578 NDoorFROpenInvRequested "1h";
BA_ "GenSigStartValue" SG_ 578 NDoorFROpenRequested 3;
BA_ "GenSigTimeoutTime_ALL" SG_ 578 NDoorFROpenRequested 200;
BA_ "InvalidValue" SG_ 578 NDoorFROpenRequested "2h";
BA_ "GenSigStartValue" SG_ 578 NDoorFRChildLocked 3;
BA_ "GenSigTimeoutTime_ALL" SG_ 578 NDoorFRChildLocked 200;
BA_ "InvalidValue" SG_ 578 NDoorFRChildLocked "1h";
BA_ "GenSigStartValue" SG_ 578 NDoorFRVehicleCrash 3;
BA_ "GenSigTimeoutTime_ALL" SG_ 578 NDoorFRVehicleCrash 200;
BA_ "InvalidValue" SG_ 578 NDoorFRVehicleCrash "1h";
BA_ "GenSigTimeoutTime_ALL" SG_ 578 NDoorFRCommandCounter 200;
BA_ "InvalidValue" SG_ 578 NDoorFRCommandCounter "null";
BA_ "GenSigTimeoutTime_ALL" SG_ 578 NDoorFRCloseInvRequested 200;
BA_ "InvalidValue" SG_ 578 NDoorFRCloseInvRequested "null";
BA_ "GenSigTimeoutTime_ALL" SG_ 578 NDoorFRCloseRequested 200;
BA_ "InvalidValue" SG_ 578 NDoorFRCloseRequested "null";
BA_ "GenSigStartValue" SG_ 584 NDoorFRHomeSignal 1;
BA_ "GenSigTimeoutTime_ALL" SG_ 584 NDoorFRHomeSignal 200;
BA_ "InvalidValue" SG_ 584 NDoorFRHomeSignal "null";
BA_ "GenSigStartValue" SG_ 584 NDoorFRSecondarySignal 1;
BA_ "GenSigTimeoutTime_ALL" SG_ 584 NDoorFRSecondarySignal 200;
BA_ "InvalidValue" SG_ 584 NDoorFRSecondarySignal "null";
BA_ "GenSigStartValue" SG_ 584 NDoorFRPrimarySignal 1;
BA_ "GenSigTimeoutTime_ALL" SG_ 584 NDoorFRPrimarySignal 200;
BA_ "InvalidValue" SG_ 584 NDoorFRPrimarySignal "null";
BA_ "GenSigStartValue" SG_ 584 NDoorFRClawSignal 1;
BA_ "GenSigTimeoutTime_ALL" SG_ 584 NDoorFRClawSignal 200;
BA_ "InvalidValue" SG_ 584 NDoorFRClawSignal "null";
BA_ "GenSigStartValue" SG_ 584 NDoorFRClawStatus 15;
BA_ "GenSigTimeoutTime_ALL" SG_ 584 NDoorFRClawStatus 200;
BA_ "InvalidValue" SG_ 584 NDoorFRClawStatus "null";
BA_ "GenSigTimeoutTime_ALL" SG_ 584 BDLFRResponseError 200;
BA_ "InvalidValue" SG_ 584 BDLFRResponseError "null";
BA_ "GenSigTimeoutTime_ALL" SG_ 584 NDoorFRCounter 200;
BA_ "InvalidValue" SG_ 584 NDoorFRCounter "null";
BA_ "GenSigTimeoutTime_ALL" SG_ 584 NDoorFROutsideHandleFailure 200;
BA_ "InvalidValue" SG_ 584 NDoorFROutsideHandleFailure "null";
BA_ "GenSigStartValue" SG_ 584 NDoorFROutsideHandleStatus 1;
BA_ "GenSigTimeoutTime_ALL" SG_ 584 NDoorFROutsideHandleStatus 200;
BA_ "InvalidValue" SG_ 584 NDoorFROutsideHandleStatus "null";
BA_ "GenSigTimeoutTime_ALL" SG_ 584 NDoorLatchFRFailure 200;
BA_ "InvalidValue" SG_ 584 NDoorLatchFRFailure "null";
BA_ "GenSigTimeoutTime_ALL" SG_ 592 CHSKM_BMS_VCU_THMReq 500;
BA_ "InvalidValue" SG_ 592 CHSKM_BMS_VCU_THMReq "null";
BA_ "GenSigTimeoutTime_ALL" SG_ 592 ALV_BMS_VCU_THMReq 500;
BA_ "InvalidValue" SG_ 592 ALV_BMS_VCU_THMReq "Fh";
BA_ "GenSigTimeoutTime_ALL" SG_ 592 BMS_FlowRate_Req 500;
BA_ "InvalidValue" SG_ 592 BMS_FlowRate_Req "FFh";
BA_ "GenSigTimeoutTime_ALL" SG_ 592 BMS_CoolPwrDemand 500;
BA_ "InvalidValue" SG_ 592 BMS_CoolPwrDemand "FFFh";
BA_ "GenSigTimeoutTime_ALL" SG_ 592 BMS_HeatPwrDemand 500;
BA_ "InvalidValue" SG_ 592 BMS_HeatPwrDemand "FFFh";
BA_ "GenSigTimeoutTime_ALL" SG_ 592 BMS_VCU_PTCOnOff_Req 500;
BA_ "InvalidValue" SG_ 592 BMS_VCU_PTCOnOff_Req "null";
BA_ "GenSigTimeoutTime_ALL" SG_ 592 BMS_VCU_ValveOnOff_Req 500;
BA_ "InvalidValue" SG_ 592 BMS_VCU_ValveOnOff_Req "null";
BA_ "GenSigTimeoutTime_ALL" SG_ 592 BMS_PreHeatCoolReq 500;
BA_ "InvalidValue" SG_ 592 BMS_PreHeatCoolReq "3h";
BA_ "GenSigTimeoutTime_ALL" SG_ 593 NDoorRLVehicleLocked 200;
BA_ "InvalidValue" SG_ 593 NDoorRLVehicleLocked "1h";
BA_ "GenSigTimeoutTime_ALL" SG_ 593 NDoorRLVehicleMoving 200;
BA_ "InvalidValue" SG_ 593 NDoorRLVehicleMoving "1h";
BA_ "GenSigTimeoutTime_ALL" SG_ 593 NDoorRLOpenInvRequested 200;
BA_ "InvalidValue" SG_ 593 NDoorRLOpenInvRequested "1h";
BA_ "GenSigStartValue" SG_ 593 NDoorRLOpenRequested 3;
BA_ "GenSigTimeoutTime_ALL" SG_ 593 NDoorRLOpenRequested 200;
BA_ "InvalidValue" SG_ 593 NDoorRLOpenRequested "2h";
BA_ "GenSigStartValue" SG_ 593 NDoorRLChildLocked 3;
BA_ "GenSigTimeoutTime_ALL" SG_ 593 NDoorRLChildLocked 200;
BA_ "InvalidValue" SG_ 593 NDoorRLChildLocked "1h";
BA_ "GenSigStartValue" SG_ 593 NDoorRLVehicleCrash 3;
BA_ "GenSigTimeoutTime_ALL" SG_ 593 NDoorRLVehicleCrash 200;
BA_ "InvalidValue" SG_ 593 NDoorRLVehicleCrash "1h";
BA_ "GenSigTimeoutTime_ALL" SG_ 593 NDoorRLCommandCounter 200;
BA_ "InvalidValue" SG_ 593 NDoorRLCommandCounter "null";
BA_ "GenSigTimeoutTime_ALL" SG_ 593 NDoorRLCloseInvRequested 200;
BA_ "InvalidValue" SG_ 593 NDoorRLCloseInvRequested "null";
BA_ "GenSigTimeoutTime_ALL" SG_ 593 NDoorRLCloseRequested 200;
BA_ "InvalidValue" SG_ 593 NDoorRLCloseRequested "null";
BA_ "GenSigTimeoutTime_ALL" SG_ 596 CRC_AVL_RPM_WHL_REAR 200;
BA_ "InvalidValue" SG_ 596 CRC_AVL_RPM_WHL_REAR "null";
BA_ "GenSigTimeoutTime_ALL" SG_ 596 ALIV_AVL_RPM_WHL_REAR 200;
BA_ "InvalidValue" SG_ 596 ALIV_AVL_RPM_WHL_REAR "Fh";
BA_ "GenSigStartValue" SG_ 596 AVL_RPM_WHL_RLH 32819;
BA_ "GenSigTimeoutTime_ALL" SG_ 596 AVL_RPM_WHL_RLH 200;
BA_ "InvalidValue" SG_ 596 AVL_RPM_WHL_RLH "null";
BA_ "GenSigStartValue" SG_ 596 AVL_RPM_WHL_RRH 32819;
BA_ "GenSigTimeoutTime_ALL" SG_ 596 AVL_RPM_WHL_RRH 200;
BA_ "InvalidValue" SG_ 596 AVL_RPM_WHL_RRH "null";
BA_ "GenSigTimeoutTime_ALL" SG_ 596 QU_AVL_RPM_WHL_RLH 200;
BA_ "InvalidValue" SG_ 596 QU_AVL_RPM_WHL_RLH "Fh";
BA_ "GenSigTimeoutTime_ALL" SG_ 596 QU_AVL_RPM_WHL_RRH 200;
BA_ "InvalidValue" SG_ 596 QU_AVL_RPM_WHL_RRH "Fh";
BA_ "GenSigTimeoutTime_ALL" SG_ 597 CRC_AVL_RPM_WHL_FRONT 200;
BA_ "InvalidValue" SG_ 597 CRC_AVL_RPM_WHL_FRONT "null";
BA_ "GenSigTimeoutTime_ALL" SG_ 597 ALIV_AVL_RPM_WHL_FRONT 200;
BA_ "InvalidValue" SG_ 597 ALIV_AVL_RPM_WHL_FRONT "Fh";
BA_ "GenSigStartValue" SG_ 597 AVL_RPM_WHL_FLH 32819;
BA_ "GenSigTimeoutTime_ALL" SG_ 597 AVL_RPM_WHL_FLH 200;
BA_ "InvalidValue" SG_ 597 AVL_RPM_WHL_FLH "null";
BA_ "GenSigStartValue" SG_ 597 AVL_RPM_WHL_FRH 32819;
BA_ "GenSigTimeoutTime_ALL" SG_ 597 AVL_RPM_WHL_FRH 200;
BA_ "InvalidValue" SG_ 597 AVL_RPM_WHL_FRH "null";
BA_ "GenSigTimeoutTime_ALL" SG_ 597 QU_AVL_RPM_WHL_FLH 200;
BA_ "InvalidValue" SG_ 597 QU_AVL_RPM_WHL_FLH "Fh";
BA_ "GenSigTimeoutTime_ALL" SG_ 597 QU_AVL_RPM_WHL_FRH 200;
BA_ "InvalidValue" SG_ 597 QU_AVL_RPM_WHL_FRH "Fh";
BA_ "GenSigTimeoutTime_ALL" SG_ 598 BCM_Animation_Req 200;
BA_ "InvalidValue" SG_ 598 BCM_Animation_Req "7h";
BA_ "GenSigTimeoutTime_ALL" SG_ 598 BCM_Charging_Sts 200;
BA_ "InvalidValue" SG_ 598 BCM_Charging_Sts "7h";
BA_ "GenSigTimeoutTime_ALL" SG_ 598 BCM_Lock_Sts 200;
BA_ "InvalidValue" SG_ 598 BCM_Lock_Sts "3h";
BA_ "GenSigTimeoutTime_ALL" SG_ 598 BCM_Panic_Status 200;
BA_ "InvalidValue" SG_ 598 BCM_Panic_Status "null";
BA_ "GenSigTimeoutTime_ALL" SG_ 598 BCM_Charging_SOC 200;
BA_ "InvalidValue" SG_ 598 BCM_Charging_SOC "Fh";
BA_ "GenSigTimeoutTime_ALL" SG_ 598 BCM_LeftPosLmpSts 200;
BA_ "InvalidValue" SG_ 598 BCM_LeftPosLmpSts "3h";
BA_ "GenSigTimeoutTime_ALL" SG_ 598 BCM_RightPosLmpSts 200;
BA_ "InvalidValue" SG_ 598 BCM_RightPosLmpSts "3h";
BA_ "GenSigTimeoutTime_ALL" SG_ 618 ALIV_ST_LCS_VEH 1000;
BA_ "InvalidValue" SG_ 618 ALIV_ST_LCS_VEH "Fh";
BA_ "GenSigTimeoutTime_ALL" SG_ 618 ST_ECU_ST_LCS_VEH 1000;
BA_ "InvalidValue" SG_ 618 ST_ECU_ST_LCS_VEH "null";
BA_ "GenSigTimeoutTime_ALL" SG_ 618 QU_FN_LCS_VEH 1000;
BA_ "InvalidValue" SG_ 618 QU_FN_LCS_VEH "null";
BA_ "GenSigStartValue" SG_ 619 Sig_TgtVer_LR 1023;
BA_ "GenSigTimeoutTime_ALL" SG_ 619 Sig_TgtVer_LR 1000;
BA_ "InvalidValue" SG_ 619 Sig_TgtVer_LR "null";
BA_ "GenSigTimeoutTime_ALL" SG_ 620 Sig_SPVer_L 1000;
BA_ "InvalidValue" SG_ 620 Sig_SPVer_L "null";
BA_ "GenSigTimeoutTime_ALL" SG_ 620 Sig_SPVer_R 1000;
BA_ "InvalidValue" SG_ 620 Sig_SPVer_R "null";
BA_ "GenSigTimeoutTime_ALL" SG_ 620 Sig_RefVer_LR 1000;
BA_ "InvalidValue" SG_ 620 Sig_RefVer_LR "null";
BA_ "GenSigStartValue" SG_ 641 NDoorRLHomeSignal 1;
BA_ "GenSigTimeoutTime_ALL" SG_ 641 NDoorRLHomeSignal 200;
BA_ "InvalidValue" SG_ 641 NDoorRLHomeSignal "null";
BA_ "GenSigStartValue" SG_ 641 NDoorRLSecondarySignal 1;
BA_ "GenSigTimeoutTime_ALL" SG_ 641 NDoorRLSecondarySignal 200;
BA_ "InvalidValue" SG_ 641 NDoorRLSecondarySignal "null";
BA_ "GenSigStartValue" SG_ 641 NDoorRLPrimarySignal 1;
BA_ "GenSigTimeoutTime_ALL" SG_ 641 NDoorRLPrimarySignal 200;
BA_ "InvalidValue" SG_ 641 NDoorRLPrimarySignal "null";
BA_ "GenSigStartValue" SG_ 641 NDoorRLClawSignal 1;
BA_ "GenSigTimeoutTime_ALL" SG_ 641 NDoorRLClawSignal 200;
BA_ "InvalidValue" SG_ 641 NDoorRLClawSignal "null";
BA_ "GenSigStartValue" SG_ 641 NDoorRLClawStatus 15;
BA_ "GenSigTimeoutTime_ALL" SG_ 641 NDoorRLClawStatus 200;
BA_ "InvalidValue" SG_ 641 NDoorRLClawStatus "Fh";
BA_ "GenSigTimeoutTime_ALL" SG_ 641 BDLRLResponseError 200;
BA_ "InvalidValue" SG_ 641 BDLRLResponseError "null";
BA_ "GenSigTimeoutTime_ALL" SG_ 641 NDoorRLCounter 200;
BA_ "InvalidValue" SG_ 641 NDoorRLCounter "null";
BA_ "GenSigTimeoutTime_ALL" SG_ 641 NDoorRLOutsideHandleFailure 200;
BA_ "InvalidValue" SG_ 641 NDoorRLOutsideHandleFailure "null";
BA_ "GenSigStartValue" SG_ 641 NDoorRLOutsideHandleStatus 1;
BA_ "GenSigTimeoutTime_ALL" SG_ 641 NDoorRLOutsideHandleStatus 200;
BA_ "InvalidValue" SG_ 641 NDoorRLOutsideHandleStatus "null";
BA_ "GenSigTimeoutTime_ALL" SG_ 641 NDoorLatchRLFailure 200;
BA_ "InvalidValue" SG_ 641 NDoorLatchRLFailure "null";
BA_ "GenSigTimeoutTime_ALL" SG_ 649 CHKSM_IDB_ZF2 200;
BA_ "GenSigTimeoutTime_ALL" SG_ 649 ALIVE_IDB_ZF2 200;
BA_ "InvalidValue" SG_ 649 ALIVE_IDB_ZF2 "Fh";
BA_ "GenSigTimeoutTime_ALL" SG_ 649 AxOutStatus 200;
BA_ "InvalidValue" SG_ 649 AxOutStatus "1h";
BA_ "GenSigStartValue" SG_ 649 QU_VYAW_VEH 8;
BA_ "GenSigTimeoutTime_ALL" SG_ 649 QU_VYAW_VEH 200;
BA_ "InvalidValue" SG_ 649 QU_VYAW_VEH "Fh";
BA_ "GenSigTimeoutTime_ALL" SG_ 649 AyOutStatus 200;
BA_ "InvalidValue" SG_ 649 AyOutStatus "1h";
BA_ "GenSigStartValue" SG_ 649 AcceleratorY 795;
BA_ "GenSigTimeoutTime_ALL" SG_ 649 AcceleratorY 200;
BA_ "InvalidValue" SG_ 649 AcceleratorY "FFFh";
BA_ "GenSigTimeoutTime_ALL" SG_ 649 AcceleratorX 200;
BA_ "InvalidValue" SG_ 649 AcceleratorX "FFFh";
BA_ "GenSigStartValue" SG_ 649 VYAW_VEH 32768;
BA_ "GenSigTimeoutTime_ALL" SG_ 649 VYAW_VEH 200;
BA_ "InvalidValue" SG_ 649 VYAW_VEH "FFFFh";
BA_ "GenSigTimeoutTime_ALL" SG_ 654 CHKSM_APM_WINDOW_POS 500;
BA_ "InvalidValue" SG_ 654 CHKSM_APM_WINDOW_POS "null";
BA_ "GenSigTimeoutTime_ALL" SG_ 654 ALV_APM_WINDOW_POS 500;
BA_ "InvalidValue" SG_ 654 ALV_APM_WINDOW_POS "Fh";
BA_ "GenSigTimeoutTime_ALL" SG_ 654 Window_PosFL 500;
BA_ "InvalidValue" SG_ 654 Window_PosFL "7h";
BA_ "GenSigTimeoutTime_ALL" SG_ 654 Window_Warning 500;
BA_ "InvalidValue" SG_ 654 Window_Warning "3h";
BA_ "GenSigTimeoutTime_ALL" SG_ 654 Wndow_PosRL 500;
BA_ "InvalidValue" SG_ 654 Wndow_PosRL "7h";
BA_ "GenSigTimeoutTime_ALL" SG_ 654 Window_PosFR 500;
BA_ "InvalidValue" SG_ 654 Window_PosFR "7h";
BA_ "GenSigTimeoutTime_ALL" SG_ 654 Global_close 500;
BA_ "InvalidValue" SG_ 654 Global_close "3h";
BA_ "GenSigTimeoutTime_ALL" SG_ 654 Global_open 500;
BA_ "InvalidValue" SG_ 654 Global_open "3h";
BA_ "GenSigTimeoutTime_ALL" SG_ 654 Window_PosRR 500;
BA_ "InvalidValue" SG_ 654 Window_PosRR "7h";
BA_ "GenSigTimeoutTime_ALL" SG_ 657 NDoorRRVehicleLocked 200;
BA_ "InvalidValue" SG_ 657 NDoorRRVehicleLocked "1h";
BA_ "GenSigTimeoutTime_ALL" SG_ 657 NDoorRRVehicleMoving 200;
BA_ "InvalidValue" SG_ 657 NDoorRRVehicleMoving "1h";
BA_ "GenSigTimeoutTime_ALL" SG_ 657 NDoorRROpenInvRequested 200;
BA_ "InvalidValue" SG_ 657 NDoorRROpenInvRequested "1h";
BA_ "GenSigStartValue" SG_ 657 NDoorRROpenRequested 3;
BA_ "GenSigTimeoutTime_ALL" SG_ 657 NDoorRROpenRequested 200;
BA_ "InvalidValue" SG_ 657 NDoorRROpenRequested "2h";
BA_ "GenSigStartValue" SG_ 657 NDoorRRChildLocked 3;
BA_ "GenSigTimeoutTime_ALL" SG_ 657 NDoorRRChildLocked 200;
BA_ "InvalidValue" SG_ 657 NDoorRRChildLocked "1h";
BA_ "GenSigStartValue" SG_ 657 NDoorRRVehicleCrash 3;
BA_ "GenSigTimeoutTime_ALL" SG_ 657 NDoorRRVehicleCrash 200;
BA_ "InvalidValue" SG_ 657 NDoorRRVehicleCrash "1h";
BA_ "GenSigTimeoutTime_ALL" SG_ 657 NDoorRRCommandCounter 200;
BA_ "InvalidValue" SG_ 657 NDoorRRCommandCounter "null";
BA_ "GenSigTimeoutTime_ALL" SG_ 657 NDoorRRCloseInvRequested 200;
BA_ "InvalidValue" SG_ 657 NDoorRRCloseInvRequested "null";
BA_ "GenSigTimeoutTime_ALL" SG_ 657 NDoorRRCloseRequested 200;
BA_ "InvalidValue" SG_ 657 NDoorRRCloseRequested "null";
BA_ "GenSigStartValue" SG_ 673 DrvSeatMsgStrLvl 1;
BA_ "GenSigTimeoutTime_ALL" SG_ 673 DrvSeatMsgStrLvl 800;
BA_ "InvalidValue" SG_ 673 DrvSeatMsgStrLvl "7h";
BA_ "GenSigStartValue" SG_ 673 PassSeatMsgStrLvl 1;
BA_ "GenSigTimeoutTime_ALL" SG_ 673 PassSeatMsgStrLvl 800;
BA_ "InvalidValue" SG_ 673 PassSeatMsgStrLvl "7h";
BA_ "GenSigStartValue" SG_ 673 RearDrvSeatMsgStrLvl 1;
BA_ "GenSigTimeoutTime_ALL" SG_ 673 RearDrvSeatMsgStrLvl 800;
BA_ "InvalidValue" SG_ 673 RearDrvSeatMsgStrLvl "7h";
BA_ "GenSigStartValue" SG_ 673 RearPassSeatMsgStrLvl 1;
BA_ "GenSigTimeoutTime_ALL" SG_ 673 RearPassSeatMsgStrLvl 800;
BA_ "InvalidValue" SG_ 673 RearPassSeatMsgStrLvl "7h";
BA_ "GenSigTimeoutTime_ALL" SG_ 673 DrvSeatMsgMode 800;
BA_ "InvalidValue" SG_ 673 DrvSeatMsgMode "7h";
BA_ "GenSigTimeoutTime_ALL" SG_ 673 PassSeatMsgMode 800;
BA_ "InvalidValue" SG_ 673 PassSeatMsgMode "7h";
BA_ "GenSigTimeoutTime_ALL" SG_ 673 RearDrvSeatMsgMode 800;
BA_ "InvalidValue" SG_ 673 RearDrvSeatMsgMode "7h";
BA_ "GenSigTimeoutTime_ALL" SG_ 673 RearPassSeatMsgMode 800;
BA_ "InvalidValue" SG_ 673 RearPassSeatMsgMode "7h";
BA_ "GenSigTimeoutTime_ALL" SG_ 674 DrvSeatMsgModeStat 800;
BA_ "InvalidValue" SG_ 674 DrvSeatMsgModeStat "7h";
BA_ "GenSigTimeoutTime_ALL" SG_ 674 PassSeatMsgModeStat 800;
BA_ "InvalidValue" SG_ 674 PassSeatMsgModeStat "7h";
BA_ "GenSigTimeoutTime_ALL" SG_ 674 RearDrvSeatMsgModeStat 800;
BA_ "InvalidValue" SG_ 674 RearDrvSeatMsgModeStat "7h";
BA_ "GenSigTimeoutTime_ALL" SG_ 674 RearPassSeatMsgModeStat 800;
BA_ "InvalidValue" SG_ 674 RearPassSeatMsgModeStat "7h";
BA_ "GenSigTimeoutTime_ALL" SG_ 674 LSSM_ALINResErr 800;
BA_ "InvalidValue" SG_ 674 LSSM_ALINResErr "null";
BA_ "GenSigTimeoutTime_ALL" SG_ 674 LSSM_APumpFail 800;
BA_ "InvalidValue" SG_ 674 LSSM_APumpFail "null";
BA_ "GenSigStartValue" SG_ 674 DrvSeatMsgStrLvlStat 1;
BA_ "GenSigTimeoutTime_ALL" SG_ 674 DrvSeatMsgStrLvlStat 800;
BA_ "InvalidValue" SG_ 674 DrvSeatMsgStrLvlStat "7h";
BA_ "GenSigTimeoutTime_ALL" SG_ 674 LSSM_BLINResErr 800;
BA_ "InvalidValue" SG_ 674 LSSM_BLINResErr "null";
BA_ "GenSigTimeoutTime_ALL" SG_ 674 LSSM_BPumpFail 800;
BA_ "InvalidValue" SG_ 674 LSSM_BPumpFail "null";
BA_ "GenSigStartValue" SG_ 674 PassSeatMsgStrLvlStat 1;
BA_ "GenSigTimeoutTime_ALL" SG_ 674 PassSeatMsgStrLvlStat 800;
BA_ "InvalidValue" SG_ 674 PassSeatMsgStrLvlStat "7h";
BA_ "GenSigTimeoutTime_ALL" SG_ 674 LSSM_CLINResErr 800;
BA_ "InvalidValue" SG_ 674 LSSM_CLINResErr "null";
BA_ "GenSigTimeoutTime_ALL" SG_ 674 LSSM_CPumpFail 800;
BA_ "InvalidValue" SG_ 674 LSSM_CPumpFail "null";
BA_ "GenSigStartValue" SG_ 674 RearDrvSeatMsgStrLvlStat 1;
BA_ "GenSigTimeoutTime_ALL" SG_ 674 RearDrvSeatMsgStrLvlStat 800;
BA_ "InvalidValue" SG_ 674 RearDrvSeatMsgStrLvlStat "7h";
BA_ "GenSigTimeoutTime_ALL" SG_ 674 LSSM_DLINResErr 800;
BA_ "InvalidValue" SG_ 674 LSSM_DLINResErr "null";
BA_ "GenSigTimeoutTime_ALL" SG_ 674 LSSM_DPumpFail 800;
BA_ "InvalidValue" SG_ 674 LSSM_DPumpFail "null";
BA_ "GenSigStartValue" SG_ 674 RearPassSeatMsgStrLvlStat 1;
BA_ "GenSigTimeoutTime_ALL" SG_ 674 RearPassSeatMsgStrLvlStat 800;
BA_ "InvalidValue" SG_ 674 RearPassSeatMsgStrLvlStat "7h";
BA_ "GenSigTimeoutTime_ALL" SG_ 676 ID2 5000;
BA_ "GenSigTimeoutTime_ALL" SG_ 676 ECU_ID_WUPREG 5000;
BA_ "InvalidValue" SG_ 676 ECU_ID_WUPREG "null";
BA_ "GenSigTimeoutTime_ALL" SG_ 676 ID_FN_INQY 5000;
BA_ "InvalidValue" SG_ 676 ID_FN_INQY "null";
BA_ "GenSigTimeoutTime_ALL" SG_ 676 ID_FN_RQ_BUS 5000;
BA_ "InvalidValue" SG_ 676 ID_FN_RQ_BUS "null";
BA_ "GenSigTimeoutTime_ALL" SG_ 676 NO_CC_MESS_EXT 5000;
BA_ "GenSigTimeoutTime_ALL" SG_ 676 NO_CC_MESS_STD 5000;
BA_ "InvalidValue" SG_ 676 NO_CC_MESS_STD "null";
BA_ "GenSigTimeoutTime_ALL" SG_ 676 WACA 5000;
BA_ "InvalidValue" SG_ 676 WACA "null";
BA_ "GenSigTimeoutTime_ALL" SG_ 676 ID_RQ_BUS 5000;
BA_ "GenSigTimeoutTime_ALL" SG_ 676 ST_CC_MESS_EXT 5000;
BA_ "GenSigTimeoutTime_ALL" SG_ 676 ST_CC_MESS_STD 5000;
BA_ "GenSigTimeoutTime_ALL" SG_ 676 TRANF_CC_MESS_EXT 5000;
BA_ "GenSigTimeoutTime_ALL" SG_ 676 TRANF_CC_MESS_STD 5000;
BA_ "GenSigTimeoutTime_ALL" SG_ 676 ST_IDC_CCLK_CC_MESS_EXT 5000;
BA_ "GenSigTimeoutTime_ALL" SG_ 676 ST_IDC_CCLK_CC_MESS_STD 5000;
BA_ "GenSigTimeoutTime_ALL" SG_ 676 NO_FRM_CC_MESS_EXT 5000;
BA_ "GenSigTimeoutTime_ALL" SG_ 676 ST_RQ_BUS 5000;
BA_ "GenSigTimeoutTime_ALL" SG_ 676 QUAN_FRM_CC_MESS_EXT 5000;
BA_ "GenSigTimeoutTime_ALL" SG_ 676 ST_LAW_RQ 5000;
BA_ "GenSigTimeoutTime_ALL" SG_ 676 DUR_FLLUPT 5000;
BA_ "GenSigTimeoutTime_ALL" SG_ 676 UTDT_CC_MESS 5000;
BA_ "GenSigTimeoutTime_ALL" SG_ 714 CHKSM_IC_SENSOR 500;
BA_ "InvalidValue" SG_ 714 CHKSM_IC_SENSOR "null";
BA_ "GenSigTimeoutTime_ALL" SG_ 714 ALV_IC_SENSOR 500;
BA_ "InvalidValue" SG_ 714 ALV_IC_SENSOR "Fh";
BA_ "GenSigStartValue" SG_ 714 MHU_STAT_AmbientTempRaw 80;
BA_ "GenSigTimeoutTime_ALL" SG_ 714 MHU_STAT_AmbientTempRaw 500;
BA_ "InvalidValue" SG_ 714 MHU_STAT_AmbientTempRaw "FFh";
BA_ "GenSigTimeoutTime_ALL" SG_ 714 MHU_STAT_FuelLevel 500;
BA_ "InvalidValue" SG_ 714 MHU_STAT_FuelLevel "FFh";
BA_ "GenSigStartValue" SG_ 714 MHU_STAT_AmbientTemp 80;
BA_ "GenSigTimeoutTime_ALL" SG_ 714 MHU_STAT_AmbientTemp 500;
BA_ "InvalidValue" SG_ 714 MHU_STAT_AmbientTemp "FFh";
BA_ "GenSigTimeoutTime_ALL" SG_ 714 MHU_STAT_CoolantLevelStatus 500;
BA_ "InvalidValue" SG_ 714 MHU_STAT_CoolantLevelStatus "3h";
BA_ "GenSigTimeoutTime_ALL" SG_ 720 CHKSM_FCAM_AESA_Sts 500;
BA_ "InvalidValue" SG_ 720 ALV_FCAM_AESA_Sts "Fh";
BA_ "GenSigTimeoutTime_ALL" SG_ 720 ALV_FCAM_AESA_Sts 500;
BA_ "GenSigTimeoutTime_ALL" SG_ 720 FCAM_AESA_DoorUnlock_Req 500;
BA_ "GenSigTimeoutTime_ALL" SG_ 720 FCAM_AESA_ECALL_Req 500;
BA_ "GenSigTimeoutTime_ALL" SG_ 720 FCAM_AESA_Status 500;
BA_ "GenSigTimeoutTime_ALL" SG_ 715 TEMP_EX 500;
BA_ "InvalidValue" SG_ 715 TEMP_EX "FFh";
BA_ "GenSigTimeoutTime_ALL" SG_ 715 TEMP_EX_UNFILT 500;
BA_ "InvalidValue" SG_ 715 TEMP_EX_UNFILT "FFh";
BA_ "GenSigTimeoutTime_ALL" SG_ 753 MHU_STAT_AirbagWarnLamp 500;
BA_ "InvalidValue" SG_ 753 MHU_STAT_AirbagWarnLamp "3h";
BA_ "GenSigTimeoutTime_ALL" SG_ 760 DISP_HR 5000;
BA_ "InvalidValue" SG_ 760 DISP_HR "FFh";
BA_ "GenSigTimeoutTime_ALL" SG_ 760 DISP_MN 5000;
BA_ "InvalidValue" SG_ 760 DISP_MN "FFh";
BA_ "GenSigTimeoutTime_ALL" SG_ 760 DISP_SEC 5000;
BA_ "InvalidValue" SG_ 760 DISP_SEC "FFh";
BA_ "GenSigStartValue" SG_ 760 DISP_DATE_DAY 1;
BA_ "GenSigTimeoutTime_ALL" SG_ 760 DISP_DATE_DAY 5000;
BA_ "InvalidValue" SG_ 760 DISP_DATE_DAY "FFh";
BA_ "GenSigStartValue" SG_ 760 DISP_DATE_MON 1;
BA_ "GenSigTimeoutTime_ALL" SG_ 760 DISP_DATE_MON 5000;
BA_ "InvalidValue" SG_ 760 DISP_DATE_MON "Fh";
BA_ "GenSigTimeoutTime_ALL" SG_ 760 DISP_DATE_WDAY 5000;
BA_ "InvalidValue" SG_ 760 DISP_DATE_WDAY "Fh";
BA_ "GenSigStartValue" SG_ 760 DISP_DATE_YR 1;
BA_ "GenSigTimeoutTime_ALL" SG_ 760 DISP_DATE_YR 5000;
BA_ "InvalidValue" SG_ 760 DISP_DATE_YR "FFFFh";
BA_ "GenSigTimeoutTime_ALL" SG_ 760 ST_DISP_CTI_DATE 5000;
BA_ "InvalidValue" SG_ 760 ST_DISP_CTI_DATE "Fh";
BA_ "GenSigSendType" SG_ 768 CCU_STAT_SyncClimateZone 4;
BA_ "InvalidValue" SG_ 768 CCU_STAT_SyncClimateZone "3h";
BA_ "GenSigSendType" SG_ 768 CCU_STAT_Auto 4;
BA_ "InvalidValue" SG_ 768 CCU_STAT_Auto "3h";
BA_ "GenSigSendType" SG_ 768 CCU_STAT_Aircondition 4;
BA_ "InvalidValue" SG_ 768 CCU_STAT_Aircondition "3h";
BA_ "GenSigSendType" SG_ 768 CCU_STAT_IonButton 4;
BA_ "InvalidValue" SG_ 768 CCU_STAT_IonButton "3h";
BA_ "GenSigSendType" SG_ 768 CCU_STAT_MaxAc 4;
BA_ "InvalidValue" SG_ 768 CCU_STAT_MaxAc "3h";
BA_ "GenSigSendType" SG_ 768 CCU_STAT_OnOff 4;
BA_ "GenSigStartValue" SG_ 768 CCU_STAT_OnOff 3;
BA_ "InvalidValue" SG_ 768 CCU_STAT_OnOff "3h";
BA_ "GenSigSendType" SG_ 768 CCU_STAT_FanSpeed 4;
BA_ "InvalidValue" SG_ 768 CCU_STAT_FanSpeed "Fh";
BA_ "GenSigSendType" SG_ 768 CCU_STAT_RecircFlap 4;
BA_ "GenSigStartValue" SG_ 768 CCU_STAT_RecircFlap 1;
BA_ "InvalidValue" SG_ 768 CCU_STAT_RecircFlap "3h";
BA_ "GenSigSendType" SG_ 768 CCU_STAT_FlapPos 4;
BA_ "InvalidValue" SG_ 768 CCU_STAT_FlapPos "7h";
BA_ "GenSigSendType" SG_ 768 CCU_STAT_Defrost 4;
BA_ "InvalidValue" SG_ 768 CCU_STAT_Defrost "3h";
BA_ "GenSigSendType" SG_ 768 CCU_STAT_PTC_Heater 4;
BA_ "InvalidValue" SG_ 768 CCU_STAT_PTC_Heater "7h";
BA_ "GenSigSendType" SG_ 768 CCU_STAT_TempDriver 4;
BA_ "GenSigStartValue" SG_ 768 CCU_STAT_TempDriver 40;
BA_ "InvalidValue" SG_ 768 CCU_STAT_TempDriver "FFh";
BA_ "GenSigSendType" SG_ 768 CCU_STAT_TempPassenger 4;
BA_ "GenSigStartValue" SG_ 768 CCU_STAT_TempPassenger 40;
BA_ "InvalidValue" SG_ 768 CCU_STAT_TempPassenger "FFh";
BA_ "GenSigTimeoutTime_ALL" SG_ 769 RP_Status 500;
BA_ "GenSigTimeoutTime_ALL" SG_ 770 CHKSM_CCU_TEMP_PRESSURE 5000;
BA_ "InvalidValue" SG_ 770 CHKSM_CCU_TEMP_PRESSURE "null";
BA_ "GenSigTimeoutTime_ALL" SG_ 770 ALV_CCU_TEMP_PRESSURE 5000;
BA_ "InvalidValue" SG_ 770 ALV_CCU_TEMP_PRESSURE "Fh";
BA_ "GenSigTimeoutTime_ALL" SG_ 770 CCU_Pressure_AC 5000;
BA_ "InvalidValue" SG_ 770 CCU_Pressure_AC "3Fh";
BA_ "GenSigStartValue" SG_ 770 CCU_InteriorTemp 80;
BA_ "GenSigTimeoutTime_ALL" SG_ 770 CCU_InteriorTemp 5000;
BA_ "InvalidValue" SG_ 770 CCU_InteriorTemp "FFh";
BA_ "GenSigStartValue" SG_ 770 CCU_TempEx_AC 80;
BA_ "GenSigTimeoutTime_ALL" SG_ 770 CCU_TempEx_AC 5000;
BA_ "InvalidValue" SG_ 770 CCU_TempEx_AC "FFh";
BA_ "GenSigStartValue" SG_ 770 CCU_EvaporatorTemp 80;
BA_ "GenSigTimeoutTime_ALL" SG_ 770 CCU_EvaporatorTemp 5000;
BA_ "InvalidValue" SG_ 770 CCU_EvaporatorTemp "FFh";
BA_ "GenSigStartValue" SG_ 773 HtrMediumOutletTemp 80;
BA_ "GenSigTimeoutTime_ALL" SG_ 773 HtrMediumOutletTemp 500;
BA_ "InvalidValue" SG_ 773 HtrMediumOutletTemp "1FFh";
BA_ "GenSigTimeoutTime_ALL" SG_ 773 CcuHtrOnOffSts 500;
BA_ "InvalidValue" SG_ 773 CcuHtrOnOffSts "7h";
BA_ "GenSigTimeoutTime_ALL" SG_ 773 EcompOnOffSts 500;
BA_ "InvalidValue" SG_ 773 EcompOnOffSts "3h";
BA_ "GenSigStartValue" SG_ 773 HtrMediumInletTemp 80;
BA_ "GenSigTimeoutTime_ALL" SG_ 773 HtrMediumInletTemp 500;
BA_ "InvalidValue" SG_ 773 HtrMediumInletTemp "1FFh";
BA_ "GenSigTimeoutTime_ALL" SG_ 773 ECompRpm 500;
BA_ "InvalidValue" SG_ 773 ECompRpm "FFFFh";
BA_ "GenSigTimeoutTime_ALL" SG_ 773 ECompPowerConsumption 500;
BA_ "InvalidValue" SG_ 773 ECompPowerConsumption "null";
BA_ "GenSigTimeoutTime_ALL" SG_ 774 CCU_EcompOnOffRequest 500;
BA_ "InvalidValue" SG_ 774 CCU_EcompOnOffRequest "3h";
BA_ "GenSigTimeoutTime_ALL" SG_ 774 CCU_HtrOnOffRequest 500;
BA_ "InvalidValue" SG_ 774 CCU_HtrOnOffRequest "3h";
BA_ "GenSigTimeoutTime_ALL" SG_ 774 CCU_AcOffCode_CCU 500;
BA_ "InvalidValue" SG_ 774 CCU_AcOffCode_CCU "FFh";
BA_ "GenSigTimeoutTime_ALL" SG_ 774 CCU_CoolPowerDemand 500;
BA_ "InvalidValue" SG_ 774 CCU_CoolPowerDemand "FFh";
BA_ "GenSigTimeoutTime_ALL" SG_ 774 CCU_HeatPowerDemand 500;
BA_ "InvalidValue" SG_ 774 CCU_HeatPowerDemand "FFh";
BA_ "GenSigTimeoutTime_ALL" SG_ 774 CCU_PTCOffCode_CCU 500;
BA_ "InvalidValue" SG_ 774 CCU_PTCOffCode_CCU "FFh";
BA_ "GenSigTimeoutTime_ALL" SG_ 774 CCU_CoolDemand 500;
BA_ "InvalidValue" SG_ 774 CCU_CoolDemand "FFh";
BA_ "GenSigTimeoutTime_ALL" SG_ 774 CCU_HeatDemand 500;
BA_ "InvalidValue" SG_ 774 CCU_HeatDemand "FFh";
BA_ "GenSigTimeoutTime_ALL" SG_ 775 CHKSM_CPD_Output_1 5000;
BA_ "InvalidValue" SG_ 775 CHKSM_CPD_Output_1 "null";
BA_ "GenSigTimeoutTime_ALL" SG_ 775 ALV_CPD_Output_1 5000;
BA_ "InvalidValue" SG_ 775 ALV_CPD_Output_1 "Fh";
BA_ "GenSigTimeoutTime_ALL" SG_ 775 OUT_Alert_TO_BCM 5000;
BA_ "InvalidValue" SG_ 775 OUT_Alert_TO_BCM "7h";
BA_ "GenSigTimeoutTime_ALL" SG_ 775 CPD_State_information 5000;
BA_ "InvalidValue" SG_ 775 CPD_State_information "null";
BA_ "GenSigSendType" SG_ 784 CCUR_STAT_IonButton 4;
BA_ "InvalidValue" SG_ 784 CCUR_STAT_IonButton "3h";
BA_ "GenSigSendType" SG_ 784 CCUR_STAT_Defrost 4;
BA_ "InvalidValue" SG_ 784 CCUR_STAT_Defrost "3h";
BA_ "GenSigSendType" SG_ 784 CCUR_STAT_Auto 4;
BA_ "InvalidValue" SG_ 784 CCUR_STAT_Auto "3h";
BA_ "GenSigSendType" SG_ 784 CCUR_STAT_Aircondition 4;
BA_ "InvalidValue" SG_ 784 CCUR_STAT_Aircondition "3h";
BA_ "GenSigSendType" SG_ 784 CCUR_STAT_FlapPos 4;
BA_ "InvalidValue" SG_ 784 CCUR_STAT_FlapPos "7h";
BA_ "GenSigSendType" SG_ 784 CCUR_STAT_FanSpeed 4;
BA_ "InvalidValue" SG_ 784 CCUR_STAT_FanSpeed "Fh";
BA_ "GenSigSendType" SG_ 784 CCUR_STAT_PTC_Heater 4;
BA_ "InvalidValue" SG_ 784 CCUR_STAT_PTC_Heater "7h";
BA_ "GenSigSendType" SG_ 784 CCUR_STAT_OnOff 4;
BA_ "GenSigStartValue" SG_ 784 CCUR_STAT_OnOff 3;
BA_ "InvalidValue" SG_ 784 CCUR_STAT_OnOff "3h";
BA_ "GenSigSendType" SG_ 784 CCUR_STAT_MaxAc 4;
BA_ "InvalidValue" SG_ 784 CCUR_STAT_MaxAc "3h";
BA_ "GenSigSendType" SG_ 784 CCUR_STAT_SyncClimateZone 4;
BA_ "InvalidValue" SG_ 784 CCUR_STAT_SyncClimateZone "3h";
BA_ "GenSigSendType" SG_ 784 CCUR_STAT_RecircFlap 4;
BA_ "GenSigStartValue" SG_ 784 CCUR_STAT_RecircFlap 1;
BA_ "InvalidValue" SG_ 784 CCUR_STAT_RecircFlap "3h";
BA_ "GenSigSendType" SG_ 784 CCUR_STAT_TempRear 4;
BA_ "GenSigStartValue" SG_ 784 CCUR_STAT_TempRear 40;
BA_ "InvalidValue" SG_ 784 CCUR_STAT_TempRear "null";
BA_ "GenSigTimeoutTime_ALL" SG_ 806 CHSKM_POD_StatusDCDC1 500;
BA_ "GenSigTimeoutTime_ALL" SG_ 806 ALV_POD_StatusDCDC1 500;
BA_ "InvalidValue" SG_ 806 ALV_POD_StatusDCDC1 "Fh";
BA_ "GenSigTimeoutTime_ALL" SG_ 806 POD_statusDCDC 500;
BA_ "InvalidValue" SG_ 806 POD_statusDCDC "7h";
BA_ "GenSigTimeoutTime_ALL" SG_ 808 T_SEC_COU_REL 5000;
BA_ "InvalidValue" SG_ 808 T_SEC_COU_REL "FFFFFFFFh";
BA_ "GenSigTimeoutTime_ALL" SG_ 808 T_DAY_COU_ABSL 5000;
BA_ "InvalidValue" SG_ 808 T_DAY_COU_ABSL "FFFFh";
BA_ "GenSigTimeoutTime_ALL" SG_ 809 CRC_BCM_ODO 5000;
BA_ "InvalidValue" SG_ 809 CRC_BCM_ODO "null";
BA_ "GenSigTimeoutTime_ALL" SG_ 809 ALIV_BCM_ODO 5000;
BA_ "InvalidValue" SG_ 809 ALIV_BCM_ODO "Fh";
BA_ "GenSigTimeoutTime_ALL" SG_ 809 Odometer_BCM 5000;
BA_ "InvalidValue" SG_ 809 Odometer_BCM "FFFFFh";
BA_ "GenSigTimeoutTime_ALL" SG_ 809 SECCAN_BCM_ODO 5000;
BA_ "InvalidValue" SG_ 809 SECCAN_BCM_ODO "null";
BA_ "GenSigTimeoutTime_ALL" SG_ 812 CRC_HGLV_EHC 1000;
BA_ "InvalidValue" SG_ 812 CRC_HGLV_EHC "null";
BA_ "GenSigTimeoutTime_ALL" SG_ 812 ALIV_HGLV_EHC 1000;
BA_ "InvalidValue" SG_ 812 ALIV_HGLV_EHC "Fh";
BA_ "GenSigStartValue" SG_ 812 HGLV_RLH_EHC 127;
BA_ "GenSigTimeoutTime_ALL" SG_ 812 HGLV_RLH_EHC 1000;
BA_ "InvalidValue" SG_ 812 HGLV_RLH_EHC "null";
BA_ "GenSigStartValue" SG_ 812 HGLV_RRH_EHC 127;
BA_ "GenSigTimeoutTime_ALL" SG_ 812 HGLV_RRH_EHC 1000;
BA_ "InvalidValue" SG_ 812 HGLV_RRH_EHC "null";
BA_ "GenSigTimeoutTime_ALL" SG_ 812 QU_HGLV_RLH_EHC 1000;
BA_ "InvalidValue" SG_ 812 QU_HGLV_RLH_EHC "null";
BA_ "GenSigTimeoutTime_ALL" SG_ 812 QU_HGLV_RRH_EHC 1000;
BA_ "InvalidValue" SG_ 812 QU_HGLV_RRH_EHC "null";
BA_ "GenSigTimeoutTime_ALL" SG_ 814 CRC_AEB_STATUS 200;
BA_ "InvalidValue" SG_ 814 Alive_AEB_STATUS "Fh";
BA_ "GenSigTimeoutTime_ALL" SG_ 814 Alive_AEB_STATUS 200;
BA_ "GenSigTimeoutTime_ALL" SG_ 814 ADAS_AEB_Braking_Progress 200;
BA_ "GenSigTimeoutTime_ALL" SG_ 816 MILE_KM 500;
BA_ "InvalidValue" SG_ 816 MILE_KM "FFFFFFh";
BA_ "GenSigTimeoutTime_ALL" SG_ 816 FLLV_FUTA 500;
BA_ "InvalidValue" SG_ 816 FLLV_FUTA "FFh";
BA_ "GenSigTimeoutTime_ALL" SG_ 816 RNG 500;
BA_ "InvalidValue" SG_ 816 RNG "FFFh";
BA_ "GenSigTimeoutTime_ALL" SG_ 816 ST_FLLV_FUTA_SPAR 500;
BA_ "InvalidValue" SG_ 816 ST_FLLV_FUTA_SPAR "3h";
BA_ "InvalidValue" SG_ 819 Checksum_0x333 "0";
BA_ "InvalidValue" SG_ 819 Rolling_Counter_0x333 "Fh";
BA_ "InvalidValue" SG_ 819 ADAS_RadarRight_Cal_Status "0";
BA_ "InvalidValue" SG_ 819 ADAS_RadarLeft_Cal_Status "0";
BA_ "InvalidValue" SG_ 819 ADAS_RadarRight_DynaCal_Status "0";
BA_ "InvalidValue" SG_ 819 ADAS_MasterSRR_check "0";
BA_ "InvalidValue" SG_ 819 ADAS_SlaveSRR_check "0";
BA_ "InvalidValue" SG_ 819 ADAS_RadarLeft_DynaCal_Status "0";
BA_ "InvalidValue" SG_ 819 ADAS_CalSensorMasterProgress "FFh";
BA_ "InvalidValue" SG_ 819 ADAS_CalSensorSlaverProgress "FFh";
BA_ "InvalidValue" SG_ 819 ADAS_Cal_LeftInstallDeviation "0";
BA_ "InvalidValue" SG_ 819 ADAS_Cal_RightInstallDeviation "0";
BA_ "GenSigTimeoutTime_ALL" SG_ 850 CHKSM_ADAS_AHB_DOW 500;
BA_ "GenSigTimeoutTime_ALL" SG_ 850 ALV_ADAS_AHB_DOW 500;
BA_ "InvalidValue" SG_ 850 ALV_ADAS_AHB_DOW "Fh";
BA_ "GenSigTimeoutTime_ALL" SG_ 850 ADAS_AHB_check 500;
BA_ "InvalidValue" SG_ 850 ADAS_AHB_check "3h";
BA_ "GenSigTimeoutTime_ALL" SG_ 850 ADAS_AHB_state 500;
BA_ "InvalidValue" SG_ 850 ADAS_AHB_state "3h";
BA_ "GenSigTimeoutTime_ALL" SG_ 850 ADAS_DOW_WarnRight 500;
BA_ "InvalidValue" SG_ 850 ADAS_DOW_WarnRight "3h";
BA_ "GenSigTimeoutTime_ALL" SG_ 850 ADAS_DOW_WarnLeft 500;
BA_ "InvalidValue" SG_ 850 ADAS_DOW_WarnLeft "3h";
BA_ "GenSigTimeoutTime_ALL" SG_ 850 ADAS_AHB_RBPos 500;
BA_ "InvalidValue" SG_ 850 ADAS_AHB_RBPos "7h";
BA_ "GenSigTimeoutTime_ALL" SG_ 850 ADAS_AHB_LBPos 500;
BA_ "InvalidValue" SG_ 850 ADAS_AHB_LBPos "7h";
BA_ "GenSigTimeoutTime_ALL" SG_ 851 ADAS_ACC_State 500;
BA_ "GenSigTimeoutTime_ALL" SG_ 851 ADAS_ACC_check 500;
BA_ "InvalidValue" SG_ 851 ADAS_ACC_check "3h";
BA_ "GenSigTimeoutTime_ALL" SG_ 852 CHKSM_MHU_ADAS_req 500;
BA_ "InvalidValue" SG_ 852 ALV_MHU_ADAS_req "Fh";
BA_ "GenSigTimeoutTime_ALL" SG_ 852 ALV_MHU_ADAS_req 500;
BA_ "GenSigStartValue" SG_ 852 MHU_FCW_Mode 1;
BA_ "GenSigTimeoutTime_ALL" SG_ 852 MHU_FCW_Mode 500;
BA_ "InvalidValue" SG_ 852 MHU_FCW_Mode "3h";
BA_ "GenSigStartValue" SG_ 852 MHU_FCW_sens 1;
BA_ "GenSigTimeoutTime_ALL" SG_ 852 MHU_FCW_sens 500;
BA_ "InvalidValue" SG_ 852 MHU_FCW_sens "3h";
BA_ "GenSigStartValue" SG_ 852 MHU_AEB_Mode 1;
BA_ "GenSigTimeoutTime_ALL" SG_ 852 MHU_AEB_Mode 500;
BA_ "InvalidValue" SG_ 852 MHU_AEB_Mode "3h";
BA_ "GenSigStartValue" SG_ 852 MHU_RAEB_Mode 1;
BA_ "GenSigTimeoutTime_ALL" SG_ 852 MHU_RAEB_Mode 500;
BA_ "InvalidValue" SG_ 852 MHU_RAEB_Mode "3h";
BA_ "GenSigStartValue" SG_ 852 MHU_LA_sens 1;
BA_ "GenSigTimeoutTime_ALL" SG_ 852 MHU_LA_sens 500;
BA_ "InvalidValue" SG_ 852 MHU_LA_sens "3h";
BA_ "GenSigTimeoutTime_ALL" SG_ 852 MHU_LA_AudWarning 500;
BA_ "InvalidValue" SG_ 852 MHU_LA_AudWarning "3h";
BA_ "GenSigStartValue" SG_ 852 MHU_BSD_On 1;
BA_ "GenSigTimeoutTime_ALL" SG_ 852 MHU_BSD_On 500;
BA_ "InvalidValue" SG_ 852 MHU_BSD_On "3h";
BA_ "GenSigStartValue" SG_ 852 MHU_BSD_sens 1;
BA_ "GenSigTimeoutTime_ALL" SG_ 852 MHU_BSD_sens 500;
BA_ "InvalidValue" SG_ 852 MHU_BSD_sens "3h";
BA_ "GenSigTimeoutTime_ALL" SG_ 852 MHU_BSD_AudWarning 500;
BA_ "InvalidValue" SG_ 852 MHU_BSD_AudWarning "3h";
BA_ "GenSigStartValue" SG_ 852 MHU_RCTA_On 1;
BA_ "GenSigTimeoutTime_ALL" SG_ 852 MHU_RCTA_On 500;
BA_ "InvalidValue" SG_ 852 MHU_RCTA_On "3h";
BA_ "GenSigStartValue" SG_ 852 MHU_RCTA_sens 1;
BA_ "GenSigTimeoutTime_ALL" SG_ 852 MHU_RCTA_sens 500;
BA_ "InvalidValue" SG_ 852 MHU_RCTA_sens "3h";
BA_ "GenSigStartValue" SG_ 852 MHU_PA_On 1;
BA_ "GenSigTimeoutTime_ALL" SG_ 852 MHU_PA_On 500;
BA_ "InvalidValue" SG_ 852 MHU_PA_On "3h";
BA_ "GenSigTimeoutTime_ALL" SG_ 852 MHU_AHB_On 500;
BA_ "InvalidValue" SG_ 852 MHU_AHB_On "3h";
BA_ "GenSigTimeoutTime_ALL" SG_ 852 MHU_IA_Mode 500;
BA_ "InvalidValue" SG_ 852 MHU_IA_Mode "3h";
BA_ "GenSigStartValue" SG_ 852 MHU_TSR_Mode 1;
BA_ "GenSigTimeoutTime_ALL" SG_ 852 MHU_TSR_Mode 500;
BA_ "InvalidValue" SG_ 852 MHU_TSR_Mode "3h";
BA_ "GenSigStartValue" SG_ 852 MHU_DOW_Mode 2;
BA_ "GenSigTimeoutTime_ALL" SG_ 852 MHU_DOW_Mode 500;
BA_ "InvalidValue" SG_ 852 MHU_DOW_Mode "3h";
BA_ "GenSigStartValue" SG_ 852 MHU_AHB_sens 1;
BA_ "GenSigTimeoutTime_ALL" SG_ 852 MHU_AHB_sens 500;
BA_ "InvalidValue" SG_ 852 MHU_AHB_sens "3h";
BA_ "GenSigStartValue" SG_ 852 MHU_LA_Mode 3;
BA_ "GenSigTimeoutTime_ALL" SG_ 852 MHU_LA_Mode 500;
BA_ "InvalidValue" SG_ 852 MHU_LA_Mode "3h";
BA_ "GenSigStartValue" SG_ 852 MHU_SET_TSR_AudWarn 1;
BA_ "GenSigTimeoutTime_ALL" SG_ 852 MHU_SET_TSR_AudWarn 500;
BA_ "InvalidValue" SG_ 852 MHU_SET_TSR_AudWarn "3h";
BA_ "GenSigStartValue" SG_ 852 MHU_SET_TSR_SLAert 1;
BA_ "GenSigTimeoutTime_ALL" SG_ 852 MHU_SET_TSR_SLAert 500;
BA_ "InvalidValue" SG_ 852 MHU_SET_TSR_SLAert "3h";
BA_ "GenSigTimeoutTime_ALL" SG_ 852 MHU_ESA_ON 500;
BA_ "GenSigStartValue" SG_ 852 MHU_ELKA_ON 1;
BA_ "GenSigTimeoutTime_ALL" SG_ 852 MHU_ELKA_ON 500;
BA_ "InvalidValue" SG_ 852 MHU_ELKA_ON "-";
BA_ "GenSigTimeoutTime_ALL" SG_ 880 CRC_MHU_SBR_Status 1500;
BA_ "GenSigTimeoutTime_ALL" SG_ 880 ALV_MHU_SBR_Status 1500;
BA_ "InvalidValue" SG_ 880 ALV_MHU_SBR_Status "Fh";
BA_ "GenSigStartValue" SG_ 880 SBR_STAT_Chime 3;
BA_ "GenSigTimeoutTime_ALL" SG_ 880 SBR_STAT_Chime 1500;
BA_ "InvalidValue" SG_ 880 SBR_STAT_Chime "3h";
BA_ "GenSigStartValue" SG_ 880 SBR_STAT_Telltale 3;
BA_ "GenSigTimeoutTime_ALL" SG_ 880 SBR_STAT_Telltale 1500;
BA_ "InvalidValue" SG_ 880 SBR_STAT_Telltale "3h";
BA_ "GenSigTimeoutTime_ALL" SG_ 880 SBR_STAT_Active 1500;
BA_ "GenSigTimeoutTime_ALL" SG_ 886 CHKSM_USS_RPA 1000;
BA_ "GenSigTimeoutTime_ALL" SG_ 886 ALV_USS_RPA 1000;
BA_ "GenSigStartValue" SG_ 886 USS_RPA_state 7;
BA_ "GenSigTimeoutTime_ALL" SG_ 886 USS_RPA_state 1000;
BA_ "InvalidValue" SG_ 886 USS_RPA_state "7h";
BA_ "GenSigTimeoutTime_ALL" SG_ 886 USS_RPA_AlertRLI 1000;
BA_ "InvalidValue" SG_ 886 USS_RPA_AlertRLI "7h";
BA_ "GenSigTimeoutTime_ALL" SG_ 886 USS_RPA_AlertRLO 1000;
BA_ "InvalidValue" SG_ 886 USS_RPA_AlertRLO "7h";
BA_ "GenSigTimeoutTime_ALL" SG_ 886 USS_RPA_AlertRRI 1000;
BA_ "InvalidValue" SG_ 886 USS_RPA_AlertRRI "7h";
BA_ "GenSigTimeoutTime_ALL" SG_ 886 USS_RPA_AlertRRO 1000;
BA_ "InvalidValue" SG_ 886 USS_RPA_AlertRRO "7h";
BA_ "GenSigStartValue" SG_ 886 USS_RPA_SensorRLI 3;
BA_ "GenSigTimeoutTime_ALL" SG_ 886 USS_RPA_SensorRLI 1000;
BA_ "InvalidValue" SG_ 886 USS_RPA_SensorRLI "3h";
BA_ "GenSigStartValue" SG_ 886 USS_RPA_SensorRLO 3;
BA_ "GenSigTimeoutTime_ALL" SG_ 886 USS_RPA_SensorRLO 1000;
BA_ "InvalidValue" SG_ 886 USS_RPA_SensorRLO "3h";
BA_ "GenSigStartValue" SG_ 886 USS_RPA_SensorRRI 3;
BA_ "GenSigTimeoutTime_ALL" SG_ 886 USS_RPA_SensorRRI 1000;
BA_ "InvalidValue" SG_ 886 USS_RPA_SensorRRI "3h";
BA_ "GenSigStartValue" SG_ 886 USS_RPA_SensorRRO 3;
BA_ "GenSigTimeoutTime_ALL" SG_ 886 USS_RPA_SensorRRO 1000;
BA_ "InvalidValue" SG_ 886 USS_RPA_SensorRRO "3h";
BA_ "GenSigTimeoutTime_ALL" SG_ 887 CHKSM_USS_FPA 1000;
BA_ "GenSigTimeoutTime_ALL" SG_ 887 ALV_USS_FPA 1000;
BA_ "GenSigStartValue" SG_ 887 USS_FPA_state 7;
BA_ "GenSigTimeoutTime_ALL" SG_ 887 USS_FPA_state 1000;
BA_ "InvalidValue" SG_ 887 USS_FPA_state "7h";
BA_ "GenSigTimeoutTime_ALL" SG_ 887 USS_FPA_AutoOn_Feed 1000;
BA_ "GenSigTimeoutTime_ALL" SG_ 887 USS_FPA_AlertFLI 1000;
BA_ "InvalidValue" SG_ 887 USS_FPA_AlertFLI "7h";
BA_ "GenSigTimeoutTime_ALL" SG_ 887 USS_FPA_AlertFLO 1000;
BA_ "InvalidValue" SG_ 887 USS_FPA_AlertFLO "7h";
BA_ "GenSigTimeoutTime_ALL" SG_ 887 USS_FPA_AlertFRI 1000;
BA_ "InvalidValue" SG_ 887 USS_FPA_AlertFRI "7h";
BA_ "GenSigTimeoutTime_ALL" SG_ 887 USS_FPA_AlertFRO 1000;
BA_ "InvalidValue" SG_ 887 USS_FPA_AlertFRO "7h";
BA_ "GenSigStartValue" SG_ 887 USS_FPA_SensorFLI 3;
BA_ "GenSigTimeoutTime_ALL" SG_ 887 USS_FPA_SensorFLI 1000;
BA_ "InvalidValue" SG_ 887 USS_FPA_SensorFLI "3h";
BA_ "GenSigStartValue" SG_ 887 USS_FPA_SensorFLO 3;
BA_ "GenSigTimeoutTime_ALL" SG_ 887 USS_FPA_SensorFLO 1000;
BA_ "InvalidValue" SG_ 887 USS_FPA_SensorFLO "3h";
BA_ "GenSigStartValue" SG_ 887 USS_FPA_SensorFRI 3;
BA_ "GenSigTimeoutTime_ALL" SG_ 887 USS_FPA_SensorFRI 1000;
BA_ "InvalidValue" SG_ 887 USS_FPA_SensorFRI "3h";
BA_ "GenSigStartValue" SG_ 887 USS_FPA_SensorFRO 3;
BA_ "GenSigTimeoutTime_ALL" SG_ 887 USS_FPA_SensorFRO 1000;
BA_ "InvalidValue" SG_ 887 USS_FPA_SensorFRO "3h";
BA_ "GenSigTimeoutTime_ALL" SG_ 888 CHKSM_RawDist_RPA 1000;
BA_ "GenSigTimeoutTime_ALL" SG_ 888 ALV_RawDist_RPA 1000;
BA_ "GenSigStartValue" SG_ 888 USS_RPA_DistRLI 255;
BA_ "GenSigTimeoutTime_ALL" SG_ 888 USS_RPA_DistRLI 1000;
BA_ "InvalidValue" SG_ 888 USS_RPA_DistRLI "FFh";
BA_ "GenSigStartValue" SG_ 888 USS_RPA_DistRLO 255;
BA_ "GenSigTimeoutTime_ALL" SG_ 888 USS_RPA_DistRLO 1000;
BA_ "InvalidValue" SG_ 888 USS_RPA_DistRLO "FFh";
BA_ "GenSigStartValue" SG_ 888 USS_RPA_DistRRI 255;
BA_ "GenSigTimeoutTime_ALL" SG_ 888 USS_RPA_DistRRI 1000;
BA_ "InvalidValue" SG_ 888 USS_RPA_DistRRI "FFh";
BA_ "GenSigStartValue" SG_ 888 USS_RPA_DistRRO 255;
BA_ "GenSigTimeoutTime_ALL" SG_ 888 USS_RPA_DistRRO 1000;
BA_ "InvalidValue" SG_ 888 USS_RPA_DistRRO "FFh";
BA_ "GenSigTimeoutTime_ALL" SG_ 889 CHKSM_RawDist_FPA 1000;
BA_ "GenSigTimeoutTime_ALL" SG_ 889 ALV_RawDist_FPA 1000;
BA_ "GenSigStartValue" SG_ 889 USS_FPA_DistFLI 255;
BA_ "GenSigTimeoutTime_ALL" SG_ 889 USS_FPA_DistFLI 1000;
BA_ "InvalidValue" SG_ 889 USS_FPA_DistFLI "FFh";
BA_ "GenSigStartValue" SG_ 889 USS_FPA_DistFLO 255;
BA_ "GenSigTimeoutTime_ALL" SG_ 889 USS_FPA_DistFLO 1000;
BA_ "InvalidValue" SG_ 889 USS_FPA_DistFLO "FFh";
BA_ "GenSigStartValue" SG_ 889 USS_FPA_DistFRI 255;
BA_ "GenSigTimeoutTime_ALL" SG_ 889 USS_FPA_DistFRI 1000;
BA_ "InvalidValue" SG_ 889 USS_FPA_DistFRI "FFh";
BA_ "GenSigStartValue" SG_ 889 USS_FPA_DistFRO 255;
BA_ "GenSigTimeoutTime_ALL" SG_ 889 USS_FPA_DistFRO 1000;
BA_ "InvalidValue" SG_ 889 USS_FPA_DistFRO "FFh";
VAL_ 521 PAS_RAEB_check 0 "Available" 1 "Temporarily not available" 2 "Permanently not available" ;
VAL_ 521 PAS_RAEB_State 0 "Off" 1 "Inactive" 2 "Ready" 3 "PreFill" 4 "AEB Active" 5 "Standstill" 6 "Finished With Override" 7 "Finished Without Override" 8 "Error" 9 "Reserved" 10 "Reserved" 11 "Reserved" 12 "Reserved" 13 "Reserved" 14 "Reserved" 15 "Reserved" ;
VAL_ 521 PAS_RAEB_Warning 0 "No warning" 1 "Braking" 2 "Postfeedback" ;
VAL_ 522 ETG_Lift_Gate_Status 0 "Fully closed" 1 "Fully opened" 2 "Stoped halfway" 3 "Ready to open" 4 "Opening" 5 "Ready to close" 6 "Closing" 7 "SNA (Signal not available)" ;
VAL_ 522 ETG_Power_Latch_Status 0 "uninitialized" 1 "Stoped" 2 "Cinching" 3 "Cinching reset" 4 "Releasing" 5 "Releasing reset" 7 "SNA" ;
VAL_ 522 ETG_Latch_Segment 0 "Full latch" 1 "Half latch" 2 "Open latch" 3 "SNA" ;
VAL_ 522 ETG_DSW_Status 0 "Not active" 1 "Active" ;
VAL_ 522 ETG_GSW_Status 0 "Not active" 1 "Active" ;
VAL_ 522 ETG_LTS_Status 0 "Not active" 1 "Active" ;
VAL_ 522 ETG_RTS_Status 0 "Not active" 1 "Active" ;
VAL_ 522 ETG_HAL_Status 0 "Low level" 1 "High level" ;
VAL_ 522 ETG_FUL_Status 0 "Low level" 1 "High level" ;
VAL_ 522 ETG_AJR_Status 0 "Low level" 1 "High level" ;
VAL_ 522 ETG_NTL_Status 0 "Low level" 1 "High level" ;
VAL_ 522 ETG_ERR_Voltage 0 "Normal" 1 "Under voltage" 2 "Over voltage" ;
VAL_ 522 ETG_ERR_Left_Motor 0 "Normal" 1 "Open circuit" 2 "short circuit" ;
VAL_ 522 ETG_ERR_Right_Motor 0 "Normal" 1 "Open circuit" 2 "short circuit" ;
VAL_ 522 ETG_ERR_Latch 0 "Normal" 1 "Open circuit" 2 "short circuit" ;
VAL_ 522 ETG_ERR_Hall 0 "Normal" 1 "Hall power short circuit" 2 "Hall position out of range" 3 "Hall signal out of sync" ;
VAL_ 522 ETG_Lift_Motor_Stall 0 "Not active" 1 "Active" ;
VAL_ 522 ETG_Lift_Motor_AntiPinch 0 "Not active" 1 "Active" ;
VAL_ 522 ETG_Lift_Motor_Thermal 0 "Not active" 1 "Active" ;
VAL_ 522 ETG_Power_Latch_Thermal 0 "Not active" 1 "Active" ;
VAL_ 522 ETG_Abuse_Protection 0 "Not active" 1 "Active" ;
VAL_ 523 FKS_RespError 0 "Ok" 1 "Error active" ;
VAL_ 523 FKS_OpenReq 0 "Idle" 1 "Operation Request" 2 "Invalid" 3 "Invalid" ;
VAL_ 523 FKS_HWError 0 "No Error" 1 "Error" ;
VAL_ 523 FKS_AntennaError 0 "No Error" 1 "Bottom or Top Sensor not connected" 2 "Bottom sensor short to Power or GND" 3 "Top sensor short to Power or GND" ;
VAL_ 523 FKS_OverVolDected 0 "No Error" 1 "Error" ;
VAL_ 523 FKS_UnderVolDected 0 "No Error" 1 "Error" ;
VAL_ 523 FKS_activate_deactivate 0 "Deactivated" 1 "Activated" 2 "Reserved" 3 "Signal invalid" ;
VAL_ 525 ESPTransRequestType 0 "No action" 1 "Inhibit upshift" 2 "Inhibit downshift" 3 "Hold gear" ;
VAL_ 525 ABSFault 0 "No fault" 1 "Fault" ;
VAL_ 525 ABSActive 0 "Inactive" 1 "Active" ;
VAL_ 525 MCPressureSts 0 "Valid" 1 "Invalid" ;
VAL_ 525 VehicleSpdSts 0 "Valid" 1 "Invalid" ;
VAL_ 525 BRAKE_LightonRequestEPBi 0 "Brake light OFF" 1 "Brake light ON" 2 "Reserved" 3 "Signal not available" ;
VAL_ 525 VDCActive 0 "Inactive" 1 "Active" ;
VAL_ 525 TCSActive 0 "Inactive" 1 "Active" ;
VAL_ 525 TCSAvailable 0 "Avialable" 1 "Unavailable" ;
VAL_ 525 IDBActive 0 "Inactive" 1 "Active" ;
VAL_ 525 IDBFault 0 "No fault" 1 "Fault" ;
VAL_ 525 IDB_Power_Stage 0 "Motor Max Power 150Kw" 1 "Motor Max Power 300Kw" 2 "Reserved" 3 "Reserved" 15 "Invalid" ;
VAL_ 527 ADAS_BCM_HeadlightReq 0 "No request" 1 "Request turn on" ;
VAL_ 527 ADAS_BCM_FoldMirrorReq 0 "No request" 1 "Fold in" 2 "Fold out" 3 "Reserved" ;
VAL_ 527 ADAS_BCM_Status 0 "Off" 1 "Standby" 2 "Enable" 3 "Active" 4 "Finished" 5 "Suspend" 6 "Abort" 7 "Failed" ;
VAL_ 527 ADAS_BCM_IndicatorlightReq 0 "No request" 1 "Left" 2 "Right" 3 "Hazard" 4 "Turn Indicator Off" ;
VAL_ 528 RCU_DAA_NoOpDoorOpen_1 0 "No Error" 1 "Error" ;
VAL_ 528 RCU_EPBParkingStatus 0 "Both brakes released" 1 "both brakes applied" 2 "Both brakes in operation (applying/releasing)" 3 "unknown" ;
VAL_ 528 EPB_Swch_Mafnc 0 "No Error" 1 "Error" ;
VAL_ 528 RCU_ParkBrkApplied_1 0 "No Error" 1 "Error" ;
VAL_ 528 RCU_ReleaseEPB_Wo_PressBrk_1 0 "No Error" 1 "Error" ;
VAL_ 528 RCU_BrkForceNotEnough_1 0 "No Error" 1 "Error" ;
VAL_ 528 RCU_ParkOnSteepInclination_1 0 "No Error" 1 "Error" ;
VAL_ 528 RCU_ECD_RWU_active_1 0 "No Error" 1 "Error" ;
VAL_ 528 RCU_EHandBrk_fault_1 0 "No Error" 1 "Error" ;
VAL_ 528 RCU_BRAKE_LightonRequestEPBi 0 "Brake light OFF" 1 "Brake light ON" 2 "Reserved" 3 "Signal not available" ;
VAL_ 533 BMS_BatBalance_ERR 0 "Error" 1 "normal" ;
VAL_ 533 BMS_Balance_STS 0 "Inactive" 1 "active" ;
VAL_ 533 BMS_IGN_Sts 0 "OFF" 1 "ON" ;
VAL_ 533 BMS_HWCrash_Sts 0 "No Crash" 1 "Crash" ;
VAL_ 533 BMS_HVIL_STS 0 "Closed" 1 "Open & short to battery" 2 "short to ground" 3 "Signal invalid" ;
VAL_ 533 BMS_HVOnOff_STS 0 "HV Off" 1 "Precharge" 2 "HV On" 3 "Fail to HV on" ;
VAL_ 533 BMS_ERR_LEV 0 "No error" 1 "Warning" 2 "Limp Home" 3 "Power down without FTTI" 4 "Delay power down with FTTI" 5 "Emergency off condition" 6 "Fault, needs to shutdown and wakeup" 7 "Battery locked - reserved" ;
VAL_ 533 BMS_Sys_STS 0 "Initialization of power on, self-checking" 1 "Self-check passes, can be high-voltage" 2 "Successful High Voltage Power Up" 3 "Successful Power Down of HV" 4 "Power Down process" 5 "Successful Power Down" 6 "BCU Sleep mode" 7 "Failure, unable to operate" 8 "Invalid" ;
VAL_ 533 BMS_ISU_Status 0 "Normal (> 250 kOhms)" 1 "Level1 (<250 kOhms ~ >100 kOhms)" 3 "Level3 (<100 kOhms)" ;
VAL_ 533 BMS_HV_Sts 0 "HV Off" 1 "Pre Charge" 2 "HV On" 3 "Super_Fast_Charge" 4 "AC Charge" 5 "Undefined" 6 "Undefined" 7 "Undefined" 8 "Undefined" 9 "Undefined" ;
VAL_ 537 VCU_ChargeAllow 0 "Not allow" 1 "Allow" ;
VAL_ 540 FCAM_AEB_Warning 0 "No warning" 1 "Braking" 2 "Post Feedback" ;
VAL_ 540 FCAM_AEB_State 0 "OFF State" 1 "Stand by Mode" 2 "Active Mode" 3 "Hold Mode" ;
VAL_ 540 FCAM_AEB_check 0 "Available" 1 "Temporarily not available" 2 "Permanently not available" ;
VAL_ 544 MHU_SET_CCUR_AirCondition 0 "Not pressed" 1 "Pressed" 2 "Reserved" 3 "Signal invalid" ;
VAL_ 544 MHU_SET_CCUR_AutoAC 0 "Not pressed" 1 "Pressed" 2 "Reserved" 3 "Signal invalid" ;
VAL_ 544 MHU_SET_CCUR_RearLock 0 "Not pressed" 1 "Pressed" 2 "Reserved" 3 "Signal invalid" ;
VAL_ 544 MHU_SET_CCUR_MaxAc 0 "Not pressed" 1 "Pressed" 2 "Reserved" 3 "Signal invalid" ;
VAL_ 544 MHU_SET_CCUR_FanSpeed 0 "OFF" 1 "Level1" 2 "Level2" 3 "Level3" 4 "Level4" 5 "Level5" 6 "Level6" 7 "Signal invalid" ;
VAL_ 544 MHU_SET_CCUR_Recirculation 0 "Inside" 1 "Outside" 2 "Auto" 3 "Signal invalid" ;
VAL_ 544 MHU_SET_CCUR_Ion 0 "Not pressed" 1 "Pressed" 2 "Reserved" 3 "Signal invalid" ;
VAL_ 544 MHU_SET_CCUR_FlapPosition 0 "OFF" 1 "Face" 2 "Face and Feet" 3 "Feet" 4 "Feet and Defrost" 5 "Defrost" 6 "Default" 7 "Signal Invalid" ;
VAL_ 544 MHU_SET_CCUR_SyncClimateZone 0 "Not pressed" 1 "Pressed" 2 "Reserved" 3 "Signal invalid";
VAL_ 544 MHU_SET_CCUR_TempRear 32 "16" 33 "16.5" 34 "17" 35 "17.5" 36 "18" 37 "18.5" 38 "19" 39 "19.5" 40 "20" 41 "20.5" 42 "21" 43 "21.5" 44 "22" 45 "22.5" 46 "23" 47 "23.5" 48 "24" 49 "24.5" 50 "25" 51 "25.5" 52 "26" 53 "26.5" 54 "27" 55 "27.5" 56 "28" 57 "28.5" 58 "29" 59 "29.5" 60 "30" 61 "30.5" 62 "31" 63 "31.5" 64 "32" 255 "Invalid Value";
VAL_ 544 MHU_SET_CCUR_FrontDefrost 0 "Not pressed" 1 "Pressed" 2 "Reserved" 3 "Signal invalid";
VAL_ 546 FRONT_SET_Rear_AirCondition 0 "Not pressed" 1 "Pressed" 2 "Reserved" 3 "Signal invalid" ;
VAL_ 547 NDoorFLVehicleLocked 0 "Default (Locked)" 1 "Reserved" 2 "Unlocked (Inactive)" 3 "Locked (Full Decouple)" ;
VAL_ 547 NDoorFLVehicleMoving 0 "default (in motion)" 1 "Reserved" 2 "static (inactive)" 3 "in motion (decouple external)" ;
VAL_ 547 NDoorFLOpenInvRequested 0 "default (release inactive)" 1 "Reserved" 2 "open (active release request)" 3 "close (release inactive)" ;
VAL_ 547 NDoorFLOpenRequested 0 "close (release inactive)" 1 " open (release request active)" 2 "Reserved" 3 "default (release inactive)" ;
VAL_ 547 NDoorFLChildLocked 0 "default (locked)" 2 "unlocked (inactive)" 3 "locked (full decouple)" ;
VAL_ 547 NDoorFLVehicleCrash 0 "default (locked)" 2 "Not trigger (inactive)" 3 "Trigger (full decouple)" ;
VAL_ 547 NDoorFLCloseInvRequested 0 "default (Cinch latching  inactive)" 1 "Reserved" 2 "open (active Cinch latching request)" 3 "close (Cinch latching  inactive" ;
VAL_ 547 NDoorFLCloseRequested 0 "Default (Cinch Latching Inactive)" 1 "Reserved" 2 "Open (Active Cinch Latching Request)" 3 "Close (Cinch Latching Inactive)" ;
VAL_ 548 VCU_BMS_PTCOnOff_Sts 0 "off" 1 "on" ;
VAL_ 548 VCU_BMS_ValveOnOff_Sts 0 "close" 1 "open" ;
VAL_ 548 VCU_BMS_PumpFB 0 "OFF" 1 "ON" 2 "Fault" 3 "Reserve" ;
VAL_ 561 NDoorFLHomeSignal 0 "Home" 1 "not Home" ;
VAL_ 561 NDoorFLSecondarySignal 0 "Secondary" 1 "Not Secondary" ;
VAL_ 561 NDoorFLPrimarySignal 0 "Primary" 1 "not Primary" ;
VAL_ 561 NDoorFLClawSignal 0 "Claw" 1 "Not Claw" ;
VAL_ 561 NDoorFLClawStatus 0 "Closed" 1 "Secondary" 2 "Signal Invalid" 3 "Signal Invalid" 4 "Signal Invalid" 5 "Open" 6 "Signal Invalid" 7 "Signal Invalid" 8 "Signal Invalid" 9 "Signal Invalid" 10 "Signal Invalid" 11 "Signal Invalid" 12 "Signal Invalid" 13 "Signal Invalid" 14 "Signal Invalid" 15 "Default" ;
VAL_ 561 BDLFLResponseError 0 "no error" 1 "error" ;
VAL_ 561 NDoorFLOutsideHandleFailure 0 "Default (No Failure)" 1 "EEPROM, ROM and DSP self-test" 2 "Magnetic field is too low" 3 "Magnetic field is too high" 4 "Overvoltage" 5 "Undervoltage" 6 "A/D converter clipping" 7 "Reserved" ;
VAL_ 561 NDoorFLOutsideHandleStatus 0 "Trigger" 1 "Not trigger" ;
VAL_ 561 NDoorLatchFLFailure 0 "no fault" 1 "fault code" 2 "fault code" 3 "fault code" 4 "fault code" 5 "fault code" 6 "fault code" 63 "fault code" ;
VAL_ 565 TowingDetected 0 "Towing not detected" 1 "Towing detected" 3 "Invalid" ;
VAL_ 565 TrailerDetected 0 "Trailer not detected" 1 "Trailer detected" 3 "Invalid" ;
VAL_ 569 NDoorRRHomeSignal 0 "Home" 1 "not Home" ;
VAL_ 569 NDoorRRSecondarySignal 0 "Secondary" 1 "not Secondary" ;
VAL_ 569 NDoorRRPrimarySignal 0 "Primary" 1 "Not Primary" ;
VAL_ 569 NDoorRRClawSignal 0 "Claw" 1 "not Claw" ;
VAL_ 569 NDoorRRClawStatus 0 "Closed" 1 "Secondary" 2 "Signal Invalid" 3 "Signal Invalid" 4 "Signal Invalid" 5 "Open" 6 "Signal Invalid" 7 "Signal Invalid" 8 "Signal Invalid" 9 "Signal Invalid" 10 "Signal Invalid" 11 "Signal Invalid" 12 "Signal Invalid" 13 "Signal Invalid" 14 "Signal Invalid" 15 "Default" ;
VAL_ 569 BDLRRResponseError 0 "no error" 1 "error" ;
VAL_ 569 NDoorRROutsideHandleFailure 0 "Default (No Failure)" 1 "EEPROM, ROM and DSP self-test" 2 "Magnetic field is too low" 3 "Magnetic field is too high" 4 "Overvoltage" 5 "Undervoltage" 6 "A/D converter clipping" 7 "Reserved" ;
VAL_ 569 NDoorRROutsideHandleStatus 0 "Trigger" 1 "Not trigger" ;
VAL_ 569 NDoorLatchRRFailure 0 "No Fault" 1 "Fault Code" 2 "Fault Code" 3 "Fault Code" 4 "Fault Code" 5 "Fault Code" 6 "Fault Code" 7 "Fault Code" 8 "Fault Code" 9 "Fault Code" 10 "Fault Code" 11 "Fault Code" 12 "Fault Code" 13 "Fault Code" 14 "Fault Code" 127 "Fault Code" ;
VAL_ 570 IDB_WheelDirection_FR 0 "Standstill" 1 "Forward" 2 "Backward" 3 "Invalid" ;
VAL_ 570 IDB_WheelDirection_FL 0 "Standstill" 1 "Forward" 2 "Backward" 3 "Invalid" ;
VAL_ 571 IDB_WheelDirection_RR 0 "Standstill" 1 "Forward" 2 "Backward" 3 "Invalid" ;
VAL_ 571 IDB_WheelDirection_RL 0 "Standstill" 1 "Forward" 2 "Backward" 3 "Invalid" ;
VAL_ 578 NDoorFRVehicleLocked 0 "default (locked)" 2 "unlocked (inactive)" 3 "locked (full decouple)" ;
VAL_ 578 NDoorFRVehicleMoving 0 "default (in motion)" 2 "static (inactive)" 3 "in motion (decouple external)" ;
VAL_ 578 NDoorFROpenInvRequested 0 "default (release inactive)" 2 "open (active release request)" 3 "close (release inactive)" ;
VAL_ 578 NDoorFROpenRequested 0 "close (release inactive)" 1 "open (release request active)" 3 "default (release inactive)" ;
VAL_ 578 NDoorFRChildLocked 0 "default (locked)" 2 "unlocked (inactive)" 3 "locked (full decouple)" ;
VAL_ 578 NDoorFRVehicleCrash 0 "default (locked)" 1 "Reserved" 2 "Not trigger (inactive)" 3 "Trigger (full decouple)" ;
VAL_ 578 NDoorFRCloseInvRequested 0 "default (Cinch latching  inactive)" 1 "Reserved" 2 "open (active Cinch latching request)" 3 "close (Cinch latching  inactive" ;
VAL_ 578 NDoorFRCloseRequested 0 "Default (Cinch Latching Inactive)" 1 "Reserved" 2 "Open (Active Cinch Latching Request)" 3 "Close (Cinch Latching Inactive)" ;
VAL_ 584 NDoorFRHomeSignal 0 "Home" 1 "not Home" ;
VAL_ 584 NDoorFRSecondarySignal 0 "Secondary" 1 "Not Secondary" ;
VAL_ 584 NDoorFRPrimarySignal 0 "Primary" 1 "Not Primary" ;
VAL_ 584 NDoorFRClawSignal 0 "Claw" 1 "not Claw" ;
VAL_ 584 NDoorFRClawStatus 0 "Closed" 1 "Secondary" 2 "Signal Invalid" 3 "Signal Invalid" 4 "Signal Invalid" 5 "Open" 6 "Signal Invalid" 7 "Signal Invalid" 8 "Signal Invalid" 9 "Signal Invalid" 10 "Signal Invalid" 11 "Signal Invalid" 12 "Signal Invalid" 13 "Signal Invalid" 14 "Signal Invalid" 15 "Default" ;
VAL_ 584 BDLFRResponseError 0 "no error" 1 "error" ;
VAL_ 584 NDoorFROutsideHandleFailure 0 "Default (No Failure)" 1 "EEPROM, ROM and DSP self-test" 2 "Magnetic field is too low" 3 "Magnetic field is too high" 4 "Overvoltage" 5 "Undervoltage" 6 "A/D converter clipping" 7 "Reserved" ;
VAL_ 584 NDoorFROutsideHandleStatus 0 "Trigger" 1 "Not trigger" ;
VAL_ 584 NDoorLatchFRFailure 0 "No Fault" 1 "Fault Code" 2 "Fault Code" 3 "Fault Code" 4 "Fault Code" 5 "Fault Code" 6 "Fault Code" 7 "Fault Code" 8 "Fault Code" 9 "Fault Code" 10 "Fault Code" 11 "Fault Code" 12 "Fault Code" 13 "Fault Code" 14 "Fault Code" 127 "Fault Code" ;
VAL_ 592 BMS_VCU_PTCOnOff_Req 0 "OFF" 1 "ON" ;
VAL_ 592 BMS_VCU_ValveOnOff_Req 0 "close" 1 "open" ;
VAL_ 592 BMS_PreHeatCoolReq 0 "Precondition OFF" 1 "Precondition Heating ON" 2 "Precondition Cooling ON" 3 "Invalid value" ;
VAL_ 593 NDoorRLVehicleLocked 0 "default (locked)" 2 "unlocked (inactive)" 3 "locked (full decouple)" ;
VAL_ 593 NDoorRLVehicleMoving 0 "default (in motion)" 1 "Reserved" 2 "static (inactive)" 3 "in motion (decouple external)" ;
VAL_ 593 NDoorRLOpenInvRequested 0 "default (release inactive)" 1 "Reserved" 2 "open (active release request)" 3 "close (release inactive)" ;
VAL_ 593 NDoorRLOpenRequested 0 "close (release inactive)" 1 "open (release request active)" 3 "default (release inactive)" ;
VAL_ 593 NDoorRLChildLocked 0 "default (locked)" 2 "unlocked (inactive)" 3 "locked (full decouple)" ;
VAL_ 593 NDoorRLVehicleCrash 0 "default (locked)" 2 "Not trigger (inactive)" 3 "Trigger (full decouple)" ;
VAL_ 593 NDoorRLCloseInvRequested 0 "Default (Cinch Latching Inactive)" 1 "Reserved" 2 "Open (Active Cinch Latching Request)" 3 "Close (Cinch Latching Inactive)" ;
VAL_ 593 NDoorRLCloseRequested 0 "Default (Cinch Latching Inactive)" 1 "Reserved" 2 "Open (Active Cinch Latching Request)" 3 "Close (Cinch Latching Inactive)" ;
VAL_ 596 QU_AVL_RPM_WHL_RLH 1 "Signal value is valid and secured and checked for plausibility" 2 "Reserved" 3 "Reserved" 4 "Substitute value is set in the useful signal" 6 "Signal value is invalid (Electrical fault, can be repaired)" 7 "Reserved" 8 "initialization" 9 "Reserved" 10 "Reserved" 11 "Signal quality or monitoring restricted, state / status temporary" 12 "Substitute value is set in the useful signal State / status temporary" 14 "Signal value is invalid (Electrical fault, can not repaired)" 15 "Signal invalid" ;
VAL_ 596 QU_AVL_RPM_WHL_RRH 1 "Signal value is valid and secured and checked for plausibility" 2 "Reserved" 3 "Reserved" 4 "Substitute value is set in the useful signal" 6 "Signal value is invalid (Electrical fault, can be repaired)" 7 "Reserved" 8 "initialization" 9 "Reserved" 10 "Reserved" 11 "Signal quality or monitoring restricted, state / status temporary" 12 "Substitute value is set in the useful signal State / status temporary" 14 "Signal value is invalid (Electrical fault, can not repaired)" 15 "Signal invalid" ;
VAL_ 597 QU_AVL_RPM_WHL_FLH 1 "Signal value is valid and secured and checked for plausibility" 2 "Reserved" 3 "Reserved" 4 "Substitute value is set in the useful signal" 6 "Signal value is invalid (Electrical fault, can be repaired)" 7 "Reserved" 8 "initialization" 9 "Reserved" 10 "Reserved" 11 "Signal quality or monitoring restricted, state / status temporary" 12 "Substitute value is set in the useful signal State / status temporary" 14 "Signal value is invalid (Electrical fault, can not repaired)" 15 "Signal invalid" ;
VAL_ 597 QU_AVL_RPM_WHL_FRH 1 "Signal value is valid and secured and checked for plausibility" 2 "Reserved" 3 "Reserved" 4 "Substitute value is set in the useful signal" 6 "Signal value is invalid (Electrical fault, can be repaired)" 7 "Reserved" 8 "initialization" 9 "Reserved" 10 "Reserved" 11 "Signal quality or monitoring restricted, state / status temporary" 12 "Substitute value is set in the useful signal State / status temporary" 14 "Signal value is invalid (Electrical fault, can not repaired)" 15 "Signal invalid" ;
VAL_ 598 BCM_Animation_Req 0 "not active" 1 "welcome mode1 request" 2 "welcome mode 2 request" 3 "welcome mode 3 request" 4 "shutdown mode 1 request" 5 "shutdowm mode 2 request" 6 "shutdowm mode 3 request" 7 "invalid" ;
VAL_ 598 BCM_Charging_Sts 0 "not plug-in" 1 "plug-in but not charging" 2 "plug-in and charging" 3 "charging error" 4 "reserved" 5 "reserved" 6 "reserved" 7 "invalid" ;
VAL_ 598 BCM_Lock_Sts 0 "unlocked" 1 "locked" 2 "reserved" 3 "invalid" ;
VAL_ 598 BCM_Panic_Status 0 "panic not active" 1 "panic active" ;
VAL_ 598 BCM_Charging_SOC 0 "0%-10%" 1 "10%-20%" 2 "20%-30%" 3 "30%-40%" 4 "40%-50%" 5 "50%-60%" 6 "60%-70%" 7 "70%-80%" 8 "80%-90%" 9 "90%-100%" 10 "100%" 11 "reserved" 12 "reserved" 13 "reserved" 14 "reserved" 15 "invalid" ;
VAL_ 598 BCM_LeftPosLmpSts 0 "Pos Left OFF" 1 "Pos Left ON" 2 "Fault (Reserved)" 3 "Signal Invalid" ;
VAL_ 598 BCM_RightPosLmpSts 0 "Pos Right OFF" 1 "Pos Right ON" 2 "Fault (Reserved)" 3 "Signal Invalid" ;
VAL_ 618 ST_ECU_ST_LCS_VEH 0 "Zustand Initialisierung" 1 "Zustand Normalbetrieb" 2 "Zustand Normalbetrieb/�berspannu" 3 "Zustand Normalbetrieb/Unterspann" 4 "Zustand Diagnose" 5 "Zustand Diagnose/�berspannung se" 6 "Zustand Diagnose/Unterspannung s" 7 "Zustand Powerdown" 8 "Zustand PowerSave" 9 "Zustand Nicht verf�gbar" 10 "Zustand Reset" 11 "Zustand Reserviert 11" 12 "Zustand Reserviert 12" 13 "Zustand Reserviert 13" 14 "Zustand Reserviert 14" 15 "Signal ung�ltig" ;
VAL_ 618 QU_FN_LCS_VEH 16533 "Signal invalid" ;
VAL_ 619 Sig_TgtVer_LR 1023 "Invalid" ;
VAL_ 620 Sig_SPVer_L 1 "AVAC safety position is requested for vertical stepper motor" 2 "AVAC safety freeze is requested for vertical stepper motor" 3 "AVAC stepper motor is quit" ;
VAL_ 620 Sig_SPVer_R 1 "AVAC safety position is requested for vertical stepper motor" 2 "AVAC safety freeze is requested for vertical stepper motor" 3 "AVAC stepper motor is quit" ;
VAL_ 620 Sig_RefVer_LR 0 "AVAC Referencing Request" ;
VAL_ 641 NDoorRLHomeSignal 0 "Home" 1 "not Home" ;
VAL_ 641 NDoorRLSecondarySignal 0 "Secondary" 1 "not Secondary" ;
VAL_ 641 NDoorRLPrimarySignal 0 "Primary" 1 "Not Primary" ;
VAL_ 641 NDoorRLClawSignal 0 "Claw" 1 "Not Claw" ;
VAL_ 641 NDoorRLClawStatus 0 "Closed" 1 "Secondary" 2 "Signal Invalid" 3 "Signal Invalid" 4 "Signal Invalid" 5 "Open" 6 "Signal Invalid" 7 "Signal Invalid" 8 "Signal Invalid" 9 "Signal Invalid" 10 "Signal Invalid" 11 "Signal Invalid" 12 "Signal Invalid" 13 "Signal Invalid" 14 "Signal Invalid" 15 "Default" ;
VAL_ 641 BDLRLResponseError 0 "no error" 1 "error" ;
VAL_ 641 NDoorRLOutsideHandleFailure 0 "Default (No Failure)" 1 "EEPROM, ROM and DSP self-test" 2 "Magnetic field is too low" 3 "Magnetic field is too high" 4 "Overvoltage" 5 "Undervoltage" 6 "A/D converter clipping" 7 "Reserved" ;
VAL_ 641 NDoorRLOutsideHandleStatus 0 "Trigger" 1 "Not trigger" ;
VAL_ 641 NDoorLatchRLFailure 0 "no fault" 1 "fault code" 2 "fault code" 3 "fault code" 4 "fault code" 5 "fault code" 6 "fault code" 63 "fault code" ;
VAL_ 649 AxOutStatus 0 "Valid" 1 "Invalid" ;
VAL_ 649 QU_VYAW_VEH 0 "Description for the value '0x0'" 1 "Description for the value '0x1'" ;
VAL_ 649 AyOutStatus 0 "Valid" 1 "Invalid" ;
VAL_ 649 AcceleratorY 16533 "Invalid" ;
VAL_ 649 AcceleratorX 16533 "Invalid" ;
VAL_ 654 Window_PosFL 0 "Closed (top)" 1 "Open (bottom)" 2 "Between 80% to closed" 3 "Between open to 80%" 4 "Reserved" 5 "Reserved" 6 "Reserved" 7 "Signal Invalid" ;
VAL_ 654 Window_Warning 0 "Not active" 1 "Active" 2 "Reserved" 3 "Signal Invalid" ;
VAL_ 654 Wndow_PosRL 0 "Closed (top)" 1 "Open (bottom)" 2 "Between 80% to closed" 3 "Between open to 80%" 4 "Reserved" 5 "Reserved" 6 "Reserved" 7 "Signal Invalid" ;
VAL_ 654 Window_PosFR 0 "Closed (top)" 1 "Open (bottom)" 2 "Between 80% to closed" 3 "Between open to 80%" 4 "Reserved" 5 "Reserved" 6 "Reserved" 7 "Signal Invalid" ;
VAL_ 654 Global_close 0 "Deactivated" 1 "Activated" 2 "Reserved" 3 "Signal Invalid" ;
VAL_ 654 Global_open 0 "Deactivated" 1 "Activated" 2 "Reserved" 3 "Signal Invalid" ;
VAL_ 654 Window_PosRR 0 "Closed (top)" 1 "Open (bottom)" 2 "Between 80% to closed" 3 "Between open to 80%" 4 "Reserved" 5 "Reserved" 6 "Reserved" 7 "Signal Invalid" ;
VAL_ 657 NDoorRRVehicleLocked 0 "Default (Locked)" 1 "Reserved" 2 "Unlocked (Inactive)" 3 "Locked (Full Decouple)" ;
VAL_ 657 NDoorRRVehicleMoving 0 "default (in motion)" 2 "static (inactive)" 3 "in motion (decouple external)" ;
VAL_ 657 NDoorRROpenInvRequested 0 "default (release inactive)" 2 "open (active release request)" 3 "close (release inactive)" ;
VAL_ 657 NDoorRROpenRequested 0 "close (release inactive)" 1 " open (release request active)" 2 "Reserved" 3 "default (release inactive)" ;
VAL_ 657 NDoorRRChildLocked 0 "default (locked)" 1 "Reserved" 2 " unlocked (inactive)" 3 " locked (full decouple)" ;
VAL_ 657 NDoorRRVehicleCrash 0 "default (locked)" 2 "Not trigger (inactive)" 3 "Trigger (full decouple)" ;
VAL_ 657 NDoorRRCloseInvRequested 0 "Default (Cinch Latching Inactive)" 1 "Reserved" 2 "Open (Active Cinch Latching Request)" 3 "Close (Cinch Latching Inactive)" ;
VAL_ 657 NDoorRRCloseRequested 0 "Close (Cinch latching Inactive)" 1 "Open (Cinch latching request active)" 2 "Reserved" 3 "Default (Cinch latching inactive)" ;
VAL_ 673 DrvSeatMsgStrLvl 0 "OFF" 1 "Initial value" 2 "Level 1(Weak)" 3 "Level 2(General)" 4 "Level 3(Strong)" 5 "Not used" 6 "Not used" 7 "Not used" ;
VAL_ 673 PassSeatMsgStrLvl 0 "OFF" 1 "Intial value" 2 "Level 1 (Weak)" 3 "Level 2 (General)" 4 "Level 3 (Strong)" 5 "Not used" 6 "Not used" 7 "Not used" ;
VAL_ 673 RearDrvSeatMsgStrLvl 0 "Invalid" 1 "Initial value" 2 "Level 1 (Weak)" 3 "Level 2 (General)" 4 "Level 3 (Strong)" 5 "Not used" 6 "Not used" 7 "Not used" ;
VAL_ 673 RearPassSeatMsgStrLvl 0 "OFF" 1 "Initial value" 2 "Level 1(Weak)" 3 "Level 2(General)" 4 "Level 3(Strong)" 5 "Not used" 6 "Not used" 7 "Not used" ;
VAL_ 673 DrvSeatMsgMode 0 "OFF" 1 "Wave Mode" 2 "Cat Paw Mode" 3 "Cross Mode" 4 "Relieve Mode" 5 "Jump Mode" 6 "Invalid" 7 "Not used" ;
VAL_ 673 PassSeatMsgMode 0 "OFF" 1 "Wave Mode" 2 "Cat Paw Mode" 3 "Cross Mode" 4 "Relieve Mode" 5 "Jump Mode" 6 "Invalid" 7 "Not used" ;
VAL_ 673 RearDrvSeatMsgMode 0 "OFF" 1 "Wave Mode" 2 "Cat Paw Mode" 3 "Cross Mode" 4 "Relieve Mode" 5 "Jump Mode" 6 "Invalid" 7 "Not used" ;
VAL_ 673 RearPassSeatMsgMode 0 "OFF" 1 "Wave mode" 2 "Cat Paw Mode" 3 "Cross Mode" 4 "Relieve Mode" 5 "Jump Mode" 6 "invalid" 7 "Not used" ;
VAL_ 674 DrvSeatMsgModeStat 0 "OFF" 1 "Wave Mode" 2 "Cat Paw Mode" 3 "Cross Mode" 4 "Relieve Mode" 5 "Jump Mode" 6 "Invalid" 7 "Not used" ;
VAL_ 674 PassSeatMsgModeStat 0 "OFF" 1 "Wave Mode" 2 "Cat Paw Mode" 3 "Cross Mode" 4 "Relieve Mode" 5 "Jump Mode" 6 "Invalid" 7 "Not used" ;
VAL_ 674 RearDrvSeatMsgModeStat 0 "OFF" 1 "Wave mode" 2 "Cat Paw Mode" 3 "Cross Mode" 4 "Relieve Mode" 5 "Jump Mode" 6 "invalid" 7 "Not used" ;
VAL_ 674 RearPassSeatMsgModeStat 0 "OFF" 1 "Wave mode" 2 "Cat Paw Mode" 3 "Cross Mode" 4 "Relieve Mode" 5 "Jump Mode" 6 "invalid" 7 "Not used" ;
VAL_ 674 LSSM_ALINResErr 0 "No Error" 1 "Error" ;
VAL_ 674 LSSM_APumpFail 0 "Invalid" 1 "No Error" 2 "Error" 3 "Reserved" ;
VAL_ 674 DrvSeatMsgStrLvlStat 0 "OFF" 1 "Initial value" 2 "Level 1(Weak)" 3 "Level 2(General)" 4 "Level 3(Strong)" 5 "Not used" 6 "Not used" 7 "Not used" ;
VAL_ 674 LSSM_BLINResErr 0 "No Error" 1 "Error" ;
VAL_ 674 LSSM_BPumpFail 0 "Invalid" 1 "No Error" 2 "Error" 3 "Reserved" ;
VAL_ 674 PassSeatMsgStrLvlStat 0 "Invalid" 1 "Initial value" 2 "Level 1 (Weak)" 3 "Level 2 (General)" 4 "Level 3 (Strong)" 5 "Not used" 6 "Not used" 7 "Not used" ;
VAL_ 674 LSSM_CLINResErr 0 "No Error" 1 "Error" ;
VAL_ 674 LSSM_CPumpFail 0 "Invalid" 1 "No Error" 2 "Error" 3 "Reserved" ;
VAL_ 674 RearDrvSeatMsgStrLvlStat 0 "Invalid" 1 "Initial value" 2 "Level 1 (Weak)" 3 "Level 2 (General)" 4 "Level 3 (Strong)" 5 "Not used" 6 "Not used" 7 "Not used" ;
VAL_ 674 LSSM_DLINResErr 0 "No Error" 1 "Error" ;
VAL_ 674 LSSM_DPumpFail 0 "Invalid" 1 "No Error" 2 "Error" 3 "Reserved" ;
VAL_ 674 RearPassSeatMsgStrLvlStat 0 "OFF" 1 "Initial value" 2 "Level 1(Weak)" 3 "Level 2(General)" 4 "Level 3(Strong)" 5 "Not used" 6 "Not used" 7 "Not used" ;
VAL_ 676 ECU_ID_WUPREG 255 "Signal invalid" ;
VAL_ 676 ID_FN_INQY 161 "Operation button Entertainment" 246 "Control exterior mirror" 426 "Effect ErgoCommander" 482 "Safe VIN" 525 "Position steering column" 550 "Rain sensor wiper speed" 570 "Status key" 594 "Wiper status" 615 "Operation pushbutton operating menu" 638 "Status soft top convertible" 742 "Status Climate Air distribution drivere" 746 "Status Climate Air distribution passenger" 748 "Status Climate " 750 "Status climate additional programs" 752 "Status Climate Stand functions" 759 "Unit" 760 "Time date" 768 "Status RSE" 783 "Status Service Call TeleX" 787 "Status Service Call Teleservice" 806 "Wirkungsgrad Information Data" 818 "Consumption information" 822 "Display checkcontrol message" 826 "Status Monitor Front" 828 "Status Monitor Rear 1" 830 "Status Monitor Rear 2" 833 "Status card data" 841 "Raw value fuel tank" 860 "Status Bordcomputer" 864 "Daten Bordcomputer 1" 896 "VIN" 897 "Electronic engine oil stick" 904 "vehicle type" 917 "Coding Powermanagement" 921 "Status M-Drive" 937 "Status ECM CKM" 939 "Status Shiftlights CKM" 950 "Position window regulator driver" 951 "Position window regulator driver rear" 952 "Position window regulator passenger" 953 "Position window regulator passenger rear" 954 "Position sliding roof" 956 "Position window lift sec" 959 "Position window lift tailgate" 960 "Configuration FAS" 961 "Configuration BFS" 962 "Configuration FASH" 963 "Configuration BFSH" 964 "Status EDCK CKM" 976 "Status lane departure warning system" 981 "Status cental lock" 983 "Status DWA CKM" 985 "Status RLS CKM" 987 "Status Memoryposition CKM" 989 "Status Light CKM" 991 "Status Climate CKM" 993 "Status ALC CKM" 995 "Status tailgateCKM" 1003 "Limits swing left" 1004 "Limits swing right" 1009 "Status light Extended  CKM" 1013 "Status of cargo compartment cover CKM" 1050 "Status Configuration IC 4" 1060 "Status Configuration IC" 1063 "Configuration DSC" 1070 "Status M-Drive 2" 1076 "Configuration EPS" 1077 "Measure engine oil" 1087 "Identification number Sensorcluster" 65535 "Signal invalid" ;
VAL_ 676 ID_FN_RQ_BUS 1 "Entertainment function" 2 "Remote Services" 3 "Residual heat function / burnout" 4 "Auxiliary heating/parking ventilation" 5 "Extension N-Holding Phase" 6 "Operation parking brake" 7 "Follow-up / connection RSE" 8 "Remote horn" 25 "Switch on / extension clamp" 43 "Alarm" 44 "EMF-button" 45 "roll monitoring" 46 "Requirement outside lighting" 47 "transhipment function" 51 "KL15Wup-Signal" 53 "Coolant temperature" 54 "IC display" 257 "switch on preventer" 258 "Wacke up " 259 "Switch OFF KL30F Stand time" 260 "Switch OFF KL30F CarSharing" 272 "OBD-Diagnostic" 273 "Exstension time water pump" 275 "Exstension time E-fan" 276 "Exstension time water pump additional Waterpumpe" 277 "Exstension time water pump hyb" 278 "Standl ventilation" 280 "Third-party charge detection hybrid / charging" 281 "Battery monitor  TSR" 288 "Leveling" 289 "Exstension time ventilation cooling" 304 "Trailer connection AAG" 305 "Req IK" 306 "Req IK OSFG" 513 "Domainmaster  ICE" 514 "Domainmaster elec motor" 515 "Domainmaster entertainment" 516 "Domainmaster body" 517 "Domainmaster Chasis" 769 "BDC Internal 30B Request inlight" 770 "BDC Internal 30B Request outlight" 771 "BDC Internal 30B Request FA-CAN " 772 "BDC Internal 30B Request Telesta" 773 "BDC Internal 30B Request Battery" 774 "CO2 Sensor" 65535 "Signal invalid" ;
VAL_ 676 NO_CC_MESS_STD 0 "No Error" 1 "Error(CurveBehavrestricted)" 2 "Error (Limited driving comfort)" ;
VAL_ 676 WACA 0 "ECU reset" 1 "Car alarm" 2 "Residual heat" 3 "CO2-recognition" 4 "CD/DVD Eject/CD/DVD insert" 5 "OFF switch light" 6 "Mirror" 7 "Remote Services" 8 "Emergency Call" 9 "CAS-Bus, button tailgate" 10 "CID-flap button" 11 "Smart Opener" 12 "Start charging" 14 "Switch for hitch" 16 "Door contact front driver" 17 "Door contact front passenger" 18 "Door contact front driver rear" 19 "Door contact front driver rear" 20 "Button driver door CA" 21 "Button passenger door CA" 22 "Button opener tailgate inner" 23 "Button opener tailgate" 24 "Button opener tailgate window" 25 "Tailgate contact" 26 "Input tailgate window" 27 "Bonnet" 28 "Unlock door lock / comfort opening" 29 "Lock door lock / comfort lock" 30 "Short circuit terminal 30 B" 32 "Start Stop button A" 33 "Start Stop button B" 34 "Hallsensor Eject" 35 "Center lock unlock" 36 "Park Automatic" 37 "Light swich ON" 38 "Hazard switch" 39 "Steering column switch to flash" 40 "Lenkstocktaster towards" 41 "Lenkstocktaster towards light" 42 "interior switch" 43 "Gear switch" 44 "EMF- Button" 45 "Entertainmen" 46 "Steering colunm adjustment switch" 47 "Regulation air spring" 48 "RKE" 49 "Wakeup-Signal TCU" 50 "Hotel switch" 51 "IBS" 52 "Parking heater / ventilate / climate" 53 "Coolant query by IC" 54 "Klemme 15 Wakeu line" 55 "Button Driver's door rear release" 56 "Button passenger door rear release" 57 "Button Driver's door" 58 "Button passenger door release" 59 "Button Driver's door rear release" 60 "Button passenger door rear release" 61 "Brake light switch" 62 "Clutch switch" 63 "Invalid wake-up reason, wake-up reason" 64 "Fog light" 65 "Rear fog light" 66 "Sarah- button" 67 "FES-button" 68 "PDC-button" 69 "Side-View-button" 70 "Rear spoiler-Taster" 71 "VDP-" 72 "MSA-button" 73 "Button audio volume steering wheel" 74 "Button special function" 75 "Button knurled steering wheel" 76 "Push-button telephone steering wheel" 77 "Push-button PTT steering wheel" 78 "Push-button seat heating driver" 79 "Push-button seat heating passenger" 80 "Push-button seat heating driver rear" 81 "Push-button seat heating passenger rear" 82 "Seat memory driver" 83 "Switch block door China long" 84 "Steering switch light" 85 "Door control unit" 88 "Car Sharing Modul" 89 "seat switch" 90 "AC control" 91 "PWF state change" 93 "Park light switch" 96 "Seat memory driver rear" 97 "Seat memory passenger" 98 "Seat memory pasenger rear" 99 "Nox-Diagnosis" 102 "Closing aid" 112 "Wake up" 255 "Signal invalid" ;
VAL_ 676 ST_CC_MESS_STD 0 "No Error" 1 "Error" ;
VAL_ 676 TRANF_CC_MESS_STD 0 "No Error" 1 "Error" ;
VAL_ 676 ST_IDC_CCLK_CC_MESS_STD 0 "No Error" 1 "Error" ;
VAL_ 714 MHU_STAT_CoolantLevelStatus 0 "Normal condition" 1 "Low level condition" 2 "Reserved" 3 "Signal Invalid" ;
VAL_ 720 FCAM_AESA_DoorUnlock_Req 0 "No request" 1 "Requested" ;
VAL_ 720 FCAM_AESA_ECALL_Req 0 "No request" 1 "Requested" ;
VAL_ 720 FCAM_AESA_Status 0 "Not active" 1 "Decelerating" 2 "Target following" 3 "Reserved" ;
VAL_ 753 MHU_STAT_AirbagWarnLamp 0 "Lamp off" 1 "Lamp on" 2 "Lamp failure" 3 "Signal invalid" ;
VAL_ 760 DISP_DATE_WDAY 1 "Monday" 2 "Tuesday" 3 "Wednesday" 4 "Thursday" 5 "Friday" 6 "Saturday" 7 "Sunday" 15 "Signal invalid" ;
VAL_ 760 ST_DISP_CTI_DATE 0 "data not valid" 1 "data valid" 3 "UTC" 5 "winter time" 6 "Manually set time" 7 "summer time" 15 "signal invalid" ;
VAL_ 768 CCU_STAT_SyncClimateZone 0 "OFF" 1 "ON" 2 "Reserved" 3 "Signal invalid" ;
VAL_ 768 CCU_STAT_Auto 0 "OFF" 1 "ON" 2 "Reserved" 3 "Signal invalid" ;
VAL_ 768 CCU_STAT_Aircondition 0 "OFF" 1 "ON" 2 "Reserved" 3 "Signal invalid" ;
VAL_ 768 CCU_STAT_IonButton 0 "OFF" 1 "ON" 2 "Reserved" 3 "Signal invalid" ;
VAL_ 768 CCU_STAT_MaxAc 0 "OFF" 1 "ON" 2 "Reserved" 3 "Signal invalid" ;
VAL_ 768 CCU_STAT_OnOff 0 "OFF" 1 "ON" 2 "Reserved" 3 "Signal invalid" ;
VAL_ 768 CCU_STAT_FanSpeed 0 "OFF" 1 "Level 1" 2 "Level 2" 3 "Level 3" 4 "Level 4" 5 "Level 5" 6 "Level 6" 7 "Reserved" 8 "Reserved" 9 "Reserved" 10 "Reserved" 11 "Reserved" 12 "Reserved" 13 "Reserved" 14 "Reserved" 15 "Signal invalid" ;
VAL_ 768 CCU_STAT_RecircFlap 0 "Inside" 1 "Outside" 2 "Auto" 3 "Signal invalid" ;
VAL_ 768 CCU_STAT_FlapPos 0 "OFF" 1 "Vent" 2 "Vent/Foot" 3 "Foot" 4 "Foot/Defrost" 5 "Defrost" 6 "Default" 7 "Signal invalid" ;
VAL_ 768 CCU_STAT_Defrost 0 "OFF" 1 "ON" 2 "Reserved" 3 "Signal invalid" ;
VAL_ 768 CCU_STAT_PTC_Heater 0 "OFF" 1 "Stage 1" 2 "Stage 2" 3 "Stage 3" 4 "Reserved" 5 "Reserved" 6 "Reserved" 7 "Signal invalid" ;
VAL_ 769 RP_Status 0 "Off" 1 "Standby" 2 "Enable" 3 "Active" 4 "Finished" 5 "Suspend" 6 "Abort" 7 "Failed";
VAL_ 773 CcuHtrOnOffSts 0 "HV PTC off / HV_PTC_OFF" 1 "HV PTC on / HV_PTC_ON" 2 "HV PTC degraded / HV_PTC_DEG" 3 "HV PTC stopped / HV_PTC_STOP" 4 "HV PTC shutdown / HV_PTC_SHUTDOWN" 5 "HV PTC shorted / HV_PTC_SHORTED" 6 "HV PTC reset not possible / HV_PTC_NO_RESET" 7 "SNA" ;
VAL_ 773 EcompOnOffSts 0 "Off" 1 "On" 2 "Reserved" 3 "Signal invalid" ;
VAL_ 774 CCU_EcompOnOffRequest 0 "Off" 1 "On" 2 "Reserved" 3 "Signal invalid" ;
VAL_ 774 CCU_HtrOnOffRequest 0 "Off" 1 "On" 2 "Reserved" 3 "Signal invalid" ;
VAL_ 775 OUT_Alert_TO_BCM 0 "Init" 1 "Warning level 1" 2 "Warning level 2" 3 "Warning level 3" 4 "Deactivate Warning" 5 "Invalid Value" ;
VAL_ 775 CPD_State_information 0 "Enable" 1 "Disable" 2 "Child Mode" 3 "Pet Mode" 4 "Reserved" 5 "Reserved" 6 "Reserved" 7 "Reserved" ;
VAL_ 784 CCUR_STAT_IonButton 0 "OFF" 1 "ON" 2 "Reserved" 3 "Signal invalid" ;
VAL_ 784 CCUR_STAT_Defrost 0 "OFF" 1 "ON" 2 "Reserved" 3 "Signal invalid" ;
VAL_ 784 CCUR_STAT_Auto 0 "OFF" 1 "ON" 2 "Reserved" 3 "Signal invalid" ;
VAL_ 784 CCUR_STAT_Aircondition 0 "OFF" 1 "ON" 2 "Reserved" 3 "Signal invalid" ;
VAL_ 784 CCUR_STAT_FlapPos 0 "OFF" 1 "Vent" 2 "Vent/Foot" 3 "Foot" 4 "Foot/Defrost" 5 "Defrost" 6 "Default" 7 "Signal invalid" ;
VAL_ 784 CCUR_STAT_FanSpeed 0 "OFF" 1 "Level 1" 2 "Level 2" 3 "Level 3" 4 "Level 4" 5 "Level 5" 6 "Level 6" 7 "Reserved" 8 "Reserved" 9 "Reserved" 10 "Reserved" 11 "Reserved" 12 "Reserved" 13 "Reserved" 14 "Reserved" 15 "Signal invalid" ;
VAL_ 784 CCUR_STAT_PTC_Heater 0 "OFF" 1 "Stage 1" 2 "Stage 2" 3 "Stage 3" 4 "Reserved" 5 "Reserved" 6 "Reserved" 7 "Signal invalid" ;
VAL_ 784 CCUR_STAT_OnOff 0 "OFF" 1 "ON" 2 "Reserved" 3 "Signal invalid" ;
VAL_ 784 CCUR_STAT_MaxAc 0 "OFF" 1 "ON" 2 "Reserved" 3 "Signal invalid" ;
VAL_ 784 CCUR_STAT_SyncClimateZone 0 "OFF" 1 "ON" 2 "Reserved" 3 "Signal invalid" ;
VAL_ 784 CCUR_STAT_RecircFlap 0 "Inside" 1 "Outside" 2 "Auto" 3 "Signal invalid" ;
VAL_ 806 POD_statusDCDC 0 "DCDC_OFF" 1 "DCDC_STANDBY" 2 "DCDC_ON" 3 "DCDC_RESERVED" 4 "DCDC_DEGRADED" 5 "DCDC_FAULT_SHUTDOWN" 6 "DCDC_EMERGENCY_SHUTDOWN" 7 "DCDC_STS_SNA";
VAL_ 812 QU_HGLV_RLH_EHC 1 "Signal value" 3 "Signal quality monitoring" 6 "Signal value not valid" 8 "Initialisierung" 21 "Signal invalid" ;
VAL_ 812 QU_HGLV_RRH_EHC 1 "Signal value valid" 3 "Signal quality monitoring" 6 "Signal value not valid" 8 "Init" 21 "Signal invalid" ;
VAL_ 814 ADAS_AEB_Braking_Progress 0 "No demand" 1 "Demand" ;
VAL_ 816 ST_FLLV_FUTA_SPAR 0 "No active" 1 "Active" 2 "Reserved" 3 "Signal invalid" ;
VAL_ 819 Rolling_Counter_0x333 15 "Invalid";
VAL_ 819 ADAS_RadarRight_Cal_Status 0 "No Calib" 1 "Calib OK";
VAL_ 819 ADAS_RadarLeft_Cal_Status 0 "No Calib" 1 "Calib OK";
VAL_ 819 ADAS_RadarRight_DynaCal_Status 0 "Calibration is in progress" 1 "The absolute value of calibration angle is greater than 6 degrees";
VAL_ 819 ADAS_MasterSRR_check 0 "Available" 1 "Temporarily not available" 2 "Permanently not available";
VAL_ 819 ADAS_SlaveSRR_check 0 "Available" 1 "Temporarily not available" 2 "Permanently not available";
VAL_ 819 ADAS_RadarLeft_DynaCal_Status 0 "Calibration is in progress" 1 "The absolute value of calibration angle is greater than 6 degrees";
VAL_ 819 ADAS_CalSensorMasterProgress 255 "Invaild";
VAL_ 819 ADAS_CalSensorSlaverProgress 255 "Invalid";
VAL_ 850 ADAS_AHB_check 0 "Available" 1 "Temporarily not available" 2 "Permanently not available";
VAL_ 850 ADAS_AHB_state 0 "OFF State" 1 "HighBeam Passive or Inactive" 2 "HighBeam Active" 3 "Fault";
VAL_ 850 ADAS_DOW_WarnRight 0 "No warning" 1 "Warning Level 1" 2 "Warning Level 2" 3 "Reserved";
VAL_ 850 ADAS_DOW_WarnLeft 0 "No warning" 1 "Warning Level 1" 2 "Warning Level 2" 3 "Reserved";
VAL_ 850 ADAS_AHB_RBPos 0 "Off or low beam" 1 "high beam" 2 "Reserved" 3 "Reserved" 4 "Reserved" 5 "Reserved" 6 "Reserved" 7 "SNA";
VAL_ 850 ADAS_AHB_LBPos 0 "Off or low beam" 1 "high beam" 2 "Reserved" 3 "Reserved" 4 "Reserved" 5 "Reserved" 6 "Reserved" 7 "SNA";
VAL_ 851 ADAS_ACC_State 0 "OFF State or Passive" 1 "Stand by state" 2 "Active" 3 "Override" 4 "Brake Only" 5 "Standstill Active" 6 "Standstill Wait" 7 "Fault";
VAL_ 851 ADAS_ACC_check 0 "Available" 1 "Temporarily not available" 2 "Permanently not available";
VAL_ 852 MHU_FCW_Mode 0 "OFF" 1 "ON" 2 "Reserve" 3 "Signal invalid";
VAL_ 852 MHU_FCW_sens 0 "Early" 1 "Normal" 2 "Late" 3 "Signal invalid";
VAL_ 852 MHU_AEB_Mode 0 "OFF" 1 "ON" 2 "Reserved" 3 "Signal invalid";
VAL_ 852 MHU_RAEB_Mode 0 "OFF" 1 "ON" 2 "Reserved" 3 "Signal invalid";
VAL_ 852 MHU_LA_sens 0 "Early" 1 "Normal" 2 "Late" 3 "Signal invalid";
VAL_ 852 MHU_LA_AudWarning 0 "OFF" 1 "ON" 2 "Reserved" 3 "Signal invalid";
VAL_ 852 MHU_BSD_On 0 "OFF" 1 "ON" 2 "Reserved" 3 "Signal invalid";
VAL_ 852 MHU_BSD_sens 0 "Early" 1 "Normal" 2 "Late" 3 "Signal invalid" ;
VAL_ 852 MHU_BSD_AudWarning 0 "OFF" 1 "ON" 2 "Reserved" 3 "Signal invalid";
VAL_ 852 MHU_RCTA_On 0 "OFF" 1 "ON" 2 "Reserved" 3 "Signal invalid";
VAL_ 852 MHU_RCTA_sens 0 "Early" 1 "Normal" 2 "Late" 3 "Signal invalid";
VAL_ 852 MHU_PA_On 0 "OFF" 1 "ON" 2 "Reserved" 3 "Signal invalid";
VAL_ 852 MHU_AHB_On 0 "OFF" 1 "ON" 2 "Reserved" 3 "Signal invalid";
VAL_ 852 MHU_IA_Mode 0 "OFF" 1 "ON" 2 "Reserved" 3 "Signal invalid";
VAL_ 852 MHU_TSR_Mode 0 "OFF" 1 "ON" 2 "Reserve" 3 "Signal invalid";
VAL_ 852 MHU_DOW_Mode 0 "OFF" 1 "Warning Only" 2 "Warning/Door Lock both" 3 "Signal invalid";
VAL_ 852 MHU_AHB_sens 0 "Early" 1 "Normal" 2 "Late" 3 "Signal invalid";
VAL_ 852 MHU_LA_Mode 0 "OFF" 1 "Warning only" 2 "Warning & Steer" 3 "Reserved" 4 "Signal Invalid";
VAL_ 852 MHU_SET_TSR_AudWarn 0 "OFF" 1 "ON" 2 "Reserved" 3 "Signal invalid";
VAL_ 852 MHU_SET_TSR_SLAert 0 "OFF" 1 "Speed Limit" 2 "Speed Limit + 5" 3 "Speed Limit + 10";
VAL_ 852 MHU_ESA_ON 0 "Off" 1 "On" ;
VAL_ 852 MHU_ELKA_ON 0 "OFF" 1 "ON" ;
VAL_ 880 SBR_STAT_Chime 0 "Off" 1 "Durable" 2 "Blinking 3Hz" 3 "SNA" ;
VAL_ 880 SBR_STAT_Telltale 0 "No chime" 1 "1 Hz" 2 "3 Hz" 3 "SNA" ;
VAL_ 880 SBR_STAT_Active 0 "Not active" 1 "Active" ;
VAL_ 886 USS_RPA_state 0 "OFF State" 1 "Standby state" 2 "Active State" 3 "Temporary Failed State" 4 "permanent Failed State" 5 "Reserved" 6 "Reserved" 7 "Invalid";
VAL_ 886 USS_RPA_AlertRLI 0 "No warning" 1 "Warning level 1" 2 "Warning level 2" 3 "Warning level 3" 4 "Warning level 4" 5 "Warning level 5" 6 "Reserved" 7 "Invalid";
VAL_ 886 USS_RPA_AlertRLO 0 "No warning" 1 "Warning level 1" 2 "Warning level 2" 3 "Warning level 3" 4 "Warning level 4" 5 "Warning level 5" 6 "Reserved" 7 "Invalid";
VAL_ 886 USS_RPA_AlertRRI 0 "No warning" 1 "Warning level 1" 2 "Warning level 2" 3 "Warning level 3" 4 "Warning level 4" 5 "Warning level 5" 6 "Reserved" 7 "Invalid";
VAL_ 886 USS_RPA_AlertRRO 0 "No warning" 1 "Warning level 1" 2 "Warning level 2" 3 "Warning level 3" 4 "Warning level 4" 5 "Warning level 5" 6 "Reserved" 7 "Invalid";
VAL_ 886 USS_RPA_SensorRLI 0 "Sensor Normal" 1 "Sensor Unavailable temporarily" 2 "Sensor Fault" 3 "Invalid" ;
VAL_ 886 USS_RPA_SensorRLO 0 "Sensor Normal" 1 "Sensor Unavailable temporarily" 2 "Sensor Fault" 3 "Invalid" ;
VAL_ 886 USS_RPA_SensorRRI 0 "Sensor Normal" 1 "Sensor Unavailable temporarily" 2 "Sensor Fault" 3 "Invalid" ;
VAL_ 886 USS_RPA_SensorRRO 0 "Sensor Normal" 1 "Sensor Unavailable temporarily" 2 "Sensor Fault" 3 "Invalid" ;
VAL_ 887 USS_FPA_state 0 "OFF State" 1 "Standby state" 2 "Active State" 3 "Temporary Failed State" 4 "permanent Failed State" 5 "Reserved" 6 "Reserved" 7 "Invalid";
VAL_ 887 USS_FPA_AutoOn_Feed 0 "OFF" 1 "ON" ;
VAL_ 887 USS_FPA_AlertFLI 0 "No warning" 1 "Warning level 1" 2 "Warning level 2" 3 "Warning level 3" 4 "Warning level 4" 5 "Warning level 5" 6 "Reserved" 7 "Invalid";
VAL_ 887 USS_FPA_AlertFLO 0 "No warning" 1 "Warning level 1" 2 "Warning level 2" 3 "Warning level 3" 4 "Warning level 4" 5 "Warning level 5" 6 "Reserved" 7 "Invalid";
VAL_ 887 USS_FPA_AlertFRI 0 "No warning" 1 "Warning level 1" 2 "Warning level 2" 3 "Warning level 3" 4 "Warning level 4" 5 "Warning level 5" 6 "Reserved" 7 "Invalid";
VAL_ 887 USS_FPA_AlertFRO 0 "No warning" 1 "Warning level 1" 2 "Warning level 2" 3 "Warning level 3" 4 "Warning level 4" 5 "Warning level 5" 6 "Reserved" 7 "Invalid";
VAL_ 887 USS_FPA_SensorFLI 0 "Sensor Normal" 1 "Sensor Unavailable temporarily" 2 "Sensor Fault" 3 "Invalid" ;
VAL_ 887 USS_FPA_SensorFLO 0 "Sensor Normal" 1 "Sensor Unavailable temporarily" 2 "Sensor Fault" 3 "Invalid" ;
VAL_ 887 USS_FPA_SensorFRI 0 "Sensor Normal" 1 "Sensor Unavailable temporarily" 2 "Sensor Fault" 3 "Invalid" ;
VAL_ 887 USS_FPA_SensorFRO 0 "Sensor Normal" 1 "Sensor Unavailable temporarily" 2 "Sensor Fault" 3 "Invalid" ;
